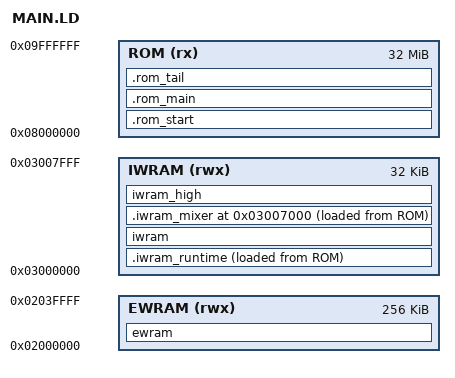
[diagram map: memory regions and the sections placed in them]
OUTPUT_ARCH(arm)
ENTRY(Entry_080003c0)
INCLUDE "games/THE BROKEN SEAL/CONSTANTS.LD"

MEMORY
{
    EWRAM (rwx) : ORIGIN = 0x2000000, LENGTH = 256K
    IWRAM (rwx) : ORIGIN = 0x3000000, LENGTH = 32K
    ROM    (rx) : ORIGIN = 0x8000000, LENGTH = 32M
}

SECTIONS
{
    ewram (NOLOAD) : { "*/recon/tbs/sym_ewram.o"(.sym_ewram) } > EWRAM
    .rom_start :
    {
        "*/recon/tbs/unidentified.o"(.unidentified.08000000)
        "*/games/THE BROKEN SEAL/SRC/SYSTEM/FAR_CALL/RUNTIME.o"(.text .rodata .data .padding)
        "*/games/THE BROKEN SEAL/SRC/SYSTEM/ENTRY.o"(.text .rodata .data .padding)
        "*/games/THE BROKEN SEAL/SRC/SOUND/DRIVER/RESAMPLER_KERNELS.o"(.text .rodata .data .padding)
        "*/games/THE BROKEN SEAL/SRC/SOUND/DRIVER/RESAMPLER_KERNELS_PAD.o"(.text .rodata .data .padding)
        "*/games/THE BROKEN SEAL/SRC/SOUND/DRIVER/RESAMPLER_KERNELS_1.o"(.text .rodata .data .padding)
        "*/games/THE BROKEN SEAL/SRC/SOUND/DRIVER/RESAMPLER_KERNELS_PAD_1.o"(.text .rodata .data .padding)
        "*/games/THE BROKEN SEAL/SRC/SOUND/DRIVER/RESAMPLER_KERNELS_2.o"(.text .rodata .data .padding)
        "*/games/THE BROKEN SEAL/SRC/SOUND/DRIVER/RESAMPLER_KERNELS_PAD_2.o"(.text .rodata .data .padding)
        "*/games/THE BROKEN SEAL/SRC/SOUND/DRIVER/CHANNEL_UPDATE_ENTRY.o"(.text .rodata .data .padding)
    } > ROM
    /* Startup copies this resident module bank to IWRAM with DMA3. */
    .iwram_runtime :
    {
        "*/games/THE BROKEN SEAL/SRC/SYSTEM/RUNTIME.o"(.text .rodata .data .padding)
        "*/games/THE BROKEN SEAL/SRC/SYSTEM/RUNTIME_IRQ_TABLE.o"(.text .rodata .data .padding)
        "*/games/THE BROKEN SEAL/SRC/SYSTEM/RUNTIME_MUL_Q16_IP.o"(.text .rodata .data .padding)
        "*/games/THE BROKEN SEAL/SRC/SYSTEM/RUNTIME_MUL_Q16.o"(.text .rodata .data .padding)
        "*/games/THE BROKEN SEAL/SRC/SYSTEM/RUNTIME_RATIO_Q14.o"(.text .rodata .data .padding)
        "*/games/THE BROKEN SEAL/SRC/SYSTEM/RUNTIME_MATH.o"(.text .rodata .data .padding)
        "*/games/THE BROKEN SEAL/SRC/SYSTEM/RUNTIME_TRANSFORM.o"(.text .rodata .data .padding)
        "*/games/THE BROKEN SEAL/SRC/SYSTEM/RUNTIME_MATRIX.o"(.text .rodata .data .padding)
        "*/games/THE BROKEN SEAL/SRC/SYSTEM/RUNTIME_DIVIDE.o"(.text .rodata .data .padding)
        "*/games/THE BROKEN SEAL/SRC/SYSTEM/RUNTIME_DECOMPRESS.o"(.text .rodata .data .padding)
        "*/games/THE BROKEN SEAL/SRC/SYSTEM/RUNTIME_MIX.o"(.text .rodata .data .padding)
        "*/games/THE BROKEN SEAL/SRC/SYSTEM/RUNTIME_MIX_STATE.o"(.text .rodata .data .padding)
        "*/games/THE BROKEN SEAL/SRC/SYSTEM/RUNTIME_MIX_INTERPOLATE.o"(.text .rodata .data .padding)
        "*/games/THE BROKEN SEAL/SRC/SYSTEM/RUNTIME_MIX_SAVE.o"(.text .rodata .data .padding)
        "*/games/THE BROKEN SEAL/SRC/SYSTEM/RUNTIME_MIX_CHANNEL.o"(.text .rodata .data .padding)
        "*/games/THE BROKEN SEAL/SRC/SYSTEM/RUNTIME_MIX_MASK.o"(.text .rodata .data .padding)
        "*/games/THE BROKEN SEAL/SRC/SYSTEM/RUNTIME_MIX_RENDER.o"(.text .rodata .data .padding)
        "*/games/THE BROKEN SEAL/SRC/SYSTEM/RUNTIME_MIX_WORKSPACE.o"(.text .rodata .data .padding)
        "*/games/THE BROKEN SEAL/SRC/SYSTEM/RUNTIME_COPY_WORDS.o"(.text .rodata .data .padding)
    } > IWRAM AT>ROM
    iwram (NOLOAD) : { "*/recon/tbs/sym_iwram.o"(.sym_iwram) } > IWRAM
    .rom_main :
    {
        "*/games/THE BROKEN SEAL/SRC/SYSTEM/RESOURCE/DECODE_BYTE_LZ.o"(.text .rodata .data .padding)
        "*/games/THE BROKEN SEAL/SRC/GRAPHICS/RENDER/BUILD_OAM_LIST.o"(.text .rodata .data .padding)
        "*/games/THE BROKEN SEAL/SRC/GRAPHICS/PALETTE/COLOR_BACKUP_KERNELS.o"(.text .rodata .data .padding)
        "*/games/THE BROKEN SEAL/SRC/GRAPHICS/PALETTE/COLOR_KERNELS.o"(.text .rodata .data .padding)
        "*/games/THE BROKEN SEAL/SRC/SYSTEM/RESOURCE/DECODE_HALFWORD_LZ.o"(.text .rodata .data .padding)
        "*/games/THE BROKEN SEAL/SRC/SYSTEM/IWRAM_ENTRY.o"(.text)
        "*/games/THE BROKEN SEAL/SRC/LIB/TRIG.o"(.text .rodata .data .padding)
        "*/games/THE BROKEN SEAL/SRC/LIB/SINE_TABLE.o"(.text .rodata .data .padding)
        "*/games/THE BROKEN SEAL/SRC/SYSTEM/RESOURCE/DECODE_01.o"(.text .rodata .data .padding)
        "*/games/THE BROKEN SEAL/SRC/SYSTEM/RESOURCE/DECODE_2.o"(.text .rodata .data .padding)
        "*/games/THE BROKEN SEAL/SRC/SYSTEM/RESOURCE/DECODE_2_NIBBLES.o"(.text .rodata .data .padding)
        "*/games/THE BROKEN SEAL/SRC/SYSTEM/RESOURCE/DECODE_2_LOOP.o"(.text .rodata .data .padding)
        "*/games/THE BROKEN SEAL/SRC/SYSTEM/RESOURCE/EXECUTE_TRANSFER.o"(.text .rodata .data .padding)
        "*/games/THE BROKEN SEAL/SRC/SYSTEM/RESOURCE/PATCH_THUMB_BRANCH.o"(.text .rodata .data .padding)
        "*/games/THE BROKEN SEAL/SRC/SYSTEM/MEMORY/RELEASE_HEAP_BLOCK.o"(.text .rodata .data .padding)
        "*/games/THE BROKEN SEAL/SRC/SYSTEM/INITIALIZE.o"(.text)
        "*/games/THE BROKEN SEAL/SRC/SYSTEM/SCHEDULER/IDLE_FOREVER.o"(.text)
        "*/games/THE BROKEN SEAL/SRC/SYSTEM/RESOURCE/RESOURCE.o"(.text)
        "*/recon/tbs/raw/0800300a.o"(.text .rodata .data .padding)
        "*/games/THE BROKEN SEAL/SRC/SYSTEM/INSTALL_IWRAM_AND_IRQS.o"(.text)
        "*/games/THE BROKEN SEAL/SRC/SYSTEM/SYSTEM.o"(.text)
        "*/games/THE BROKEN SEAL/SRC/SYSTEM/UPDATE_KEY_REPEAT_AND_DIRECTION.o"(.text)
        "*/games/THE BROKEN SEAL/SRC/SYSTEM/SYSTEM2.o"(.text)
        "*/games/THE BROKEN SEAL/SRC/SYSTEM/IO.o"(.text)
        "*/games/THE BROKEN SEAL/SRC/GRAPHICS/DISPLAY/DISPLAY3.o"(.text)
        "*/games/THE BROKEN SEAL/SRC/SYSTEM/SCHEDULER/SCHEDULER.o"(.text)
        "*/recon/tbs/raw/080046c2.o"(.text .rodata .data .padding)
        "*/games/THE BROKEN SEAL/SRC/DEBUG/DEBUG.o"(.text)
        "*/games/THE BROKEN SEAL/SRC/SYSTEM/MEMORY/MEMORY.o"(.text)
        "*/recon/tbs/raw/080049aa.o"(.text .rodata .data .padding)
        "*/games/THE BROKEN SEAL/SRC/GRAPHICS/RENDER/RENDER.o"(.text)
        "*/recon/tbs/raw/08004fe4.o"(.text .rodata .data .padding)
        "*/games/THE BROKEN SEAL/SRC/GRAPHICS/PALETTE/PALETTE8.o"(.text)
        "*/recon/tbs/raw/080056cc.o"(.text .rodata .data .padding)
        "*/recon/tbs/raw/0800580e.o"(.text .rodata .data .padding)
        "*/games/THE BROKEN SEAL/SRC/SYSTEM/SAVE/STATE.o"(.text)
        "*/recon/tbs/raw/08005d0e.o"(.text .rodata .data .padding)
        "*/games/THE BROKEN SEAL/SRC/SYSTEM/LINK/SERIAL_INITIALIZE.o"(.text)
        "*/recon/tbs/raw/08005e6e.o"(.text .rodata .data .padding)
        "*/games/THE BROKEN SEAL/SRC/SYSTEM/LINK/SIO_TIME.o"(.text)
        "*/recon/tbs/raw/08005ede.o"(.text .rodata .data .padding)
        "*/games/THE BROKEN SEAL/SRC/SYSTEM/LINK/SERIAL_POLL_AND_TRANSFER.o"(.text)
        "*/recon/tbs/raw/08005fca.o"(.text .rodata .data .padding)
        "*/games/THE BROKEN SEAL/SRC/SYSTEM/LINK/SERIAL_POLL_STATUS.o"(.text)
        "*/recon/tbs/raw/08006086.o"(.text .rodata .data .padding)
        "*/games/THE BROKEN SEAL/SRC/SYSTEM/LINK/SIO_XCHG.o"(.text)
        "*/recon/tbs/raw/0800615c.o"(.text .rodata .data .padding)
        "*/games/THE BROKEN SEAL/SRC/SYSTEM/LINK/SIO_INTR.o"(.text)
        "*/recon/tbs/raw/08006408.o"(.text .rodata .data .padding)
        "*/games/THE BROKEN SEAL/SRC/SYSTEM/LINK/LINK.o"(.text)
        "*/recon/tbs/raw/0800655c.o"(.text .rodata .data .padding)
        "*/games/THE BROKEN SEAL/SRC/SYSTEM/LINK/SERIAL_TEST.o"(.text)
        "*/games/THE BROKEN SEAL/SRC/SYSTEM/CPU_SET.o"(.text .rodata .data .padding)
        "*/recon/tbs/raw/0800686e.o"(.text .rodata .data .padding)
        "*/games/THE BROKEN SEAL/SRC/SYSTEM/SOUND_VSYNC_ON.o"(.text .rodata .data .padding)
        "*/recon/tbs/raw/08006876.o"(.text .rodata .data .padding)
        "*/games/COMMON/SRC/SYSTEM/SAVE/READ_FLASH_ID.o"(.text)
        "*/recon/tbs/raw/0800690e.o"(.text .rodata .data .padding)
        "*/games/COMMON/SRC/SYSTEM/SAVE/IDENTIFY_FLASH.o"(.text)
        "*/games/COMMON/SRC/SYSTEM/SAVE/FLASH_TIMER_INTERRUPT.o"(.text)
        "*/games/COMMON/SRC/SYSTEM/SAVE/START_FLASH_TIMER.o"(.text)
        "*/games/COMMON/SRC/SYSTEM/SAVE/FLASH_READ_ROUTINES.o"(.text)
        "*/games/COMMON/SRC/SYSTEM/SAVE/READ_FLASH_CORE.o"(.text)
        "*/recon/tbs/raw/08006ba6.o"(.text .rodata .data .padding)
        "*/games/COMMON/SRC/SYSTEM/SAVE/READ_FLASH.o"(.text)
        "*/games/COMMON/SRC/SYSTEM/SAVE/FLASH_VERIFY.o"(.text)
        "*/recon/tbs/raw/08006c66.o"(.text .rodata .data .padding)
        "*/games/COMMON/SRC/SYSTEM/SAVE/VERIFY_FLASH_SECTOR.o"(.text)
        "*/games/COMMON/SRC/SYSTEM/SAVE/ERASE_FLASH_CHIP.o"(.text)
        "*/games/COMMON/SRC/SYSTEM/SAVE/ERASE_FLASH_SECTOR.o"(.text)
        "*/games/COMMON/SRC/SYSTEM/SAVE/FLASH_PROGRAM_BYTE.o"(.text)
        "*/games/COMMON/SRC/SYSTEM/SAVE/PROGRAM_FLASH_SECTOR_WITH_ERASE_RETRY.o"(.text)
        "*/games/COMMON/SRC/SYSTEM/SAVE/FLASH_ERASE_VERIFY.o"(.text)
        "*/recon/tbs/raw/08006f6a.o"(.text .rodata .data .padding)
        "*/games/THE BROKEN SEAL/SRC/SYSTEM/SAVE/FLASH_VERIFY_CALLBACK.o"(.text)
        "*/games/COMMON/SRC/SYSTEM/SAVE/PROGRAM_FLASH_SECTOR.o"(.text)
        "*/games/COMMON/SRC/SYSTEM/SAVE/ERASE_ATMEL_FLASH_CHIP.o"(.text)
        "*/games/COMMON/SRC/SYSTEM/SAVE/ERASE_ATMEL_FLASH_SECTOR.o"(.text)
        "*/games/COMMON/SRC/SYSTEM/SAVE/ERASE_ATMEL_FLASH_BLOCK.o"(.text)
        "*/games/COMMON/SRC/SYSTEM/SAVE/PROGRAM_ATMEL_FLASH_SECTOR.o"(.text)
        "*/games/COMMON/SRC/SYSTEM/SAVE/PROGRAM_ATMEL_FLASH_BLOCK.o"(.text)
        "*libgcc.a:_call_via_rX.o"(.text)
        "*/recon/tbs/unidentified.o"(.unidentified.08007320)
        "*/games/THE BROKEN SEAL/SRC/LIB/Q16_DOT_PRODUCT.o"(.text .rodata .data .padding)
        "*/recon/tbs/unidentified.o"(.unidentified.080079b0)
        "*/games/COMMON/SRC/SYSTEM/SAVE/READ_FLASH_ID.o"(.rodata)
        "*/games/COMMON/SRC/SYSTEM/SAVE/IDENTIFY_FLASH.o"(.rodata)
        "*/games/COMMON/SRC/SYSTEM/SAVE/FLASH_TIMER_INTERRUPT.o"(.rodata)
        "*/games/COMMON/SRC/SYSTEM/SAVE/START_FLASH_TIMER.o"(.rodata)
        "*/games/COMMON/SRC/SYSTEM/SAVE/FLASH_READ_ROUTINES.o"(.rodata)
        "*/games/COMMON/SRC/SYSTEM/SAVE/READ_FLASH_CORE.o"(.rodata)
        "*/games/COMMON/SRC/SYSTEM/SAVE/FLASH_VERIFY.o"(.rodata)
        "*/games/COMMON/SRC/SYSTEM/SAVE/FLASH_ERASE_VERIFY.o"(.rodata)
        "*/games/THE BROKEN SEAL/SRC/SYSTEM/SAVE/FLASH_VERIFY_CALLBACK.o"(.rodata)
        "*/games/THE BROKEN SEAL/SRC/SYSTEM/SAVE/SAVE2.o"(.rodata)
        "*/games/THE BROKEN SEAL/SRC/SYSTEM/SAVE/SAVE3.o"(.rodata)
        "*/games/THE BROKEN SEAL/SRC/SYSTEM/SAVE/SAVE.o"(.rodata)
        "*/recon/tbs/unidentified.o"(.unidentified.08007a68)
        "*/games/COMMON/SRC/SYSTEM/SAVE/READ_FLASH.o"(.rodata)
        "*/games/COMMON/SRC/SYSTEM/SAVE/VERIFY_FLASH_SECTOR.o"(.rodata)
        "*/recon/tbs/unidentified.o"(.unidentified.08007aa4)
        "*/games/COMMON/SRC/SYSTEM/SAVE/ERASE_FLASH_CHIP.o"(.rodata)
        "*/games/COMMON/SRC/SYSTEM/SAVE/ERASE_FLASH_SECTOR.o"(.rodata)
        "*/games/COMMON/SRC/SYSTEM/SAVE/FLASH_PROGRAM_BYTE.o"(.rodata)
        "*/games/COMMON/SRC/SYSTEM/SAVE/PROGRAM_FLASH_SECTOR_WITH_ERASE_RETRY.o"(.rodata)
        "*/recon/tbs/unidentified.o"(.unidentified.08007b38)
        "*/games/COMMON/SRC/SYSTEM/SAVE/PROGRAM_FLASH_SECTOR.o"(.rodata)
        "*/recon/tbs/unidentified.o"(.unidentified.08007bcc)
        "*/games/COMMON/SRC/SYSTEM/SAVE/ERASE_ATMEL_FLASH_CHIP.o"(.rodata)
        "*/games/COMMON/SRC/SYSTEM/SAVE/ERASE_ATMEL_FLASH_SECTOR.o"(.rodata)
        "*/games/COMMON/SRC/SYSTEM/SAVE/ERASE_ATMEL_FLASH_BLOCK.o"(.rodata)
        "*/games/COMMON/SRC/SYSTEM/SAVE/PROGRAM_ATMEL_FLASH_SECTOR.o"(.rodata)
        "*/games/COMMON/SRC/SYSTEM/SAVE/PROGRAM_ATMEL_FLASH_BLOCK.o"(.rodata)
        "*/recon/tbs/unidentified.o"(.unidentified.08007c64)
        "*/games/THE BROKEN SEAL/SRC/SYSTEM/FAR_CALL/FIELD.o"(.text .rodata .data .padding)
        "*/recon/tbs/unidentified.o"(.unidentified.080092b8)
        "*/games/THE BROKEN SEAL/SRC/GRAPHICS/RENDER/DECODE.o"(.text .rodata .data .padding)
        "*/games/THE BROKEN SEAL/SRC/GRAPHICS/RENDER/DECODE_DATA.o"(.text .rodata .data .padding)
        "*/games/THE BROKEN SEAL/SRC/GRAPHICS/TILE/DRAW_MAP.o"(.text .rodata .data .padding)
        "*/recon/tbs/raw/0800a0f8.o"(.text .rodata .data .padding)
        "*/games/THE BROKEN SEAL/SRC/GRAPHICS/TILE/CONVERT_MAP.o"(.text .rodata .data .padding)
        "*/games/THE BROKEN SEAL/SRC/GRAPHICS/TILE/COPY_STRIDED.o"(.text .rodata .data .padding)
        "*/recon/tbs/raw/0800a494.o"(.text .rodata .data .padding)
        "*/games/THE BROKEN SEAL/SRC/SYSTEM/RESOURCE/DECOMPRESS_LZ.o"(.text)
        "*/recon/tbs/raw/0800aa0c.o"(.text .rodata .data .padding)
        "*/games/THE BROKEN SEAL/SRC/GRAPHICS/RENDER/PLACE_SPRITE_PART_PAIR.o"(.text)
        "*/recon/tbs/raw/0800b166.o"(.text .rodata .data .padding)
        "*/games/THE BROKEN SEAL/SRC/GRAPHICS/RENDER/PLACE_PROJECTED_SPRITE.o"(.text)
        "*/recon/tbs/raw/0800b682.o"(.text .rodata .data .padding)
        "*/games/THE BROKEN SEAL/SRC/FIELD/COMMON/OBJECT/GROUP_SET_CHILD_VALUE_UNLESS_FIFTEEN.o"(.text)
        "*/recon/tbs/raw/0800b6b8.o"(.text .rodata .data .padding)
        "*/games/THE BROKEN SEAL/SRC/SYSTEM/RESOURCE/RESOURCE3.o"(.text)
        "*/recon/tbs/raw/0800bc46.o"(.text .rodata .data .padding)
        "*/games/THE BROKEN SEAL/SRC/SYSTEM/RESOURCE/OBJECT.o"(.text)
        "*/games/COMMON/SRC/SYSTEM/RESOURCE/METADATA_SUM_COMMAND_LENGTHS.o"(.text)
        "*/recon/tbs/raw/0800be6e.o"(.text .rodata .data .padding)
        "*/games/THE BROKEN SEAL/SRC/FIELD/COMMON/MAP/MAP8.o"(.text)
        "*/games/THE BROKEN SEAL/SRC/FIELD/COMMON/OBJECT/OBJECT.o"(.text)
        "*/recon/tbs/raw/0800ca42.o"(.text .rodata .data .padding)
        "*/games/COMMON/SRC/FIELD/COMMON/SCRIPT/OPERANDS_CLEAR_BYTE54.o"(.text)
        "*/recon/tbs/raw/0800ca56.o"(.text .rodata .data .padding)
        "*/games/COMMON/SRC/FIELD/COMMON/SCRIPT/OPERANDS_SET_BYTE54.o"(.text)
        "*/recon/tbs/raw/0800ca6a.o"(.text .rodata .data .padding)
        "*/games/THE BROKEN SEAL/SRC/FIELD/COMMON/OBJECT/OBJECT13.o"(.text)
        "*/recon/tbs/raw/0800caca.o"(.text .rodata .data .padding)
        "*/recon/tbs/raw/0800cacc.o"(.text .rodata .data .padding)
        "*/games/COMMON/SRC/FIELD/COMMON/OBJECT/MOTION_SET_POSITION_AND_RESET_MOTION.o"(.text)
        "*/recon/tbs/raw/0800d14a.o"(.text .rodata .data .padding)
        "*/games/THE BROKEN SEAL/SRC/FIELD/COMMON/OBJECT/OBJECT14.o"(.text)
        "*/recon/tbs/raw/0800daf0.o"(.text .rodata .data .padding)
        "*/games/THE BROKEN SEAL/SRC/FIELD/COMMON/OBJECT/MOTION_AIM_APPROACH_LINKED_OBJECT.o"(.text)
        "*/recon/tbs/raw/0800dd70.o"(.text .rodata .data .padding)
        "*/recon/tbs/raw/0800df04.o"(.text .rodata .data .padding)
        "*/games/THE BROKEN SEAL/SRC/FIELD/COMMON/SCRIPT/SCRIPT.o"(.text)
        "*/recon/tbs/raw/0800ebec.o"(.text .rodata .data .padding)
        "*/games/THE BROKEN SEAL/SRC/FIELD/COMMON/FIELD.o"(.text)
        "*/games/COMMON/SRC/GRAPHICS/TILE/DECODE_STAGED_BUFFER.o"(.text)
        "*/games/THE BROKEN SEAL/SRC/GRAPHICS/TILE/TILE2.o"(.text)
        "*/recon/tbs/raw/0800fb38.o"(.text .rodata .data .padding)
        "*/games/THE BROKEN SEAL/SRC/FIELD/COMMON/MAP/MAP.o"(.text)
        "*/games/THE BROKEN SEAL/SRC/FIELD/COMMON/MAP/SET_CAMERA_CENTER.o"(.text)
        "*/recon/tbs/raw/08010424.o"(.text .rodata .data .padding)
        "*/recon/tbs/raw/08010560.o"(.text .rodata .data .padding)
        "*/recon/tbs/raw/080105d4.o"(.text .rodata .data .padding)
        "*/games/THE BROKEN SEAL/SRC/FIELD/COMMON/MAP/COPY_CELL_ATTRIBUTE_RECT.o"(.text)
        "*/recon/tbs/raw/08010788.o"(.text .rodata .data .padding)
        "*/games/THE BROKEN SEAL/SRC/FIELD/COMMON/MAP/SET_WORK_FLAG_BITS9_11.o"(.text)
        "*/recon/tbs/raw/080108e4.o"(.text .rodata .data .padding)
        "*/games/THE BROKEN SEAL/SRC/FIELD/COMMON/MAP/MAP6.o"(.text)
        "*/recon/tbs/raw/08010ff0.o"(.text .rodata .data .padding)
        "*/games/THE BROKEN SEAL/SRC/FIELD/WORLD_MAP/MAP4.o"(.text)
        "*/recon/tbs/raw/080113e4.o"(.text .rodata .data .padding)
        "*/recon/tbs/raw/080114a0.o"(.text .rodata .data .padding)
        "*/games/THE BROKEN SEAL/SRC/FIELD/COMMON/MAP/MAP2.o"(.text)
        "*/games/THE BROKEN SEAL/SRC/FIELD/COMMON/MAP/MAP3.o"(.text)
        "*/games/THE BROKEN SEAL/SRC/GRAPHICS/DISPLAY/DISPLAY4.o"(.text)
        "*/games/THE BROKEN SEAL/SRC/SYSTEM/SCHEDULER/SCHEDULE_CALLBACK_B_AFTER_FRAMES.o"(.text)
        "*/recon/tbs/raw/08011bf4.o"(.text .rodata .data .padding)
        "*/games/THE BROKEN SEAL/SRC/LIB/CURVE.o"(.text)
        "*/recon/tbs/raw/08011f52.o"(.text .rodata .data .padding)
        "*/recon/tbs/raw/08011f54.o"(.text .rodata .data .padding)
        "*/games/THE BROKEN SEAL/SRC/FIELD/COMMON/MAP/MAP4.o"(.text)
        "*/recon/tbs/raw/080120dc.o"(.text .rodata .data .padding)
        "*/games/THE BROKEN SEAL/SRC/FIELD/COMMON/MAP/MAP5.o"(.text)
        "*/recon/tbs/raw/08012518.o"(.text .rodata .data .padding)
        "*/games/THE BROKEN SEAL/SRC/GRAPHICS/TILE/FIND_NEXT_NUMBER_WITH_METADATA.o"(.text)
        "*/recon/tbs/raw/08012b2c.o"(.text .rodata .data .padding)
        "*/games/THE BROKEN SEAL/SRC/GRAPHICS/TILE/GRID_COLUMN.o"(.text)
        "*/games/THE BROKEN SEAL/SRC/BATTLE/PARTY/PLACE_ACTORS_BY_FORMATION_KIND.o"(.text)
        "*/recon/tbs/unidentified.o"(.unidentified.08012f20)
        "*/games/THE BROKEN SEAL/SRC/SYSTEM/FAR_CALL/WINDOW.o"(.text .rodata .data .padding)
        "*/games/THE BROKEN SEAL/SRC/GRAPHICS/TEXT/DECODE_SYMBOL.o"(.text .rodata .data .padding)
        "*/games/THE BROKEN SEAL/SRC/GRAPHICS/TEXT/LOOKUP_SYMBOL.o"(.text .rodata .data .padding)
        "*/recon/tbs/raw/080155d0.o"(.text .rodata .data .padding)
        "*/recon/tbs/raw/080158e8.o"(.text .rodata .data .padding)
        "*/games/THE BROKEN SEAL/SRC/GRAPHICS/TILE/DECOMPRESS_4BPP.o"(.text .rodata .data .padding)
        "*/games/THE BROKEN SEAL/SRC/GRAPHICS/TILE/DECOMPRESS_4BPP_NIBBLES.o"(.text .rodata .data .padding)
        "*/games/THE BROKEN SEAL/SRC/GRAPHICS/TILE/DECOMPRESS_4BPP_LOOP.o"(.text .rodata .data .padding)
        "*/games/THE BROKEN SEAL/SRC/GRAPHICS/TILE/EXPAND_MASKED.o"(.text .rodata .data .padding)
        "*/games/THE BROKEN SEAL/SRC/GRAPHICS/TILE/EXPAND_MASKED_MASKS.o"(.text .rodata .data .padding)
        "*/games/THE BROKEN SEAL/SRC/GRAPHICS/TILE/EXPAND_OPAQUE.o"(.text .rodata .data .padding)
        "*/games/THE BROKEN SEAL/SRC/GRAPHICS/TILE/EXPAND_OPAQUE_MASKS.o"(.text .rodata .data .padding)
        "*/games/THE BROKEN SEAL/SRC/GRAPHICS/RENDER/OUTPUT_ACQUIRE_FREE.o"(.text)
        "*/games/THE BROKEN SEAL/SRC/GRAPHICS/RENDER/RENDER5.o"(.text)
        "*/games/THE BROKEN SEAL/SRC/GRAPHICS/RENDER/UPLOAD_DIRTY_BLOCKS.o"(.text)
        "*/games/THE BROKEN SEAL/SRC/GRAPHICS/WINDOW/WINDOW.o"(.text)
        "*/recon/tbs/raw/080164d2.o"(.text .rodata .data .padding)
        "*/recon/tbs/raw/080164d4.o"(.text .rodata .data .padding)
        "*/games/THE BROKEN SEAL/SRC/GRAPHICS/RENDER/OUTPUT_LIST.o"(.text)
        "*/games/THE BROKEN SEAL/SRC/GRAPHICS/RENDER/RENDER3.o"(.text)
        "*/recon/tbs/raw/080167de.o"(.text .rodata .data .padding)
        "*/recon/tbs/raw/080167e0.o"(.text .rodata .data .padding)
        "*/games/THE BROKEN SEAL/SRC/GRAPHICS/WINDOW/RUNTIME_PROCESS_RENDER_CHANNELS.o"(.text)
        "*/recon/tbs/raw/080168f4.o"(.text .rodata .data .padding)
        "*/games/THE BROKEN SEAL/SRC/GRAPHICS/WINDOW/WINDOW2.o"(.text)
        "*/recon/tbs/raw/08017362.o"(.text .rodata .data .padding)
        "*/games/THE BROKEN SEAL/SRC/GRAPHICS/RENDER/IS_COMPLETE.o"(.text)
        "*/games/THE BROKEN SEAL/SRC/GRAPHICS/WINDOW/RUNTIME_COUNTERS.o"(.text)
        "*/games/THE BROKEN SEAL/SRC/GRAPHICS/TEXT/MESSAGE.o"(.text)
        "*/games/THE BROKEN SEAL/SRC/GRAPHICS/TEXT/TEXT4.o"(.text)
        "*/recon/tbs/raw/080178ae.o"(.text .rodata .data .padding)
        "*/games/THE BROKEN SEAL/SRC/GRAPHICS/TEXT/RENDER_GLYPH_PAIR.o"(.text)
        "*/games/COMMON/SRC/GRAPHICS/TEXT/GET_WIDE_STRING_WIDTH.o"(.text)
        "*/games/THE BROKEN SEAL/SRC/GRAPHICS/TEXT/RENDER_WIDE_STRING_AT_OFFSET.o"(.text)
        "*/games/THE BROKEN SEAL/SRC/GRAPHICS/TEXT/RENDER_GLYPH_TILE_AT_WORK_OFFSET.o"(.text)
        "*/recon/tbs/raw/08017c8a.o"(.text .rodata .data .padding)
        "*/games/THE BROKEN SEAL/SRC/GRAPHICS/TEXT/RENDER_WIDE_STRING_IN_WINDOW.o"(.text)
        "*/games/THE BROKEN SEAL/SRC/GRAPHICS/TEXT/FORMAT_NUMBER.o"(.text)
        "*/recon/tbs/raw/08018038.o"(.text .rodata .data .padding)
        "*/games/THE BROKEN SEAL/SRC/GRAPHICS/WINDOW/WINDOW3.o"(.text)
        "*/recon/tbs/raw/08018850.o"(.text .rodata .data .padding)
        "*/recon/tbs/raw/08018a50.o"(.text .rodata .data .padding)
        "*/recon/tbs/raw/08018cac.o"(.text .rodata .data .padding)
        "*/games/THE BROKEN SEAL/SRC/GRAPHICS/WINDOW/PUT_GLYPH.o"(.text)
        "*/games/THE BROKEN SEAL/SRC/GRAPHICS/WINDOW/SET_TILEMAP_ENTRY.o"(.text)
        "*/recon/tbs/raw/080191cc.o"(.text .rodata .data .padding)
        "*/games/COMMON/SRC/GRAPHICS/WINDOW/ADJUST_VALUE_WITHOUT_LIMIT.o"(.text)
        "*/games/THE BROKEN SEAL/SRC/GRAPHICS/TEXT/COPY_MESSAGE_STRING.o"(.text)
        "*/games/THE BROKEN SEAL/SRC/GRAPHICS/TEXT/DECODE_MESSAGE.o"(.text)
        "*/games/COMMON/SRC/SYSTEM/MEMORY/CLEAR_WORD_IF_SET.o"(.text)
        "*/games/THE BROKEN SEAL/SRC/GRAPHICS/WINDOW/WINDOW4.o"(.text)
        "*/games/THE BROKEN SEAL/SRC/GRAPHICS/TEXT/TEXT2.o"(.text)
        "*/recon/tbs/raw/08019bfc.o"(.text .rodata .data .padding)
        "*/games/THE BROKEN SEAL/SRC/GRAPHICS/WINDOW/WINDOW5.o"(.text)
        "*/games/THE BROKEN SEAL/SRC/GRAPHICS/WINDOW/RUNTIME_FINALIZE_ENTITY_MATCHING_LOCALIZED_ID.o"(.text)
        "*/games/THE BROKEN SEAL/SRC/GRAPHICS/RENDER/RENDER4.o"(.text)
        "*/recon/tbs/raw/08019fca.o"(.text .rodata .data .padding)
        "*/games/THE BROKEN SEAL/SRC/GRAPHICS/TILE/BUILD_ITEM_ICON_TILES.o"(.text)
        "*/recon/tbs/raw/0801a088.o"(.text .rodata .data .padding)
        "*/games/THE BROKEN SEAL/SRC/GRAPHICS/TILE/COPY_RESOURCE_TO_SLOT.o"(.text)
        "*/recon/tbs/raw/0801a2ea.o"(.text .rodata .data .padding)
        "*/games/THE BROKEN SEAL/SRC/GRAPHICS/RENDER/BUILD_PATTERN_TO_SLOT.o"(.text)
        "*/recon/tbs/raw/0801a32a.o"(.text .rodata .data .padding)
        "*/games/THE BROKEN SEAL/SRC/GRAPHICS/TILE/TILE.o"(.text)
        "*/recon/tbs/raw/0801a402.o"(.text .rodata .data .padding)
        "*/games/THE BROKEN SEAL/SRC/GRAPHICS/GLYPH/GLYPH.o"(.text)
        "*/recon/tbs/raw/0801a90e.o"(.text .rodata .data .padding)
        "*/games/THE BROKEN SEAL/SRC/SYSTEM/RESOURCE/FIND_FREE_TRANSFER_ENTRY.o"(.text)
        "*/recon/tbs/raw/0801a98c.o"(.text .rodata .data .padding)
        "*/games/THE BROKEN SEAL/SRC/MENU/MENU.o"(.text)
        "*/recon/tbs/raw/0801b248.o"(.text .rodata .data .padding)
        "*/games/THE BROKEN SEAL/SRC/MENU/MENU2.o"(.text)
        "*/recon/tbs/raw/0801ba68.o"(.text .rodata .data .padding)
        "*/games/THE BROKEN SEAL/SRC/SYSTEM/RESOURCE/RESOURCE2.o"(.text)
        "*/recon/tbs/raw/0801be80.o"(.text .rodata .data .padding)
        "*/games/THE BROKEN SEAL/SRC/GRAPHICS/TEXT/RESOURCE.o"(.text)
        "*/recon/tbs/raw/0801c186.o"(.text .rodata .data .padding)
        "*/games/THE BROKEN SEAL/SRC/MENU/MENU13.o"(.text)
        "*/recon/tbs/raw/0801c2e2.o"(.text .rodata .data .padding)
        "*/games/THE BROKEN SEAL/SRC/GRAPHICS/WINDOW/RUNTIME_CLOSE_AND_RELEASE.o"(.text)
        "*/recon/tbs/raw/0801c2ee.o"(.text .rodata .data .padding)
        "*/games/THE BROKEN SEAL/SRC/GRAPHICS/WINDOW/WINDOW6.o"(.text)
        "*/games/THE BROKEN SEAL/SRC/GAME/PARTY/ADJUST_BYTE205_BY_DIRECTION.o"(.text)
        "*/recon/tbs/raw/0801c49c.o"(.text .rodata .data .padding)
        "*/games/THE BROKEN SEAL/SRC/FIELD/COMMON/OBJECT/OBJECT2.o"(.text)
        "*/recon/tbs/raw/0801c92e.o"(.text .rodata .data .padding)
        "*/games/THE BROKEN SEAL/SRC/GRAPHICS/WINDOW/WINDOW11.o"(.text)
        "*/recon/tbs/raw/0801c9c6.o"(.text .rodata .data .padding)
        "*/games/THE BROKEN SEAL/SRC/GRAPHICS/PALETTE/PALETTE.o"(.text)
        "*/recon/tbs/raw/0801cf46.o"(.text .rodata .data .padding)
        "*/games/THE BROKEN SEAL/SRC/MENU/MENU14.o"(.text)
        "*/games/THE BROKEN SEAL/SRC/MENU/MENU15.o"(.text)
        "*/games/THE BROKEN SEAL/SRC/MENU/MENU3.o"(.text)
        "*/recon/tbs/raw/0801d9d4.o"(.text .rodata .data .padding)
        "*/games/THE BROKEN SEAL/SRC/MENU/RUN_WORKSPACE_SELECTION_LOOP.o"(.text)
        "*/recon/tbs/raw/0801dd28.o"(.text .rodata .data .padding)
        "*/recon/tbs/raw/0801de5c.o"(.text .rodata .data .padding)
        "*/games/THE BROKEN SEAL/SRC/GRAPHICS/WINDOW/CLEAR_TILE_ATTRIBUTES_IN_RECT.o"(.text)
        "*/games/THE BROKEN SEAL/SRC/GRAPHICS/WINDOW/WINDOW12.o"(.text)
        "*/recon/tbs/raw/0801e41a.o"(.text .rodata .data .padding)
        "*/games/THE BROKEN SEAL/SRC/GRAPHICS/WINDOW/WINDOW7.o"(.text)
        "*/games/THE BROKEN SEAL/SRC/GRAPHICS/TEXT/RENDER.o"(.text)
        "*/games/THE BROKEN SEAL/SRC/GRAPHICS/RENDER/OUTPUT.o"(.text)
        "*/recon/tbs/raw/0801ec6a.o"(.text .rodata .data .padding)
        "*/games/THE BROKEN SEAL/SRC/FIELD/COMMON/OBJECT/OBJECT8.o"(.text)
        "*/games/COMMON/SRC/GRAPHICS/WINDOW/RUNTIME_SET_BYTE5_AND_RESET_HALFWORD_C.o"(.text)
        "*/games/THE BROKEN SEAL/SRC/GRAPHICS/WINDOW/RUNTIME_SET_BYTE15_INVERTED.o"(.text)
        "*/recon/tbs/raw/0801edea.o"(.text .rodata .data .padding)
        "*/games/THE BROKEN SEAL/SRC/GRAPHICS/WINDOW/WINDOW15.o"(.text)
        "*/recon/tbs/raw/0801ef68.o"(.text .rodata .data .padding)
        "*/recon/tbs/raw/0801f088.o"(.text .rodata .data .padding)
        "*/recon/tbs/raw/0801f200.o"(.text .rodata .data .padding)
        "*/games/THE BROKEN SEAL/SRC/SYSTEM/SAVE/SAVE2.o"(.text)
        "*/games/THE BROKEN SEAL/SRC/SYSTEM/SAVE/SAVE3.o"(.text)
        "*/games/COMMON/SRC/GRAPHICS/PALETTE/GLOW_UPDATE_SINE.o"(.text)
        "*/games/THE BROKEN SEAL/SRC/GRAPHICS/WINDOW/WINDOW13.o"(.text)
        "*/recon/tbs/raw/0801fe2a.o"(.text .rodata .data .padding)
        "*/games/THE BROKEN SEAL/SRC/MENU/MENU4.o"(.text)
        "*/games/COMMON/SRC/GRAPHICS/TEXT/DRAW_FOUR_NUMBERS_IN_ROW.o"(.text)
        "*/games/COMMON/SRC/MENU/DRAW_CHARACTER_SUMMARY.o"(.text)
        "*/recon/tbs/raw/08020244.o"(.text .rodata .data .padding)
        "*/games/THE BROKEN SEAL/SRC/SYSTEM/SAVE/SAVE.o"(.text)
        "*/games/THE BROKEN SEAL/SRC/GRAPHICS/WINDOW/WINDOW14.o"(.text)
        "*/recon/tbs/raw/08020bd6.o"(.text .rodata .data .padding)
        "*/recon/tbs/raw/08020bd8.o"(.text .rodata .data .padding)
        "*/games/THE BROKEN SEAL/SRC/MENU/PARTY/TALK_CHOICE.o"(.text)
        "*/games/THE BROKEN SEAL/SRC/GAME/PARTY/LOOKUP_CHARACTER_VALUE_BY_FLAG32.o"(.text)
        "*/recon/tbs/raw/08021390.o"(.text .rodata .data .padding)
        "*/games/THE BROKEN SEAL/SRC/GRAPHICS/RENDER/LOAD_PAIR.o"(.text)
        "*/recon/tbs/raw/080216b2.o"(.text .rodata .data .padding)
        "*/games/THE BROKEN SEAL/SRC/GRAPHICS/WINDOW/WINDOW16.o"(.text)
        "*/recon/tbs/raw/08021bc6.o"(.text .rodata .data .padding)
        "*/games/COMMON/SRC/GRAPHICS/WINDOW/GET_TABLE_WORD_ZERO.o"(.text)
        "*/games/THE BROKEN SEAL/SRC/GRAPHICS/WINDOW/RUN_COPIED_ROUTINE.o"(.text)
        "*/games/COMMON/SRC/SYSTEM/LINK/CREATE_COUNTDOWN_LABEL_WINDOW.o"(.text)
        "*/games/THE BROKEN SEAL/SRC/GRAPHICS/TEXT/TEXT5.o"(.text)
        "*/recon/tbs/raw/08021dfa.o"(.text .rodata .data .padding)
        "*/games/THE BROKEN SEAL/SRC/GRAPHICS/DISPLAY/DISPLAY.o"(.text)
        "*/recon/tbs/raw/08021e6a.o"(.text .rodata .data .padding)
        "*/recon/tbs/raw/08021e6c.o"(.text .rodata .data .padding)
        "*/games/THE BROKEN SEAL/SRC/GRAPHICS/WINDOW/SET_RECT_HIGHLIGHT.o"(.text)
        "*/recon/tbs/raw/0802281c.o"(.text .rodata .data .padding)
        "*/games/THE BROKEN SEAL/SRC/MENU/MENU16.o"(.text)
        "*/games/COMMON/SRC/GRAPHICS/RENDER/CREATE_OUTPUT_FROM_RESOURCE_SLOT.o"(.text)
        "*/recon/tbs/raw/08022a7a.o"(.text .rodata .data .padding)
        "*/recon/tbs/raw/08022a7c.o"(.text .rodata .data .padding)
        "*/recon/tbs/raw/08022b44.o"(.text .rodata .data .padding)
        "*/recon/tbs/raw/08023178.o"(.text .rodata .data .padding)
        "*/recon/tbs/raw/08023e70.o"(.text .rodata .data .padding)
        "*/recon/tbs/raw/08024934.o"(.text .rodata .data .padding)
        "*/games/COMMON/SRC/GAME/ITEM/CLASSIFY_USE_ABILITY.o"(.text)
        "*/recon/tbs/raw/080251d2.o"(.text .rodata .data .padding)
        "*/games/THE BROKEN SEAL/SRC/GRAPHICS/DISPLAY/COPY_TILE.o"(.text)
        "*/recon/tbs/raw/08025200.o"(.text .rodata .data .padding)
        "*/recon/tbs/raw/0802592c.o"(.text .rodata .data .padding)
        "*/recon/tbs/raw/08026080.o"(.text .rodata .data .padding)
        "*/games/THE BROKEN SEAL/SRC/SYSTEM/LINK/LINK2.o"(.text)
        "*/games/COMMON/SRC/BATTLE/CLASSIFY_ENTRY_KIND.o"(.text)
        "*/recon/tbs/raw/080270aa.o"(.text .rodata .data .padding)
        "*/games/THE BROKEN SEAL/SRC/BATTLE/DRAW_PARTY_PANELS_WITH_EMPTY_LIST.o"(.text)
        "*/games/THE BROKEN SEAL/SRC/GRAPHICS/TEXT/DRAW_DRAW_LOCALIZED_RESOURCE.o"(.text)
        "*/recon/tbs/raw/08027114.o"(.text .rodata .data .padding)
        "*/recon/tbs/raw/08028194.o"(.text .rodata .data .padding)
        "*/games/THE BROKEN SEAL/SRC/MENU/MENU17.o"(.text)
        "*/games/THE BROKEN SEAL/SRC/MENU/MENU7.o"(.text)
        "*/games/THE BROKEN SEAL/SRC/MENU/SELECTION.o"(.text)
        "*/games/THE BROKEN SEAL/SRC/MENU/SELECT_RESOURCE_LAYOUT.o"(.text)
        "*/games/THE BROKEN SEAL/SRC/MENU/CONFIRM_SELECTION.o"(.text)
        "*/games/COMMON/SRC/MENU/SELECT_ENTRY_20_TO_21.o"(.text)
        "*/recon/tbs/raw/08028eda.o"(.text .rodata .data .padding)
        "*/games/THE BROKEN SEAL/SRC/MENU/MENU11.o"(.text)
        "*/games/COMMON/SRC/MENU/RUN_SELECTION_WITH_CURSOR_OBJECT.o"(.text)
        "*/recon/tbs/raw/08029272.o"(.text .rodata .data .padding)
        "*/games/COMMON/SRC/GRAPHICS/TEXT/FORMAT_HEX.o"(.text)
        "*/games/THE BROKEN SEAL/SRC/MENU/MENU5.o"(.text)
        "*/recon/tbs/raw/080294d2.o"(.text .rodata .data .padding)
        "*/games/THE BROKEN SEAL/SRC/GAME/DJINN/SET_FOUND_FLAG_AND_ADD.o"(.text)
        "*/recon/tbs/raw/08029502.o"(.text .rodata .data .padding)
        "*/games/THE BROKEN SEAL/SRC/MENU/RUN_WORKSPACE_RESULT_LOOP.o"(.text)
        "*/recon/tbs/raw/08029554.o"(.text .rodata .data .padding)
        "*/recon/tbs/raw/0802977c.o"(.text .rodata .data .padding)
        "*/recon/tbs/unidentified.o"(.unidentified.08029910)
        "*/games/COMMON/SRC/GRAPHICS/FONT/TEXT.o"(.rodata)
        "*/recon/tbs/unidentified.o"(.unidentified.08033e24)
        "*/games/THE BROKEN SEAL/TEXT/MESSAGES.o"(.rodata)
        "*/recon/tbs/unidentified.o"(.unidentified.08073808)
        "*/games/THE BROKEN SEAL/SRC/SYSTEM/FAR_CALL/GAME.o"(.text .rodata .data .padding)
        "*/games/THE BROKEN SEAL/SRC/GAME/CHARACTER/CHARACTER.o"(.text)
        "*/recon/tbs/raw/08077d38.o"(.text .rodata .data .padding)
        "*/games/THE BROKEN SEAL/SRC/GAME/PARTY/PARTY2.o"(.text)
        "*/games/COMMON/SRC/GAME/CHARACTER/RATIOS_SECOND_INPUT.o"(.text)
        "*/recon/tbs/raw/080783a2.o"(.text .rodata .data .padding)
        "*/games/THE BROKEN SEAL/SRC/GAME/CHARACTER/VALUES.o"(.text)
        "*/recon/tbs/raw/08078412.o"(.text .rodata .data .padding)
        "*/games/COMMON/SRC/GAME/ITEM/DEFINITION.o"(.text)
        "*/recon/tbs/raw/0807847e.o"(.text .rodata .data .padding)
        "*/games/THE BROKEN SEAL/SRC/GAME/ITEM/GET_EQUIPMENT_GROUP.o"(.text)
        "*/recon/tbs/raw/080784ae.o"(.text .rodata .data .padding)
        "*/games/THE BROKEN SEAL/SRC/GAME/INVENTORY/INVENT2.o"(.text)
        "*/recon/tbs/raw/08078bf0.o"(.text .rodata .data .padding)
        "*/games/THE BROKEN SEAL/SRC/GAME/CHARACTER/RECORD.o"(.text)
        "*/games/THE BROKEN SEAL/SRC/GAME/CHARACTER/CHARACTER2.o"(.text)
        "*/games/COMMON/SRC/GAME/PARTY/ADVANCE_OWNER_COUNT_TO_TARGET.o"(.text)
        "*/games/THE BROKEN SEAL/SRC/GAME/FLAGS/TEST.o"(.text)
        "*/recon/tbs/raw/08079460.o"(.text .rodata .data .padding)
        "*/games/THE BROKEN SEAL/SRC/GAME/CHARACTER/CHARACTER3.o"(.text)
        "*/recon/tbs/raw/08079b24.o"(.text .rodata .data .padding)
        "*/games/THE BROKEN SEAL/SRC/BATTLE/RANDOM16.o"(.text)
        "*/recon/tbs/raw/08079d1a.o"(.text .rodata .data .padding)
        "*/games/THE BROKEN SEAL/SRC/GAME/DJINN/DJINN.o"(.text)
        "*/recon/tbs/raw/0807a626.o"(.text .rodata .data .padding)
        "*/games/THE BROKEN SEAL/SRC/GAME/INVENTORY/ADD_AND_EQUIP.o"(.text)
        "*/recon/tbs/raw/0807a664.o"(.text .rodata .data .padding)
        "*/games/THE BROKEN SEAL/SRC/GAME/INVENTORY/RESTORE_SNAPSHOT.o"(.text)
        "*/recon/tbs/unidentified.o"(.unidentified.0807a828)
        "*/games/THE BROKEN SEAL/SRC/SYSTEM/FAR_CALL/OBJECT.o"(.text .rodata .data .padding)
        "*/games/THE BROKEN SEAL/SRC/FIELD/COMMON/MAP/SELECT_GROUP_ENTRY.o"(.text)
        "*/recon/tbs/raw/0808a6e4.o"(.text .rodata .data .padding)
        "*/games/THE BROKEN SEAL/SRC/BATTLE/EFFECT/DATA_GET_RESOURCE_GROUP.o"(.text)
        "*/recon/tbs/raw/0808a8e4.o"(.text .rodata .data .padding)
        "*/games/THE BROKEN SEAL/SRC/BATTLE/EFFECT/DATA_LOAD_RESOURCE_GROUP.o"(.text)
        "*/games/THE BROKEN SEAL/SRC/FIELD/COMMON/FIELD4.o"(.text)
        "*/games/THE BROKEN SEAL/SRC/BATTLE/EFFECT/EFFECT24.o"(.text)
        "*/games/THE BROKEN SEAL/SRC/BATTLE/EFFECT/DATA_LOOKUP_ROUTINES.o"(.text)
        "*/games/THE BROKEN SEAL/SRC/GAME/PARTY/RESOLVE_TABLE_PAIR.o"(.text)
        "*/games/THE BROKEN SEAL/SRC/FIELD/COMMON/EVENT/GET_SPECIAL_VALUE.o"(.text)
        "*/games/THE BROKEN SEAL/SRC/BATTLE/EFFECT/EFFECT25.o"(.text)
        "*/recon/tbs/raw/0808b3ea.o"(.text .rodata .data .padding)
        "*/recon/tbs/raw/0808b3ec.o"(.text .rodata .data .padding)
        "*/games/THE BROKEN SEAL/SRC/FIELD/COMMON/OBJECT/OBJECT3.o"(.text)
        "*/games/THE BROKEN SEAL/SRC/BATTLE/EFFECT/EFFECT26.o"(.text)
        "*/games/THE BROKEN SEAL/SRC/FIELD/COMMON/OBJECT/OBJECT5.o"(.text)
        "*/recon/tbs/raw/0808bb2c.o"(.text .rodata .data .padding)
        "*/games/THE BROKEN SEAL/SRC/FIELD/COMMON/FIELD5.o"(.text)
        "*/games/THE BROKEN SEAL/SRC/BATTLE/PARTY/PARTY3.o"(.text)
        "*/recon/tbs/raw/0808c4f8.o"(.text .rodata .data .padding)
        "*/games/THE BROKEN SEAL/SRC/FIELD/COMMON/OBJECT/GET_TRIGGER_TILE_AHEAD_OF_CURRENT.o"(.text)
        "*/games/THE BROKEN SEAL/SRC/DEBUG/DEBUG2.o"(.text)
        "*/games/THE BROKEN SEAL/SRC/BATTLE/EFFECT/EFFECT27.o"(.text)
        "*/recon/tbs/raw/0808d9a4.o"(.text .rodata .data .padding)
        "*/games/THE BROKEN SEAL/SRC/BATTLE/EFFECT/EFFECT11.o"(.text)
        "*/recon/tbs/raw/0808e0ae.o"(.text .rodata .data .padding)
        "*/games/THE BROKEN SEAL/SRC/BATTLE/BATTLE6.o"(.text)
        "*/games/THE BROKEN SEAL/SRC/BATTLE/BATTLE7.o"(.text)
        "*/games/THE BROKEN SEAL/SRC/FIELD/COMMON/EFFECT/SLOTS.o"(.text)
        "*/recon/tbs/raw/0808ee0c.o"(.text .rodata .data .padding)
        "*/games/THE BROKEN SEAL/SRC/BATTLE/EFFECT/EFFECT28.o"(.text)
        "*/games/THE BROKEN SEAL/SRC/BATTLE/EFFECT/RANDOM_PARTICLE_SPAWN_AT_POSITION.o"(.text)
        "*/games/THE BROKEN SEAL/SRC/FIELD/COMMON/EFFECT/EFFECT.o"(.text)
        "*/recon/tbs/raw/0808f52c.o"(.text .rodata .data .padding)
        "*/games/THE BROKEN SEAL/SRC/GRAPHICS/DISPLAY/DISPLAY2.o"(.text)
        "*/recon/tbs/raw/0808fefc.o"(.text .rodata .data .padding)
        "*/games/THE BROKEN SEAL/SRC/GRAPHICS/DISPLAY/DISPLAY7.o"(.text)
        "*/recon/tbs/raw/08090582.o"(.text .rodata .data .padding)
        "*/games/THE BROKEN SEAL/SRC/GRAPHICS/DISPLAY/TRANSITION_UPDATE_SCANLINE.o"(.text)
        "*/games/THE BROKEN SEAL/SRC/GRAPHICS/PALETTE/PALETTE5.o"(.text)
        "*/recon/tbs/raw/08090a5c.o"(.text .rodata .data .padding)
        "*/games/THE BROKEN SEAL/SRC/BATTLE/EFFECT/EFFECT12.o"(.text)
        "*/recon/tbs/raw/080912b8.o"(.text .rodata .data .padding)
        "*/games/THE BROKEN SEAL/SRC/BATTLE/EFFECT/START_FADE_OVERLAY.o"(.text)
        "*/games/THE BROKEN SEAL/SRC/BATTLE/EFFECT/SETUP.o"(.text)
        "*/games/THE BROKEN SEAL/SRC/FIELD/COMMON/EVENT/EVENT.o"(.text)
        "*/games/THE BROKEN SEAL/SRC/GAME/PARTY/REMOVE_OWNER_RESTORED.o"(.text)
        "*/games/THE BROKEN SEAL/SRC/GAME/PARTY/CHECK_MEMBER_VALUE_TOTAL.o"(.text)
        "*/games/COMMON/SRC/GAME/INVENTORY/TRY_ADD_AND_RETURN_OWNER.o"(.text)
        "*/games/THE BROKEN SEAL/SRC/GAME/INVENTORY/INVENT.o"(.text)
        "*/games/COMMON/SRC/GRAPHICS/TEXT/DRAW_DRAW_QUANTITY_PAIR_WITH_CUE.o"(.text)
        "*/games/THE BROKEN SEAL/SRC/FIELD/COMMON/EVENT/EVENT2.o"(.text)
        "*/games/THE BROKEN SEAL/SRC/BATTLE/EFFECT/RESULT_REQUEST.o"(.text)
        "*/games/THE BROKEN SEAL/SRC/GAME/PARTY/SET_FIELDS_1CE_1D0.o"(.text)
        "*/games/THE BROKEN SEAL/SRC/FIELD/COMMON/EVENT/CELL_PAIRS.o"(.text)
        "*/games/THE BROKEN SEAL/SRC/FIELD/COMMON/OBJECT/OBJECT16.o"(.text)
        "*/games/THE BROKEN SEAL/SRC/FIELD/COMMON/OBJECT/OBJECT4.o"(.text)
        "*/games/THE BROKEN SEAL/SRC/FIELD/COMMON/OBJECT/OBJECT6.o"(.text)
        "*/recon/tbs/raw/08092b92.o"(.text .rodata .data .padding)
        "*/games/THE BROKEN SEAL/SRC/FIELD/COMMON/OBJECT/OBJECT9.o"(.text)
        "*/recon/tbs/raw/08092c40.o"(.text .rodata .data .padding)
        "*/games/THE BROKEN SEAL/SRC/BATTLE/PRESENTATION/RUN_ACTION_AND_WAIT.o"(.text)
        "*/games/THE BROKEN SEAL/SRC/BATTLE/BATTLE8.o"(.text)
        "*/recon/tbs/raw/080930ba.o"(.text .rodata .data .padding)
        "*/games/THE BROKEN SEAL/SRC/FIELD/COMMON/FIELD3.o"(.text)
        "*/recon/tbs/raw/08093166.o"(.text .rodata .data .padding)
        "*/games/THE BROKEN SEAL/SRC/FIELD/COMMON/EVENT/SHOW_VALUE_1D8_AT_POSITION.o"(.text)
        "*/games/COMMON/SRC/FIELD/COMMON/OBJECT/TABLE_RUN_IF_ACTIVE.o"(.text)
        "*/recon/tbs/raw/080931ea.o"(.text .rodata .data .padding)
        "*/games/THE BROKEN SEAL/SRC/BATTLE/BATTLE9.o"(.text)
        "*/games/THE BROKEN SEAL/SRC/FIELD/COMMON/OBJECT/ATTACH_WORK_TARGET_TO_OBJECT.o"(.text)
        "*/games/THE BROKEN SEAL/SRC/BATTLE/EFFECT/EFFECT29.o"(.text)
        "*/recon/tbs/raw/08093872.o"(.text .rodata .data .padding)
        "*/games/THE BROKEN SEAL/SRC/FIELD/COMMON/OBJECT/OBJECT17.o"(.text)
        "*/games/THE BROKEN SEAL/SRC/FIELD/COMMON/FIELD6.o"(.text)
        "*/recon/tbs/raw/08093fa0.o"(.text .rodata .data .padding)
        "*/games/THE BROKEN SEAL/SRC/FIELD/COMMON/OBJECT/OBJECT7.o"(.text)
        "*/recon/tbs/raw/080941de.o"(.text .rodata .data .padding)
        "*/recon/tbs/raw/080941e0.o"(.text .rodata .data .padding)
        "*/games/THE BROKEN SEAL/SRC/FIELD/COMMON/OBJECT/OBJECT10.o"(.text)
        "*/recon/tbs/raw/08094544.o"(.text .rodata .data .padding)
        "*/games/THE BROKEN SEAL/SRC/GRAPHICS/DISPLAY/SCROLL_INITIALIZE_HBLANK_DMA.o"(.text)
        "*/games/THE BROKEN SEAL/SRC/GRAPHICS/DISPLAY/SCROLL_DISARM_HBLANK_DMA.o"(.text)
        "*/recon/tbs/raw/08094820.o"(.text .rodata .data .padding)
        "*/games/THE BROKEN SEAL/SRC/BATTLE/EFFECT/STORM_FLASH.o"(.text)
        "*/recon/tbs/raw/08094ac8.o"(.text .rodata .data .padding)
        "*/recon/tbs/raw/08094bbc.o"(.text .rodata .data .padding)
        "*/games/THE BROKEN SEAL/SRC/FIELD/COMMON/EFFECT/EFFECT2.o"(.text)
        "*/games/COMMON/SRC/FIELD/COMMON/OBJECT/MOTION_MOVE_HALFWAY_TOWARD_TARGET.o"(.text)
        "*/games/THE BROKEN SEAL/SRC/BATTLE/EFFECT/EFFECT31.o"(.text)
        "*/games/THE BROKEN SEAL/SRC/BATTLE/EFFECT/EFFECT32.o"(.text)
        "*/games/THE BROKEN SEAL/SRC/BATTLE/EFFECT/HEAVY_IMPACT_FINISH.o"(.text)
        "*/games/THE BROKEN SEAL/SRC/BATTLE/EFFECT/EFFECT33.o"(.text)
        "*/games/THE BROKEN SEAL/SRC/BATTLE/EFFECT/RUN_MERCURY_DJINN_CAPTURE.o"(.text)
        "*/games/COMMON/SRC/FIELD/COMMON/DISPATCH_TYPE_HANDLER.o"(.text)
        "*/games/THE BROKEN SEAL/SRC/BATTLE/EFFECT/EFFECT.o"(.text)
        "*/recon/tbs/raw/08096c22.o"(.text .rodata .data .padding)
        "*/games/THE BROKEN SEAL/SRC/FIELD/COMMON/OBJECT/OBJECT11.o"(.text)
        "*/recon/tbs/raw/08096c7e.o"(.text .rodata .data .padding)
        "*/games/THE BROKEN SEAL/SRC/BATTLE/EFFECT/EFFECT34.o"(.text)
        "*/games/THE BROKEN SEAL/SRC/BATTLE/EFFECT/EFFECT35.o"(.text)
        "*/games/THE BROKEN SEAL/SRC/BATTLE/EFFECT/EFFECT36.o"(.text)
        "*/games/THE BROKEN SEAL/SRC/BATTLE/EFFECT/FINISH_SCENE_AND_RELEASE_HEAP_BLOCK.o"(.text)
        "*/recon/tbs/raw/08097644.o"(.text .rodata .data .padding)
        "*/games/THE BROKEN SEAL/SRC/BATTLE/EFFECT/ARM_BG0_HBLANK_DMA.o"(.text)
        "*/games/THE BROKEN SEAL/SRC/BATTLE/EFFECT/EFFECT37.o"(.text)
        "*/recon/tbs/raw/08097b52.o"(.text .rodata .data .padding)
        "*/games/THE BROKEN SEAL/SRC/BATTLE/EFFECT/EFFECT2.o"(.text)
        "*/recon/tbs/raw/08097c3c.o"(.text .rodata .data .padding)
        "*/games/THE BROKEN SEAL/SRC/BATTLE/EFFECT/EFFECT13.o"(.text)
        "*/games/THE BROKEN SEAL/SRC/BATTLE/EFFECT/RUN_EFFECT08.o"(.text)
        "*/games/THE BROKEN SEAL/SRC/BATTLE/EFFECT/EFFECT38.o"(.text)
        "*/games/THE BROKEN SEAL/SRC/BATTLE/EFFECT/EFFECT39.o"(.text)
        "*/recon/tbs/raw/08098b0e.o"(.text .rodata .data .padding)
        "*/games/THE BROKEN SEAL/SRC/BATTLE/EFFECT/EFFECT15.o"(.text)
        "*/recon/tbs/raw/08098cd6.o"(.text .rodata .data .padding)
        "*/games/THE BROKEN SEAL/SRC/BATTLE/EFFECT/EFFECT40.o"(.text)
        "*/games/THE BROKEN SEAL/SRC/BATTLE/EFFECT/CALL_EFFECT_03_AND_STOP.o"(.text)
        "*/games/THE BROKEN SEAL/SRC/FIELD/COMMON/MAP/EVENTS_CHECK_OBJECT_TILE.o"(.text)
        "*/games/THE BROKEN SEAL/SRC/BATTLE/EFFECT/SCHEDULE_CALLBACK_WHEN_VALUE24C_SET.o"(.text)
        "*/games/THE BROKEN SEAL/SRC/BATTLE/EFFECT/EFFECT41.o"(.text)
        "*/recon/tbs/raw/080999ee.o"(.text .rodata .data .padding)
        "*/recon/tbs/raw/080999f0.o"(.text .rodata .data .padding)
        "*/games/THE BROKEN SEAL/SRC/BATTLE/EFFECT/PARTICLES.o"(.text)
        "*/recon/tbs/raw/08099da4.o"(.text .rodata .data .padding)
        "*/games/THE BROKEN SEAL/SRC/BATTLE/EFFECT/EFFECT16.o"(.text)
        "*/recon/tbs/raw/0809a44a.o"(.text .rodata .data .padding)
        "*/games/THE BROKEN SEAL/SRC/BATTLE/EFFECT/UPDATE_OBJECT_MOTION_SCALE_AND_LINKED_ANGLE.o"(.text)
        "*/recon/tbs/raw/0809a482.o"(.text .rodata .data .padding)
        "*/games/THE BROKEN SEAL/SRC/FIELD/COMMON/EFFECT/SPAWN.o"(.text)
        "*/games/THE BROKEN SEAL/SRC/BATTLE/EFFECT/EFFECT14.o"(.text)
        "*/recon/tbs/raw/0809a8c2.o"(.text .rodata .data .padding)
        "*/games/THE BROKEN SEAL/SRC/BATTLE/EFFECT/EFFECT17.o"(.text)
        "*/recon/tbs/raw/0809abb4.o"(.text .rodata .data .padding)
        "*/games/THE BROKEN SEAL/SRC/BATTLE/EFFECT/OBJECT_PAUSE.o"(.text)
        "*/games/COMMON/SRC/BATTLE/EFFECT/FILTER_OBJECT_ID.o"(.text)
        "*/recon/tbs/raw/0809ae56.o"(.text .rodata .data .padding)
        "*/games/THE BROKEN SEAL/SRC/BATTLE/EFFECT/RUN_EFFECT13_HOOK.o"(.text)
        "*/recon/tbs/raw/0809ae62.o"(.text .rodata .data .padding)
        "*/recon/tbs/raw/0809ae64.o"(.text .rodata .data .padding)
        "*/games/THE BROKEN SEAL/SRC/BATTLE/EFFECT/RUN_EFFECT15.o"(.text)
        "*/games/THE BROKEN SEAL/SRC/BATTLE/EFFECT/SPAWN_DESCENDING_ARC_PARTICLES.o"(.text)
        "*/games/THE BROKEN SEAL/SRC/BATTLE/EFFECT/EFFECT42.o"(.text)
        "*/games/THE BROKEN SEAL/SRC/BATTLE/EFFECT/EFFECT43.o"(.text)
        "*/games/THE BROKEN SEAL/SRC/BATTLE/EFFECT/SETUP_RESOURCES_AND_WINDOW.o"(.text)
        "*/games/THE BROKEN SEAL/SRC/BATTLE/EFFECT/CLEANUP_RESOURCES_AND_WINDOW.o"(.text)
        "*/games/THE BROKEN SEAL/SRC/FIELD/COMMON/MAP/MAP7.o"(.text)
        "*/recon/tbs/unidentified.o"(.unidentified.0809c410)
        "*/games/THE BROKEN SEAL/SRC/FIELD/SCENES.o"(.rodata)
        "*/recon/tbs/unidentified.o"(.unidentified.0809f7f0)
        "*/games/THE BROKEN SEAL/SRC/SYSTEM/FAR_CALL/MENU.o"(.text .rodata .data .padding)
        "*/games/THE BROKEN SEAL/SRC/SYSTEM/SCHEDULER/DISABLE_OVERLAY_CALLBACKS_WITH_FLAGS.o"(.text)
        "*/recon/tbs/raw/080a106e.o"(.text .rodata .data .padding)
        "*/games/THE BROKEN SEAL/SRC/SYSTEM/SCHEDULER/ENABLE_OVERLAY_CALLBACKS_WITH_FLAGS.o"(.text)
        "*/recon/tbs/raw/080a108e.o"(.text .rodata .data .padding)
        "*/games/THE BROKEN SEAL/SRC/GRAPHICS/WINDOW/INITIALIZE_WORK.o"(.text)
        "*/games/COMMON/SRC/GRAPHICS/WINDOW/LIFECYCLE.o"(.text)
        "*/games/THE BROKEN SEAL/SRC/MENU/DRAW_OWNER_STATUS_PANEL.o"(.text)
        "*/games/COMMON/SRC/GRAPHICS/TEXT/DRAW_NUMBER_RIGHT_ALIGNED_FAR.o"(.text)
        "*/recon/tbs/raw/080a153a.o"(.text .rodata .data .padding)
        "*/games/THE BROKEN SEAL/SRC/GRAPHICS/RENDER/DRAW_VALUE_PAIR_ROWS.o"(.text)
        "*/games/THE BROKEN SEAL/SRC/GRAPHICS/TEXT/TEXT6.o"(.text)
        "*/recon/tbs/raw/080a1812.o"(.text .rodata .data .padding)
        "*/games/THE BROKEN SEAL/SRC/MENU/ABILITY/ABILITY2.o"(.text)
        "*/recon/tbs/raw/080a1abe.o"(.text .rodata .data .padding)
        "*/recon/tbs/raw/080a1ac0.o"(.text .rodata .data .padding)
        "*/games/THE BROKEN SEAL/SRC/MENU/ABILITY/RESERVED_NO_OP.o"(.text)
        "*/recon/tbs/raw/080a1bca.o"(.text .rodata .data .padding)
        "*/games/THE BROKEN SEAL/SRC/MENU/ABILITY/OWNER_ENTRIES.o"(.text)
        "*/games/COMMON/SRC/MENU/ITEM/POSITION_OWNER_ENTRY.o"(.text)
        "*/games/THE BROKEN SEAL/SRC/MENU/ITEM/REFRESH_OWNER_ENTRIES.o"(.text)
        "*/games/THE BROKEN SEAL/SRC/MENU/ITEM/SHOW_MODAL_MESSAGE.o"(.text)
        "*/recon/tbs/raw/080a1e36.o"(.text .rodata .data .padding)
        "*/games/THE BROKEN SEAL/SRC/MENU/ITEM/SORT_BY_LIST_ORDER.o"(.text)
        "*/recon/tbs/raw/080a1f72.o"(.text .rodata .data .padding)
        "*/games/COMMON/SRC/MENU/COPY_LIST_ORDER.o"(.text)
        "*/games/THE BROKEN SEAL/SRC/MENU/MENU18.o"(.text)
        "*/games/THE BROKEN SEAL/SRC/GRAPHICS/TEXT/DRAW_DRAW_WORK_VALUE_WITH_LABEL.o"(.text)
        "*/games/THE BROKEN SEAL/SRC/GRAPHICS/WINDOW/WINDOW8.o"(.text)
        "*/games/THE BROKEN SEAL/SRC/MENU/INPUT_CANCEL_SOUND_TICK.o"(.text)
        "*/recon/tbs/raw/080a24d0.o"(.text .rodata .data .padding)
        "*/games/THE BROKEN SEAL/SRC/MENU/ITEM/RUN_COMMANDS.o"(.text)
        "*/games/THE BROKEN SEAL/SRC/MENU/ITEM/USE.o"(.text)
        "*/games/THE BROKEN SEAL/SRC/MENU/ITEM/INTERFACE.o"(.text)
        "*/games/THE BROKEN SEAL/SRC/MENU/ITEM/PREPARE_OWNER_ITEMS.o"(.text)
        "*/games/THE BROKEN SEAL/SRC/MENU/ITEM/RUN_OWNER_SELECTION.o"(.text)
        "*/games/THE BROKEN SEAL/SRC/MENU/ITEM/OPEN_CATEGORY_ITEMS.o"(.text)
        "*/games/THE BROKEN SEAL/SRC/MENU/ITEM/SELECT_TARGET.o"(.text)
        "*/games/THE BROKEN SEAL/SRC/MENU/ITEM/ITEM.o"(.text)
        "*/games/THE BROKEN SEAL/SRC/MENU/ITEM/GET_ITEM_QUANTITY.o"(.text)
        "*/games/THE BROKEN SEAL/SRC/MENU/ITEM/ITEM7.o"(.text)
        "*/games/THE BROKEN SEAL/SRC/MENU/ITEM/ITEM2.o"(.text)
        "*/recon/tbs/raw/080a414a.o"(.text .rodata .data .padding)
        "*/recon/tbs/raw/080a414c.o"(.text .rodata .data .padding)
        "*/games/THE BROKEN SEAL/SRC/MENU/ITEM/ITEM8.o"(.text)
        "*/games/THE BROKEN SEAL/SRC/MENU/ITEM/MAYBE_BREAK_SELECTED_ITEM.o"(.text)
        "*/games/THE BROKEN SEAL/SRC/MENU/ITEM/OPEN_ITEM_DETAILS.o"(.text)
        "*/games/THE BROKEN SEAL/SRC/MENU/ITEM/ITEM9.o"(.text)
        "*/games/THE BROKEN SEAL/SRC/MENU/ITEM/WINDOW.o"(.text)
        "*/recon/tbs/raw/080a4f08.o"(.text .rodata .data .padding)
        "*/games/THE BROKEN SEAL/SRC/MENU/ITEM/ITEM3.o"(.text)
        "*/recon/tbs/raw/080a5388.o"(.text .rodata .data .padding)
        "*/games/THE BROKEN SEAL/SRC/SYSTEM/RESOURCE/LOAD_PAIRED_BLOCKS.o"(.text)
        "*/games/THE BROKEN SEAL/SRC/MENU/ITEM/ITEM4.o"(.text)
        "*/recon/tbs/raw/080a5b92.o"(.text .rodata .data .padding)
        "*/games/THE BROKEN SEAL/SRC/MENU/OPEN_CONFIRM_PROMPT.o"(.text)
        "*/recon/tbs/raw/080a5cc0.o"(.text .rodata .data .padding)
        "*/games/THE BROKEN SEAL/SRC/MENU/ABILITY/CLASSIFY_SELECTED_PSYNERGY.o"(.text)
        "*/games/THE BROKEN SEAL/SRC/MENU/ABILITY/ABILITY.o"(.text)
        "*/recon/tbs/raw/080a6614.o"(.text .rodata .data .padding)
        "*/games/THE BROKEN SEAL/SRC/MENU/ABILITY/ENTRY_GRID.o"(.text)
        "*/games/THE BROKEN SEAL/SRC/MENU/ABILITY/COLLECT_ACTIONS.o"(.text)
        "*/recon/tbs/raw/080a69fe.o"(.text .rodata .data .padding)
        "*/games/THE BROKEN SEAL/SRC/MENU/ABILITY/BUILD_PAGE_RESULT.o"(.text)
        "*/games/THE BROKEN SEAL/SRC/MENU/ABILITY/DRAW_DETAIL_PAGE.o"(.text)
        "*/games/THE BROKEN SEAL/SRC/MENU/ABILITY/ABILITY3.o"(.text)
        "*/recon/tbs/raw/080a737e.o"(.text .rodata .data .padding)
        "*/games/THE BROKEN SEAL/SRC/MENU/MENU12.o"(.text)
        "*/games/THE BROKEN SEAL/SRC/MENU/OPEN_ACTION_MENU.o"(.text)
        "*/games/THE BROKEN SEAL/SRC/MENU/RUN_ACTION_FLOW.o"(.text)
        "*/games/THE BROKEN SEAL/SRC/MENU/DJINN/SHOW_CURRENT_LIST.o"(.text)
        "*/recon/tbs/raw/080a7a32.o"(.text .rodata .data .padding)
        "*/games/THE BROKEN SEAL/SRC/MENU/MENU8.o"(.text)
        "*/games/THE BROKEN SEAL/SRC/MENU/SHOW_OWNER_PROGRESS_MESSAGE.o"(.text)
        "*/recon/tbs/raw/080a8604.o"(.text .rodata .data .padding)
        "*/games/THE BROKEN SEAL/SRC/SYSTEM/RUN_BUSY_WAIT_DELAY.o"(.text)
        "*/recon/tbs/raw/080a8912.o"(.text .rodata .data .padding)
        "*/games/THE BROKEN SEAL/SRC/MENU/ITEM/DRAW_OWNER_STATUS.o"(.text)
        "*/games/THE BROKEN SEAL/SRC/MENU/BUILD_AVAILABILITY.o"(.text)
        "*/games/THE BROKEN SEAL/SRC/MENU/ABILITY/RANGE_PAGE.o"(.text)
        "*/games/THE BROKEN SEAL/SRC/MENU/ABILITY/ABILITY4.o"(.text)
        "*/games/THE BROKEN SEAL/SRC/MENU/ITEM/DRAW_EQUIP_PAGE.o"(.text)
        "*/games/THE BROKEN SEAL/SRC/MENU/SHOP/DRAW_PARTY_ITEM_PAGE.o"(.text)
        "*/games/THE BROKEN SEAL/SRC/MENU/ITEM/ITEM10.o"(.text)
        "*/recon/tbs/raw/080a9a56.o"(.text .rodata .data .padding)
        "*/games/THE BROKEN SEAL/SRC/MENU/ITEM/ITEM6.o"(.text)
        "*/games/THE BROKEN SEAL/SRC/MENU/ITEM/ARRANGE_CATEGORY_ITEM_ICONS.o"(.text)
        "*/recon/tbs/raw/080a9cba.o"(.text .rodata .data .padding)
        "*/games/THE BROKEN SEAL/SRC/MENU/ITEM/ITEM5.o"(.text)
        "*/recon/tbs/raw/080a9e46.o"(.text .rodata .data .padding)
        "*/games/THE BROKEN SEAL/SRC/GAME/ITEM/ITEM.o"(.text)
        "*/recon/tbs/raw/080aa768.o"(.text .rodata .data .padding)
        "*/games/THE BROKEN SEAL/SRC/MENU/MENU10.o"(.text)
        "*/recon/tbs/raw/080aafb8.o"(.text .rodata .data .padding)
        "*/games/THE BROKEN SEAL/SRC/GRAPHICS/WINDOW/WINDOW10.o"(.text)
        "*/recon/tbs/raw/080ab5e4.o"(.text .rodata .data .padding)
        "*/games/THE BROKEN SEAL/SRC/MENU/DJINN/DJINN.o"(.text)
        "*/recon/tbs/raw/080acab8.o"(.text .rodata .data .padding)
        "*/games/THE BROKEN SEAL/SRC/FIELD/COMMON/OBJECT/MOTION_FOUR_OBJECT_INITIALIZE_TOP_ROW.o"(.text)
        "*/recon/tbs/raw/080ad40c.o"(.text .rodata .data .padding)
        "*/games/THE BROKEN SEAL/SRC/FIELD/COMMON/OBJECT/OBJECT15.o"(.text)
        "*/recon/tbs/raw/080ad6d4.o"(.text .rodata .data .padding)
        "*/recon/tbs/raw/080ae2f4.o"(.text .rodata .data .padding)
        "*/games/THE BROKEN SEAL/SRC/GAME/DJINN/MARK_BALANCED_ENTRIES.o"(.text)
        "*/games/THE BROKEN SEAL/SRC/MENU/MENU6.o"(.text)
        "*/recon/tbs/raw/080ae956.o"(.text .rodata .data .padding)
        "*/games/THE BROKEN SEAL/SRC/GRAPHICS/TILE/CREATE_WITH_LOADED_RESOURCE.o"(.text)
        "*/recon/tbs/raw/080ae99a.o"(.text .rodata .data .padding)
        "*/games/THE BROKEN SEAL/SRC/GRAPHICS/TEXT/TEXT3.o"(.text)
        "*/recon/tbs/unidentified.o"(.unidentified.080aea4c)
        "*/games/THE BROKEN SEAL/SRC/SYSTEM/FAR_CALL/SHOP.o"(.text .rodata .data .padding)
        "*/games/THE BROKEN SEAL/SRC/MENU/SHOP/SHOP2.o"(.text)
        "*/recon/tbs/raw/080b04da.o"(.text .rodata .data .padding)
        "*/games/THE BROKEN SEAL/SRC/MENU/SHOP/SHOP.o"(.text)
        "*/recon/tbs/raw/080b0aac.o"(.text .rodata .data .padding)
        "*/games/THE BROKEN SEAL/SRC/MENU/SHOP/DRAW_STOCK_PAGE.o"(.text)
        "*/games/THE BROKEN SEAL/SRC/MENU/SHOP/DRAW_MONEY.o"(.text)
        "*/games/THE BROKEN SEAL/SRC/MENU/SHOP/DRAW_ITEM_PRICE.o"(.text)
        "*/games/THE BROKEN SEAL/SRC/MENU/SHOP/DRAW_MESSAGE.o"(.text)
        "*/games/THE BROKEN SEAL/SRC/MENU/SHOP/UPDATE_PARTY_MEMBER_LIST.o"(.text)
        "*/recon/tbs/raw/080b1260.o"(.text .rodata .data .padding)
        "*/games/THE BROKEN SEAL/SRC/MENU/SHOP/SHOP3.o"(.text)
        "*/games/THE BROKEN SEAL/SRC/MENU/SHOP/SELECT_QUANTITY.o"(.text)
        "*/games/THE BROKEN SEAL/SRC/MENU/SHOP/SHOP4.o"(.text)
        "*/recon/tbs/raw/080b210e.o"(.text .rodata .data .padding)
        "*/games/THE BROKEN SEAL/SRC/MENU/SHOP/SHOP5.o"(.text)
        "*/games/THE BROKEN SEAL/SRC/MENU/SHOP/SHOP6.o"(.text)
        "*/games/THE BROKEN SEAL/SRC/MENU/SHOP/SHOP9.o"(.text)
        "*/games/THE BROKEN SEAL/SRC/MENU/SHOP/SHOP7.o"(.text)
        "*/games/THE BROKEN SEAL/SRC/MENU/SHOP/ITEM_SELECTION.o"(.text)
        "*/recon/tbs/unidentified.o"(.unidentified.080b3940)
        "*/games/THE BROKEN SEAL/SRC/SYSTEM/FAR_CALL/BATTLE.o"(.text .rodata .data .padding)
        "*/games/THE BROKEN SEAL/SRC/GRAPHICS/TILE/DECODE.o"(.text .rodata .data .padding)
        "*/recon/tbs/unidentified.o"(.unidentified.080b5204)
        "*/games/THE BROKEN SEAL/SRC/GRAPHICS/TILE/BIT_DISPATCH.o"(.text .rodata .data .padding)
        "*/recon/tbs/unidentified.o"(.unidentified.080b5218)
        "*/games/THE BROKEN SEAL/SRC/GRAPHICS/TILE/BIT_COMMANDS.o"(.text .rodata .data .padding)
        /* The tile bit decoder block 080c08ec copies to RAM, DECODE.S to BIT_COMMANDS.S. */
        BitDecoder_Size = ABSOLUTE(BitDecoder_End - Func_080b5138);
        "*/games/THE BROKEN SEAL/SRC/DEBUG/LOAD_PARTY_PRESET.o"(.text)
        "*/recon/tbs/raw/080b5534.o"(.text .rodata .data .padding)
        "*/recon/tbs/raw/080b56e0.o"(.text .rodata .data .padding)
        "*/games/THE BROKEN SEAL/SRC/BATTLE/PRESENTATION/PRESENT4.o"(.text)
        "*/recon/tbs/raw/080b5b16.o"(.text .rodata .data .padding)
        "*/games/THE BROKEN SEAL/SRC/BATTLE/PARTY/PARTY2.o"(.text)
        "*/recon/tbs/raw/080b5d3a.o"(.text .rodata .data .padding)
        "*/games/THE BROKEN SEAL/SRC/BATTLE/SUMMON/UPDATE_AVAILABILITY.o"(.text)
        "*/recon/tbs/raw/080b5e12.o"(.text .rodata .data .padding)
        "*/games/THE BROKEN SEAL/SRC/GAME/PARTY/UPDATE_NAME_ENTRIES.o"(.text)
        "*/recon/tbs/raw/080b5f0c.o"(.text .rodata .data .padding)
        "*/games/THE BROKEN SEAL/SRC/GRAPHICS/TEXT/FORMAT_NAME.o"(.text)
        "*/recon/tbs/raw/080b609e.o"(.text .rodata .data .padding)
        "*/games/THE BROKEN SEAL/SRC/BATTLE/PRESENTATION/WAIT_SYNC.o"(.text)
        "*/recon/tbs/raw/080b6146.o"(.text .rodata .data .padding)
        "*/games/THE BROKEN SEAL/SRC/BATTLE/PRESENTATION/SYNC_TURN.o"(.text)
        "*/games/THE BROKEN SEAL/SRC/BATTLE/PARTY/PARTY4.o"(.text)
        "*/recon/tbs/raw/080b63c8.o"(.text .rodata .data .padding)
        "*/games/THE BROKEN SEAL/SRC/BATTLE/PARTY/PARTY.o"(.text)
        "*/games/COMMON/SRC/BATTLE/ACTOR_COMMIT_PLACEMENT.o"(.text)
        "*/recon/tbs/raw/080b6cae.o"(.text .rodata .data .padding)
        "*/games/COMMON/SRC/BATTLE/PARTY/LIST_ALL_UNITS_AND_SUBMIT.o"(.text)
        "*/recon/tbs/raw/080b6cce.o"(.text .rodata .data .padding)
        "*/games/THE BROKEN SEAL/SRC/BATTLE/PRESENTATION/PRESENT8.o"(.text)
        "*/games/THE BROKEN SEAL/SRC/BATTLE/SUMMON/REFRESH.o"(.text)
        "*/recon/tbs/raw/080b75dc.o"(.text .rodata .data .padding)
        "*/games/THE BROKEN SEAL/SRC/BATTLE/PARTY/CONTAINS_ID.o"(.text)
        "*/recon/tbs/raw/080b7738.o"(.text .rodata .data .padding)
        "*/games/THE BROKEN SEAL/SRC/BATTLE/BATTLE.o"(.text)
        "*/games/COMMON/SRC/BATTLE/MOTION/RELEASE_BATTLE_OBJECT_RECORDS.o"(.text)
        "*/recon/tbs/raw/080b7b6a.o"(.text .rodata .data .padding)
        "*/recon/tbs/raw/080b7b6c.o"(.text .rodata .data .padding)
        "*/games/THE BROKEN SEAL/SRC/BATTLE/MOTION/MOTION2.o"(.text)
        "*/recon/tbs/raw/080b7f9a.o"(.text .rodata .data .padding)
        "*/games/THE BROKEN SEAL/SRC/BATTLE/MOTION/MOTION.o"(.text)
        "*/recon/tbs/raw/080b83b2.o"(.text .rodata .data .padding)
        "*/games/THE BROKEN SEAL/SRC/BATTLE/MOTION/APPLY_PAIR_MIDPOINT.o"(.text)
        "*/recon/tbs/raw/080b8416.o"(.text .rodata .data .padding)
        "*/games/THE BROKEN SEAL/SRC/BATTLE/MOTION/SPAWN_SLOT_EFFECT_AND_WAIT.o"(.text)
        "*/games/THE BROKEN SEAL/SRC/BATTLE/MOTION/MOTION3.o"(.text)
        "*/recon/tbs/raw/080b8572.o"(.text .rodata .data .padding)
        "*/games/THE BROKEN SEAL/SRC/BATTLE/PRESENTATION/ADJUST_CAMERA_BY_SHOULDER_KEYS.o"(.text)
        "*/games/THE BROKEN SEAL/SRC/BATTLE/PRESENTATION/PAIRED_TRANS.o"(.text)
        "*/games/THE BROKEN SEAL/SRC/BATTLE/PRESENTATION/ACT_RUN_APPROACH.o"(.text)
        "*/recon/tbs/raw/080b8c1c.o"(.text .rodata .data .padding)
        "*/games/THE BROKEN SEAL/SRC/BATTLE/PRESENTATION/PRESENT12.o"(.text)
        "*/recon/tbs/raw/080b8f56.o"(.text .rodata .data .padding)
        "*/games/THE BROKEN SEAL/SRC/BATTLE/BATTLE2.o"(.text)
        "*/recon/tbs/raw/080b9322.o"(.text .rodata .data .padding)
        "*/games/THE BROKEN SEAL/SRC/BATTLE/PRESENTATION/PRESENT5.o"(.text)
        "*/recon/tbs/raw/080b9554.o"(.text .rodata .data .padding)
        "*/recon/tbs/raw/080b9724.o"(.text .rodata .data .padding)
        "*/games/THE BROKEN SEAL/SRC/BATTLE/PRESENTATION/PRESENT6.o"(.text)
        "*/recon/tbs/raw/080b9b2e.o"(.text .rodata .data .padding)
        "*/recon/tbs/raw/080b9b30.o"(.text .rodata .data .padding)
        "*/games/THE BROKEN SEAL/SRC/BATTLE/PRESENTATION/PRESENT13.o"(.text)
        "*/recon/tbs/raw/080b9ec0.o"(.text .rodata .data .padding)
        "*/games/COMMON/SRC/BATTLE/PRESENTATION/ACT_RUN_ENTRIES.o"(.text)
        "*/recon/tbs/raw/080ba2be.o"(.text .rodata .data .padding)
        "*/games/THE BROKEN SEAL/SRC/BATTLE/PRESENTATION/RUN_SIMPLE.o"(.text)
        "*/recon/tbs/raw/080ba6ac.o"(.text .rodata .data .padding)
        "*/games/THE BROKEN SEAL/SRC/BATTLE/MOTION/SET_RECORD_CHILD_VALUES.o"(.text)
        "*/recon/tbs/raw/080ba976.o"(.text .rodata .data .padding)
        "*/recon/tbs/raw/080ba978.o"(.text .rodata .data .padding)
        "*/games/THE BROKEN SEAL/SRC/BATTLE/MOTION/RUN_VALUE_SEQUENCE.o"(.text)
        "*/recon/tbs/raw/080bac6c.o"(.text .rodata .data .padding)
        "*/games/THE BROKEN SEAL/SRC/BATTLE/BATTLE4.o"(.text)
        "*/games/THE BROKEN SEAL/SRC/BATTLE/ACTOR_RESET_RUNTIME_FIELDS.o"(.text)
        "*/recon/tbs/raw/080bb7c0.o"(.text .rodata .data .padding)
        "*/games/THE BROKEN SEAL/SRC/BATTLE/EVENT_QUEUE.o"(.text)
        "*/games/COMMON/SRC/BATTLE/EFFECT/CAN_AFFECT_DEFEATED_UNIT.o"(.text)
        "*/recon/tbs/raw/080bbb0a.o"(.text .rodata .data .padding)
        "*/games/THE BROKEN SEAL/SRC/BATTLE/ACTION_RESOLVE_TARGET_ACTION.o"(.text)
        "*/games/COMMON/SRC/BATTLE/CHECK_STATUS_OR_SPECIAL_ID.o"(.text)
        "*/recon/tbs/raw/080bd3e2.o"(.text .rodata .data .padding)
        "*/games/THE BROKEN SEAL/SRC/BATTLE/SELECT_WEIGHTED_INDEX.o"(.text)
        "*/recon/tbs/raw/080bd422.o"(.text .rodata .data .padding)
        "*/recon/tbs/raw/080bd424.o"(.text .rodata .data .padding)
        "*/games/THE BROKEN SEAL/SRC/BATTLE/BATTLE3.o"(.text)
        "*/recon/tbs/raw/080bd850.o"(.text .rodata .data .padding)
        "*/recon/tbs/raw/080bd898.o"(.text .rodata .data .padding)
        "*/games/THE BROKEN SEAL/SRC/BATTLE/BATTLE11.o"(.text)
        "*/games/COMMON/SRC/BATTLE/PARTY/IS_UNIT_LISTED.o"(.text)
        "*/games/THE BROKEN SEAL/SRC/BATTLE/PARTY/COUNT_VALID_ENTRIES.o"(.text)
        "*/recon/tbs/raw/080be18a.o"(.text .rodata .data .padding)
        "*/recon/tbs/raw/080be18c.o"(.text .rodata .data .padding)
        "*/recon/tbs/raw/080be378.o"(.text .rodata .data .padding)
        "*/games/THE BROKEN SEAL/SRC/BATTLE/PARTY/ROLL_COUNTER_EARLY_END.o"(.text)
        "*/recon/tbs/raw/080bf54a.o"(.text .rodata .data .padding)
        "*/games/THE BROKEN SEAL/SRC/BATTLE/PARTY/TIMED_ENTRIES.o"(.text)
        "*/recon/tbs/raw/080bf672.o"(.text .rodata .data .padding)
        "*/games/THE BROKEN SEAL/SRC/BATTLE/RUNTIME_RESERVED_NO_OP_C.o"(.text)
        "*/recon/tbs/raw/080bf676.o"(.text .rodata .data .padding)
        "*/games/THE BROKEN SEAL/SRC/BATTLE/PARTY/PROCESS_ROUND_END.o"(.text)
        "*/recon/tbs/raw/080bfba4.o"(.text .rodata .data .padding)
        "*/games/THE BROKEN SEAL/SRC/BATTLE/PRESENTATION/RUN_MOSAIC_FADE_OUT.o"(.text)
        "*/games/COMMON/SRC/GRAPHICS/TILE/BUILD_SEQUENTIAL_TABLE.o"(.text)
        "*/games/THE BROKEN SEAL/SRC/BATTLE/PRESENTATION/PRESENT.o"(.text)
        "*/recon/tbs/raw/080c02a4.o"(.text .rodata .data .padding)
        "*/games/THE BROKEN SEAL/SRC/BATTLE/PRESENTATION/PRESENT9.o"(.text)
        "*/games/THE BROKEN SEAL/SRC/BATTLE/PRESENTATION/PRESENT10.o"(.text)
        "*/recon/tbs/raw/080c08ec.o"(.text .rodata .data .padding)
        "*/games/THE BROKEN SEAL/SRC/BATTLE/PRESENTATION/PRESENT11.o"(.text)
        "*/games/THE BROKEN SEAL/SRC/BATTLE/PRESENTATION/TRANS_SETUP.o"(.text)
        "*/games/COMMON/SRC/BATTLE/PRESENTATION/SETUP_TRANSITION_AT_PAIR_MIDPOINT.o"(.text)
        "*/recon/tbs/raw/080c0e36.o"(.text .rodata .data .padding)
        "*/games/THE BROKEN SEAL/SRC/GRAPHICS/DISPLAY/FADE_ALPHA_OUT.o"(.text)
        "*/recon/tbs/raw/080c0e6e.o"(.text .rodata .data .padding)
        "*/games/THE BROKEN SEAL/SRC/GRAPHICS/DISPLAY/FADE_ALPHA_IN.o"(.text)
        "*/recon/tbs/raw/080c0ea6.o"(.text .rodata .data .padding)
        "*/games/THE BROKEN SEAL/SRC/BATTLE/PRESENTATION/PRESENT2.o"(.text)
        "*/recon/tbs/raw/080c0eea.o"(.text .rodata .data .padding)
        "*/games/THE BROKEN SEAL/SRC/DEBUG/ADJUST_VALUE_WITH_BUTTONS.o"(.text)
        "*/games/THE BROKEN SEAL/SRC/BATTLE/PRESENTATION/ACTOR_SET_RECORD_MODE.o"(.text)
        "*/recon/tbs/raw/080c1012.o"(.text .rodata .data .padding)
        "*/games/COMMON/SRC/BATTLE/PRESENTATION/PRESENT.o"(.text)
        "*/games/THE BROKEN SEAL/SRC/BATTLE/EFFECT/EFFECT3.o"(.text)
        "*/recon/tbs/raw/080c1470.o"(.text .rodata .data .padding)
        "*/games/THE BROKEN SEAL/SRC/GRAPHICS/PALETTE/PALETTE6.o"(.text)
        "*/recon/tbs/raw/080c1796.o"(.text .rodata .data .padding)
        "*/recon/tbs/raw/080c1798.o"(.text .rodata .data .padding)
        "*/games/THE BROKEN SEAL/SRC/BATTLE/PRESENTATION/ACT_RUN_ZERO.o"(.text)
        "*/recon/tbs/raw/080c1a22.o"(.text .rodata .data .padding)
        "*/games/THE BROKEN SEAL/SRC/BATTLE/BATTLE5.o"(.text)
        "*/recon/tbs/raw/080c1fa6.o"(.text .rodata .data .padding)
        "*/games/THE BROKEN SEAL/SRC/BATTLE/FORMATION_SELECT_RANDOM_AVAILABLE_MEMBER.o"(.text)
        "*/recon/tbs/raw/080c1ffc.o"(.text .rodata .data .padding)
        "*/games/THE BROKEN SEAL/SRC/BATTLE/SUMMON/SUMMON.o"(.text)
        "*/games/THE BROKEN SEAL/SRC/BATTLE/BATTLE10.o"(.text)
        "*/recon/tbs/unidentified.o"(.unidentified.080c2a0a)
        "*/games/THE BROKEN SEAL/SRC/SYSTEM/FAR_CALL/EFFECT.o"(.text .rodata .data .padding)
        "*/games/THE BROKEN SEAL/SRC/BATTLE/PRESENTATION/PRESENT7.o"(.text)
        "*/recon/tbs/raw/080c91dc.o"(.text .rodata .data .padding)
        "*/recon/tbs/raw/080c972c.o"(.text .rodata .data .padding)
        "*/games/THE BROKEN SEAL/SRC/BATTLE/EFFECT/RUN_FIVE_MODE_MODE0.o"(.text)
        "*/recon/tbs/raw/080c9ca8.o"(.text .rodata .data .padding)
        "*/games/THE BROKEN SEAL/SRC/BATTLE/EFFECT/PARTICLE_POOL.o"(.text)
        "*/recon/tbs/raw/080ca1fc.o"(.text .rodata .data .padding)
        "*/games/THE BROKEN SEAL/SRC/BATTLE/EFFECT/TWELVE_MODE.o"(.text)
        "*/recon/tbs/raw/080ca60c.o"(.text .rodata .data .padding)
        "*/games/THE BROKEN SEAL/SRC/BATTLE/EFFECT/FLIPPING_BURST.o"(.text)
        "*/recon/tbs/raw/080cb4ec.o"(.text .rodata .data .padding)
        "*/recon/tbs/raw/080cb7f8.o"(.text .rodata .data .padding)
        "*/recon/tbs/raw/080cbc0c.o"(.text .rodata .data .padding)
        "*/recon/tbs/raw/080cc5d8.o"(.text .rodata .data .padding)
        "*/games/THE BROKEN SEAL/SRC/BATTLE/PRESENTATION/PRESENT3.o"(.text)
        "*/recon/tbs/raw/080ccc38.o"(.text .rodata .data .padding)
        "*/recon/tbs/raw/080ccebc.o"(.text .rodata .data .padding)
        "*/games/THE BROKEN SEAL/SRC/BATTLE/EFFECT/EFFECT44.o"(.text)
        "*/games/THE BROKEN SEAL/SRC/GRAPHICS/DISPLAY/DISPLAY5.o"(.text)
        "*/games/THE BROKEN SEAL/SRC/BATTLE/EFFECT/EFFECT45.o"(.text)
        "*/games/THE BROKEN SEAL/SRC/BATTLE/EFFECT/SETUP_CANVAS_TILE_MAP.o"(.text)
        "*/recon/tbs/raw/080cde8e.o"(.text .rodata .data .padding)
        "*/games/THE BROKEN SEAL/SRC/BATTLE/EFFECT/CANVAS_DRAW_CLIPPED_LINE.o"(.text)
        "*/recon/tbs/raw/080ce034.o"(.text .rodata .data .padding)
        "*/recon/tbs/raw/080ce4e8.o"(.text .rodata .data .padding)
        "*/games/THE BROKEN SEAL/SRC/BATTLE/EFFECT/EFFECT4.o"(.text)
        "*/recon/tbs/raw/080ceb54.o"(.text .rodata .data .padding)
        "*/games/THE BROKEN SEAL/SRC/BATTLE/EFFECT/EFFECT5.o"(.text)
        "*/recon/tbs/raw/080ceff8.o"(.text .rodata .data .padding)
        "*/games/THE BROKEN SEAL/SRC/BATTLE/EFFECT/MEMBER_BEAM.o"(.text)
        "*/recon/tbs/raw/080cf2b8.o"(.text .rodata .data .padding)
        "*/games/THE BROKEN SEAL/SRC/BATTLE/EFFECT/SEVEN_MODE_DISPATCH.o"(.text)
        "*/recon/tbs/raw/080cf8e0.o"(.text .rodata .data .padding)
        "*/games/THE BROKEN SEAL/SRC/BATTLE/EFFECT/EFFECT6.o"(.text)
        "*/recon/tbs/raw/080d05fc.o"(.text .rodata .data .padding)
        "*/recon/tbs/raw/080d0ad4.o"(.text .rodata .data .padding)
        "*/recon/tbs/raw/080d0ee0.o"(.text .rodata .data .padding)
        "*/recon/tbs/raw/080d1350.o"(.text .rodata .data .padding)
        "*/recon/tbs/raw/080d1714.o"(.text .rodata .data .padding)
        "*/games/THE BROKEN SEAL/SRC/BATTLE/EFFECT/RUNTIME_DRAW_RENDER_ANIMATION_MODE1.o"(.text)
        "*/recon/tbs/raw/080d2464.o"(.text .rodata .data .padding)
        "*/recon/tbs/raw/080d2d98.o"(.text .rodata .data .padding)
        "*/recon/tbs/raw/080d33c0.o"(.text .rodata .data .padding)
        "*/recon/tbs/raw/080d3854.o"(.text .rodata .data .padding)
        "*/recon/tbs/raw/080d3c80.o"(.text .rodata .data .padding)
        "*/games/THE BROKEN SEAL/SRC/GRAPHICS/PALETTE/UPDATE_PHASE.o"(.text)
        "*/recon/tbs/raw/080d41a4.o"(.text .rodata .data .padding)
        "*/games/THE BROKEN SEAL/SRC/BATTLE/EFFECT/RUN_TWO_MODE_B_MODE0.o"(.text)
        "*/recon/tbs/raw/080d4604.o"(.text .rodata .data .padding)
        "*/recon/tbs/raw/080d4ce8.o"(.text .rodata .data .padding)
        "*/games/THE BROKEN SEAL/SRC/BATTLE/EFFECT/RENDER_MODE.o"(.text)
        "*/recon/tbs/raw/080d52c8.o"(.text .rodata .data .padding)
        "*/games/THE BROKEN SEAL/SRC/BATTLE/EFFECT/EFFECT7.o"(.text)
        "*/recon/tbs/raw/080d5e54.o"(.text .rodata .data .padding)
        "*/games/THE BROKEN SEAL/SRC/FIELD/COMMON/CAMERA/APPLY_PHASED_DELTA.o"(.text)
        "*/games/COMMON/SRC/BATTLE/EFFECT/RUN_NO_EFFECT_FRAMES.o"(.text)
        "*/recon/tbs/raw/080d6576.o"(.text .rodata .data .padding)
        "*/games/THE BROKEN SEAL/SRC/BATTLE/EFFECT/EFFECT8.o"(.text)
        "*/recon/tbs/raw/080d67da.o"(.text .rodata .data .padding)
        "*/games/THE BROKEN SEAL/SRC/BATTLE/EFFECT/SETUP_BLENDED_DISPLAY.o"(.text)
        "*/recon/tbs/raw/080d6886.o"(.text .rodata .data .padding)
        "*/games/THE BROKEN SEAL/SRC/FIELD/COMMON/OBJECT/OBJECT12.o"(.text)
        "*/recon/tbs/raw/080d6970.o"(.text .rodata .data .padding)
        "*/games/THE BROKEN SEAL/SRC/BATTLE/EFFECT/INITIALIZE_MODE10.o"(.text)
        "*/recon/tbs/raw/080d82b0.o"(.text .rodata .data .padding)
        "*/recon/tbs/raw/080d85d0.o"(.text .rodata .data .padding)
        "*/games/THE BROKEN SEAL/SRC/BATTLE/EFFECT/SERIES_A.o"(.text)
        "*/recon/tbs/raw/080d89ac.o"(.text .rodata .data .padding)
        "*/games/THE BROKEN SEAL/SRC/BATTLE/EFFECT/RUN_SERIES_B_MODE0.o"(.text)
        "*/recon/tbs/raw/080d91dc.o"(.text .rodata .data .padding)
        "*/games/THE BROKEN SEAL/SRC/BATTLE/EFFECT/PALETTE_RAMP.o"(.text)
        "*/recon/tbs/raw/080d9ae8.o"(.text .rodata .data .padding)
        "*/games/THE BROKEN SEAL/SRC/BATTLE/EFFECT/EFFECT9.o"(.text)
        "*/recon/tbs/raw/080da2ac.o"(.text .rodata .data .padding)
        "*/recon/tbs/raw/080da6cc.o"(.text .rodata .data .padding)
        "*/recon/tbs/raw/080dab74.o"(.text .rodata .data .padding)
        "*/recon/tbs/raw/080db264.o"(.text .rodata .data .padding)
        "*/games/THE BROKEN SEAL/SRC/BATTLE/EFFECT/PARTICLE_FIELD.o"(.text)
        "*/recon/tbs/raw/080db6e0.o"(.text .rodata .data .padding)
        "*/games/THE BROKEN SEAL/SRC/BATTLE/EFFECT/SPAWN_OBJECTS.o"(.text)
        "*/recon/tbs/raw/080dbb9a.o"(.text .rodata .data .padding)
        "*/games/THE BROKEN SEAL/SRC/BATTLE/EFFECT/EFFECT18.o"(.text)
        "*/games/THE BROKEN SEAL/SRC/BATTLE/EFFECT/TARGET_BURSTS.o"(.text)
        "*/recon/tbs/raw/080dc968.o"(.text .rodata .data .padding)
        "*/games/THE BROKEN SEAL/SRC/BATTLE/EFFECT/EFFECT19.o"(.text)
        "*/recon/tbs/raw/080ddde0.o"(.text .rodata .data .padding)
        "*/recon/tbs/raw/080de2f8.o"(.text .rodata .data .padding)
        "*/games/THE BROKEN SEAL/SRC/BATTLE/EFFECT/PROJECTILE_VOLLEY.o"(.text)
        "*/recon/tbs/raw/080dea6e.o"(.text .rodata .data .padding)
        "*/recon/tbs/raw/080dea70.o"(.text .rodata .data .padding)
        "*/games/THE BROKEN SEAL/SRC/BATTLE/EFFECT/EFFECT20.o"(.text)
        "*/games/COMMON/SRC/GRAPHICS/TILE/PACK_ROWS.o"(.text)
        "*/games/THE BROKEN SEAL/SRC/BATTLE/EFFECT/EFFECT21.o"(.text)
        "*/games/COMMON/SRC/GRAPHICS/TILE/TRANSPOSE_COPY.o"(.text)
        "*/recon/tbs/raw/080dfe2a.o"(.text .rodata .data .padding)
        "*/recon/tbs/raw/080dfe2c.o"(.text .rodata .data .padding)
        "*/recon/tbs/raw/080e01e4.o"(.text .rodata .data .padding)
        "*/games/THE BROKEN SEAL/SRC/SYSTEM/RESOURCE/LOAD_AND_DECOMPRESS.o"(.text)
        "*/recon/tbs/raw/080e0564.o"(.text .rodata .data .padding)
        "*/games/THE BROKEN SEAL/SRC/BATTLE/EFFECT/PARTICLE_REVEAL.o"(.text)
        "*/recon/tbs/raw/080e1040.o"(.text .rodata .data .padding)
        "*/games/THE BROKEN SEAL/SRC/FIELD/COMMON/CAMERA/APPLY_SHAKE.o"(.text)
        "*/recon/tbs/raw/080e15e8.o"(.text .rodata .data .padding)
        "*/recon/tbs/raw/080e2538.o"(.text .rodata .data .padding)
        "*/games/THE BROKEN SEAL/SRC/FIELD/COMMON/EFFECT/ANIMATION_MODES.o"(.text)
        "*/recon/tbs/raw/080e2972.o"(.text .rodata .data .padding)
        "*/recon/tbs/raw/080e2974.o"(.text .rodata .data .padding)
        "*/recon/tbs/raw/080e302c.o"(.text .rodata .data .padding)
        "*/games/THE BROKEN SEAL/SRC/FIELD/COMMON/EFFECT/EFFECT3.o"(.text)
        "*/recon/tbs/raw/080e3aa0.o"(.text .rodata .data .padding)
        "*/recon/tbs/raw/080e40a4.o"(.text .rodata .data .padding)
        "*/games/THE BROKEN SEAL/SRC/BATTLE/EFFECT/STEP_PALETTE_TO_RESOURCE.o"(.text)
        "*/recon/tbs/raw/080e47b8.o"(.text .rodata .data .padding)
        "*/recon/tbs/raw/080e6638.o"(.text .rodata .data .padding)
        "*/games/THE BROKEN SEAL/SRC/BATTLE/EFFECT/STORE_OBJECT_AND_RUN_STEP7.o"(.text)
        "*/recon/tbs/raw/080e698c.o"(.text .rodata .data .padding)
        "*/games/THE BROKEN SEAL/SRC/BATTLE/EFFECT/PLACE_FORMATION_OBJECTS.o"(.text)
        "*/recon/tbs/raw/080e6eac.o"(.text .rodata .data .padding)
        "*/games/THE BROKEN SEAL/SRC/GRAPHICS/PALETTE/PALETTE7.o"(.text)
        "*/recon/tbs/raw/080e7338.o"(.text .rodata .data .padding)
        "*/recon/tbs/raw/080e7404.o"(.text .rodata .data .padding)
        "*/recon/tbs/raw/080e823c.o"(.text .rodata .data .padding)
        "*/recon/tbs/raw/080e89ec.o"(.text .rodata .data .padding)
        "*/recon/tbs/raw/080e90a8.o"(.text .rodata .data .padding)
        "*/recon/tbs/raw/080e94b8.o"(.text .rodata .data .padding)
        "*/recon/tbs/raw/080e99c0.o"(.text .rodata .data .padding)
        "*/recon/tbs/raw/080ea0d8.o"(.text .rodata .data .padding)
        "*/recon/tbs/raw/080eb754.o"(.text .rodata .data .padding)
        "*/games/THE BROKEN SEAL/SRC/BATTLE/EFFECT/EFFECT10.o"(.text)
        "*/games/COMMON/SRC/BATTLE/EFFECT/WAIT_THEN_SET_FIELD.o"(.text)
        "*/games/COMMON/SRC/BATTLE/EFFECT/WAIT_TWELVE_FRAMES_THEN_SET_FIELD.o"(.text)
        "*/games/THE BROKEN SEAL/SRC/BATTLE/EFFECT/EFFECT22.o"(.text)
        "*/recon/tbs/raw/080ed408.o"(.text .rodata .data .padding)
        "*/recon/tbs/unidentified.o"(.unidentified.080eda78)
        "*/games/THE BROKEN SEAL/SRC/BATTLE/EFFECT/SENTOU_KOUKA_GOUSEI.o"(.text .rodata .data .padding)
        "*/recon/tbs/unidentified.o"(.unidentified.080ede48)
        "*/games/THE BROKEN SEAL/SRC/BATTLE/EFFECT/SENTOU_KOUKA_GOUSEI_IRO.o"(.text .rodata .data .padding)
        "*/recon/tbs/unidentified.o"(.unidentified.080ef014)
        "*/games/THE BROKEN SEAL/SRC/SYSTEM/FAR_CALL/SCROLL.o"(.text .rodata .data .padding)
        "*/games/THE BROKEN SEAL/SRC/BATTLE/EFFECT/SENTOU_KOUKA_SEKIWA.o"(.text .rodata .data .padding)
        "*/games/THE BROKEN SEAL/SRC/BATTLE/EFFECT/SENTOU_KOUKA_TENKAI.o"(.text .rodata .data .padding)
        "*/games/THE BROKEN SEAL/SRC/BATTLE/EFFECT/SENTOU_KOUKA_TENKAI_LINK.o"(.text .rodata .data .padding)
        "*/games/THE BROKEN SEAL/SRC/BATTLE/EFFECT/SENTOU_KOUKA_TENKAI_DISPATCH.o"(.text .rodata .data .padding)
        "*/games/THE BROKEN SEAL/SRC/BATTLE/EFFECT/SENTOU_KOUKA_TENKAI_TABLES.o"(.text .rodata .data .padding)
        "*/games/THE BROKEN SEAL/SRC/BATTLE/EFFECT/SENTOU_KOUKA_TENKAI_COMMANDS.o"(.text .rodata .data .padding)
        "*/games/THE BROKEN SEAL/SRC/GRAPHICS/TILE/TILE3.o"(.text)
        "*/recon/tbs/raw/080f03f0.o"(.text .rodata .data .padding)
        "*/games/THE BROKEN SEAL/SRC/GRAPHICS/DISPLAY/DISPLAY6.o"(.text)
        "*/recon/tbs/raw/080f07f0.o"(.text .rodata .data .padding)
        "*/recon/tbs/unidentified.o"(.unidentified.080f0a5c)
        "*/games/THE BROKEN SEAL/SRC/SYSTEM/FAR_CALL/PALETTE.o"(.text .rodata .data .padding)
        "*/recon/tbs/raw/080f2028.o"(.text .rodata .data .padding)
        "*/recon/tbs/raw/080f24a0.o"(.text .rodata .data .padding)
        "*/recon/tbs/raw/080f26ec.o"(.text .rodata .data .padding)
        "*/recon/tbs/unidentified.o"(.unidentified.080f2b6c)
        "*/games/THE BROKEN SEAL/SRC/GRAPHICS/DISPLAY/TITLE_SHOW_SPLASH_SCREEN.o"(.text)
        "*/recon/tbs/raw/080f2d54.o"(.text .rodata .data .padding)
        "*/games/THE BROKEN SEAL/SRC/GRAPHICS/PALETTE/RESERVED_NO_OP.o"(.text)
        "*/recon/tbs/raw/080f2eba.o"(.text .rodata .data .padding)
        "*/games/THE BROKEN SEAL/SRC/GRAPHICS/PALETTE/PALETTE2.o"(.text)
        "*/recon/tbs/raw/080f3078.o"(.text .rodata .data .padding)
        "*/games/THE BROKEN SEAL/SRC/GRAPHICS/PALETTE/PALETTE4.o"(.text)
        "*/games/COMMON/SRC/GRAPHICS/PALETTE/PALETTE.o"(.text)
        "*/recon/tbs/unidentified.o"(.unidentified.080f38bc)
        "*/games/THE BROKEN SEAL/SRC/SYSTEM/FAR_CALL/BLANK_RUN.o"(.text .rodata .data .padding)
        "*/games/THE BROKEN SEAL/SRC/FIELD/COMMON/CAMERA/CAMERA.o"(.text)
        "*/games/COMMON/SRC/GRAPHICS/PALETTE/SCALE_RGB555_BUFFER.o"(.text)
        "*/recon/tbs/raw/080f4168.o"(.text .rodata .data .padding)
        "*/recon/tbs/unidentified.o"(.unidentified.080f53dc)
        "*/games/THE BROKEN SEAL/SRC/SYSTEM/FAR_CALL/BLANK_LOAD.o"(.text .rodata .data .padding)
        "*/games/THE BROKEN SEAL/SRC/BATTLE/EFFECT/EFFECT23.o"(.text)
        "*/recon/tbs/raw/080f6440.o"(.text .rodata .data .padding)
        "*/games/THE BROKEN SEAL/SRC/MINIGAME/REEL_INIT_TITLE.o"(.text)
        "*/recon/tbs/raw/080f7460.o"(.text .rodata .data .padding)
        "*/games/THE BROKEN SEAL/SRC/SOUND/TRACK_SLOT_BUFFER.o"(.text)
        "*/recon/tbs/raw/080f7f78.o"(.text .rodata .data .padding)
        "*/recon/tbs/unidentified.o"(.unidentified.080f86f8)
        "*/games/THE BROKEN SEAL/SRC/SYSTEM/FAR_CALL/SOUND.o"(.text .rodata .data .padding)
        "*/games/THE BROKEN SEAL/SRC/SOUND/COMMAND_PLAY.o"(.text)
        "*/recon/tbs/raw/080f91e6.o"(.text .rodata .data .padding)
        "*/games/THE BROKEN SEAL/SRC/SOUND/MUSIC_PLAYER_STEP_VOLUME_AND_PITCH_TOWARD_TARGETS.o"(.text)
        "*/games/THE BROKEN SEAL/SRC/SOUND/SOUND.o"(.text)
        "*/games/THE BROKEN SEAL/SRC/SOUND/DRIVER/UMUL_HIGH.o"(.text .rodata .data .padding)
        "*/games/THE BROKEN SEAL/SRC/SOUND/DRIVER/MIXER_ENTRY.o"(.text .rodata .data .padding)
    } > ROM
    /* The sound mixer runs from the top of IWRAM. */
    .iwram_mixer 0x3007000 :
    {
        "*/games/THE BROKEN SEAL/SRC/SOUND/DRIVER/MIXER.o"(.text .rodata .data .padding)
    } > IWRAM AT>ROM
    iwram_high (NOLOAD) : { "*/recon/tbs/sym_iwram_high.o"(.sym_iwram_high) } > IWRAM
    .rom_tail :
    {
        "*/games/THE BROKEN SEAL/SRC/SOUND/DRIVER/CLEAR_BUFFER.o"(.text .rodata .data .padding)
        "*/games/THE BROKEN SEAL/SRC/SOUND/DRIVER/CLEAR_CHAIN.o"(.text .rodata .data .padding)
        "*/games/THE BROKEN SEAL/SRC/SOUND/DRIVER/SEQUENCE_COMMANDS.o"(.text .rodata .data .padding)
        "*/games/THE BROKEN SEAL/SRC/SOUND/DRIVER/UPDATE.o"(.text .rodata .data .padding)
        "*/games/THE BROKEN SEAL/SRC/SOUND/DRIVER/TRACK_STOP.o"(.text .rodata .data .padding)
        "*/games/THE BROKEN SEAL/SRC/SOUND/DRIVER/CALCULATE_STEREO_VOLUME.o"(.text .rodata .data .padding)
        "*/games/THE BROKEN SEAL/SRC/SOUND/DRIVER/HANDLE_NOTE.o"(.text .rodata .data .padding)
        "*/games/THE BROKEN SEAL/SRC/SOUND/DRIVER/RELEASE_KEY.o"(.text .rodata .data .padding)
        "*/games/THE BROKEN SEAL/SRC/SOUND/DRIVER/CLEAR_MODULATION.o"(.text .rodata .data .padding)
        "*/games/THE BROKEN SEAL/SRC/SOUND/DRIVER/COMMAND_BYTE_READER.o"(.text .rodata .data .padding)
        "*/recon/tbs/raw/080fa1d2.o"(.text .rodata .data .padding)
        "*/games/THE BROKEN SEAL/SRC/SOUND/DRIVER/COMMAND_BYTE_SETTERS.o"(.text .rodata .data .padding)
        "*/games/COMMON/SRC/SOUND/PCM_KEY_TO_FREQUENCY.o"(.text)
        "*/recon/tbs/raw/080fa262.o"(.text .rodata .data .padding)
        "*/games/COMMON/SRC/SOUND/SOUND.o"(.text)
        "*/games/THE BROKEN SEAL/SRC/SYSTEM/SOUND_GET_JUMP_LIST.o"(.text .rodata .data .padding)
        "*/games/THE BROKEN SEAL/SRC/SOUND/COMMAND_INVOKE_SLOT34.o"(.text)
        "*/games/THE BROKEN SEAL/SRC/SOUND/COMMAND_INVOKE_SLOT35.o"(.text)
        "*/games/COMMON/SRC/SOUND/SOUND2.o"(.text)
        "*/recon/tbs/raw/080fb2a2.o"(.text .rodata .data .padding)
        "*/games/COMMON/SRC/SOUND/SOUND3.o"(.text)
        "*/recon/tbs/raw/080fb42e.o"(.text .rodata .data .padding)
        "*/games/COMMON/SRC/SOUND/SOUND4.o"(.text)
        "*/games/THE BROKEN SEAL/SRC/SOUND/MUSIC_TRACK_OPERATE_WORK_BYTE.o"(.text)
        "*/games/COMMON/SRC/SOUND/MUSIC_TRACK_DISPATCH_STREAM_COMMAND.o"(.text)
        "*/games/THE BROKEN SEAL/SRC/SYSTEM/SCHEDULER/CALL_WORK_ENTRY_WITH_ARGS.o"(.text)
        "*/games/COMMON/SRC/SOUND/MUSIC_TRACK_READ_VOICE_TARGET.o"(.text)
        "*/games/THE BROKEN SEAL/SRC/SOUND/MUSIC_TRACK_SET_VOICE_KIND.o"(.text)
        "*/recon/tbs/raw/080fb6fe.o"(.text .rodata .data .padding)
        "*/games/THE BROKEN SEAL/SRC/SOUND/MUSIC_TRACK_SET_VOICE_ATTACK.o"(.text)
        "*/recon/tbs/raw/080fb712.o"(.text .rodata .data .padding)
        "*/games/COMMON/SRC/SOUND/MUSIC_TRACK_SET_VOICE_DECAY.o"(.text)
        "*/recon/tbs/raw/080fb726.o"(.text .rodata .data .padding)
        "*/games/COMMON/SRC/SOUND/MUSIC_TRACK_SET_VOICE_SUSTAIN.o"(.text)
        "*/recon/tbs/raw/080fb73a.o"(.text .rodata .data .padding)
        "*/games/COMMON/SRC/SOUND/MUSIC_TRACK_SET_VOICE_RELEASE.o"(.text)
        "*/recon/tbs/raw/080fb74e.o"(.text .rodata .data .padding)
        "*/games/COMMON/SRC/SOUND/SOUND5.o"(.text)
        "*/games/THE BROKEN SEAL/SRC/SOUND/MUSIC_TRACK_SET_VOICE_LENGTH.o"(.text)
        "*/recon/tbs/raw/080fb77a.o"(.text .rodata .data .padding)
        "*/games/THE BROKEN SEAL/SRC/SOUND/MUSIC_TRACK_SET_VOICE_PAN_OR_SWEEP.o"(.text)
        "*/recon/tbs/raw/080fb78e.o"(.text .rodata .data .padding)
        "*/games/THE BROKEN SEAL/SRC/SOUND/EMPTY_CALLBACK.o"(.text)
        "*/games/THE BROKEN SEAL/SRC/SOUND/SOUND.o"(.rodata)
        "*/recon/tbs/unidentified.o"(.unidentified.080fb7a0)
        "*/games/THE BROKEN SEAL/SOUND/VOICES.o"(.rodata)
        "*/recon/tbs/unidentified.o"(.unidentified.080fc504)
        "*/games/THE BROKEN SEAL/SOUND/CGB_WAVES.o"(.rodata)
        "*/recon/tbs/unidentified.o"(.unidentified.080fc624)
        "*/games/THE BROKEN SEAL/SOUND/SONGS.o"(.rodata)
        "*/games/THE BROKEN SEAL/SOUND/SAMPLES.o"(.rodata)
        "*/games/THE BROKEN SEAL/SOUND/SEQUENCE/BGM_000.o"(.rodata)
        "*/games/THE BROKEN SEAL/SOUND/SEQUENCE/BGM_001.o"(.rodata)
        "*/games/THE BROKEN SEAL/SOUND/SEQUENCE/BGM_002.o"(.rodata)
        "*/games/THE BROKEN SEAL/SOUND/SEQUENCE/BGM_003.o"(.rodata)
        "*/games/THE BROKEN SEAL/SOUND/SEQUENCE/BGM_004.o"(.rodata)
        "*/games/THE BROKEN SEAL/SOUND/SEQUENCE/BGM_005.o"(.rodata)
        "*/games/THE BROKEN SEAL/SOUND/SEQUENCE/BGM_006.o"(.rodata)
        "*/games/THE BROKEN SEAL/SOUND/SEQUENCE/BGM_007.o"(.rodata)
        "*/games/THE BROKEN SEAL/SOUND/SEQUENCE/BGM_008.o"(.rodata)
        "*/games/THE BROKEN SEAL/SOUND/SEQUENCE/BGM_009.o"(.rodata)
        "*/games/THE BROKEN SEAL/SOUND/SEQUENCE/BGM_010.o"(.rodata)
        "*/games/THE BROKEN SEAL/SOUND/SEQUENCE/BGM_019.o"(.rodata)
        "*/games/THE BROKEN SEAL/SOUND/SEQUENCE/BGM_020.o"(.rodata)
        "*/games/THE BROKEN SEAL/SOUND/SEQUENCE/BGM_021.o"(.rodata)
        "*/games/THE BROKEN SEAL/SOUND/SEQUENCE/BGM_022.o"(.rodata)
        "*/games/THE BROKEN SEAL/SOUND/SEQUENCE/BGM_023.o"(.rodata)
        "*/games/THE BROKEN SEAL/SOUND/SEQUENCE/BGM_024.o"(.rodata)
        "*/games/THE BROKEN SEAL/SOUND/SEQUENCE/BGM_025.o"(.rodata)
        "*/games/THE BROKEN SEAL/SOUND/SEQUENCE/BGM_026.o"(.rodata)
        "*/games/THE BROKEN SEAL/SOUND/SEQUENCE/BGM_027.o"(.rodata)
        "*/games/THE BROKEN SEAL/SOUND/SEQUENCE/BGM_028.o"(.rodata)
        "*/games/THE BROKEN SEAL/SOUND/SEQUENCE/BGM_029.o"(.rodata)
        "*/games/THE BROKEN SEAL/SOUND/SEQUENCE/BGM_030.o"(.rodata)
        "*/games/THE BROKEN SEAL/SOUND/SEQUENCE/BGM_040.o"(.rodata)
        "*/games/THE BROKEN SEAL/SOUND/SEQUENCE/BGM_041.o"(.rodata)
        "*/games/THE BROKEN SEAL/SOUND/SEQUENCE/BGM_042.o"(.rodata)
        "*/games/THE BROKEN SEAL/SOUND/SEQUENCE/BGM_043.o"(.rodata)
        "*/games/THE BROKEN SEAL/SOUND/SEQUENCE/BGM_050.o"(.rodata)
        "*/games/THE BROKEN SEAL/SOUND/SEQUENCE/BGM_051.o"(.rodata)
        "*/games/THE BROKEN SEAL/SOUND/SEQUENCE/BGM_052.o"(.rodata)
        "*/games/THE BROKEN SEAL/SOUND/SEQUENCE/BGM_053.o"(.rodata)
        "*/games/THE BROKEN SEAL/SOUND/SEQUENCE/BGM_054.o"(.rodata)
        "*/games/THE BROKEN SEAL/SOUND/SEQUENCE/BGM_055.o"(.rodata)
        "*/games/THE BROKEN SEAL/SOUND/SEQUENCE/BGM_058.o"(.rodata)
        "*/games/THE BROKEN SEAL/SOUND/SEQUENCE/BGM_059.o"(.rodata)
        "*/games/THE BROKEN SEAL/SOUND/SEQUENCE/BGM_060.o"(.rodata)
        "*/games/THE BROKEN SEAL/SOUND/SEQUENCE/BGM_061.o"(.rodata)
        "*/games/THE BROKEN SEAL/SOUND/SEQUENCE/BGM_062.o"(.rodata)
        "*/games/THE BROKEN SEAL/SOUND/SEQUENCE/BGM_063.o"(.rodata)
        "*/games/THE BROKEN SEAL/SOUND/SEQUENCE/BGM_064.o"(.rodata)
        "*/games/THE BROKEN SEAL/SOUND/SEQUENCE/BGM_067.o"(.rodata)
        "*/games/THE BROKEN SEAL/SOUND/SEQUENCE/BGM_070.o"(.rodata)
        "*/games/THE BROKEN SEAL/SOUND/SEQUENCE/BGM_072.o"(.rodata)
        "*/games/THE BROKEN SEAL/SOUND/SEQUENCE/BGM_074.o"(.rodata)
        "*/games/THE BROKEN SEAL/SOUND/SEQUENCE/BGM_075.o"(.rodata)
        "*/games/THE BROKEN SEAL/SOUND/SEQUENCE/BGM_076.o"(.rodata)
        "*/games/THE BROKEN SEAL/SOUND/SEQUENCE/BGM_080.o"(.rodata)
        "*/games/THE BROKEN SEAL/SOUND/SEQUENCE/BGM_081.o"(.rodata)
        "*/games/THE BROKEN SEAL/SOUND/SEQUENCE/BGM_082.o"(.rodata)
        "*/games/THE BROKEN SEAL/SOUND/SEQUENCE/BGM_083.o"(.rodata)
        "*/games/THE BROKEN SEAL/SOUND/SEQUENCE/BGM_084.o"(.rodata)
        "*/games/THE BROKEN SEAL/SOUND/SEQUENCE/BGM_085.o"(.rodata)
        "*/games/THE BROKEN SEAL/SOUND/SEQUENCE/BGM_086.o"(.rodata)
        "*/games/THE BROKEN SEAL/SOUND/SEQUENCE/BGM_087.o"(.rodata)
        "*/games/THE BROKEN SEAL/SOUND/SEQUENCE/BGM_088.o"(.rodata)
        "*/games/THE BROKEN SEAL/SOUND/SEQUENCE/BGM_089.o"(.rodata)
        "*/games/THE BROKEN SEAL/SOUND/SEQUENCE/BGM_091.o"(.rodata)
        "*/games/THE BROKEN SEAL/SOUND/SEQUENCE/BGM_092.o"(.rodata)
        "*/games/THE BROKEN SEAL/SOUND/SEQUENCE/BGM_093.o"(.rodata)
        "*/games/THE BROKEN SEAL/SOUND/SEQUENCE/BGM_095.o"(.rodata)
        "*/games/THE BROKEN SEAL/SOUND/SEQUENCE/SE_100.o"(.rodata)
        "*/games/THE BROKEN SEAL/SOUND/SEQUENCE/SE_SHOP_PURCHASE.o"(.rodata)
        "*/games/THE BROKEN SEAL/SOUND/SEQUENCE/SE_102.o"(.rodata)
        "*/games/THE BROKEN SEAL/SOUND/SEQUENCE/SE_103.o"(.rodata)
        "*/games/THE BROKEN SEAL/SOUND/SEQUENCE/SE_104.o"(.rodata)
        "*/games/THE BROKEN SEAL/SOUND/SEQUENCE/SE_105.o"(.rodata)
        "*/games/THE BROKEN SEAL/SOUND/SEQUENCE/SE_106.o"(.rodata)
        "*/games/THE BROKEN SEAL/SOUND/SEQUENCE/SE_107.o"(.rodata)
        "*/games/THE BROKEN SEAL/SOUND/SEQUENCE/SE_TRIPLE_TONE_LOW.o"(.rodata)
        "*/games/THE BROKEN SEAL/SOUND/SEQUENCE/SE_TRIPLE_TONE_HIGH.o"(.rodata)
        "*/games/THE BROKEN SEAL/SOUND/SEQUENCE/SE_110.o"(.rodata)
        "*/games/THE BROKEN SEAL/SOUND/SEQUENCE/SE_MENU_CURSOR.o"(.rodata)
        "*/games/THE BROKEN SEAL/SOUND/SEQUENCE/SE_MENU_OK.o"(.rodata)
        "*/games/THE BROKEN SEAL/SOUND/SEQUENCE/SE_MENU_CANCEL.o"(.rodata)
        "*/games/THE BROKEN SEAL/SOUND/SEQUENCE/SE_MENU_ERROR.o"(.rodata)
        "*/games/THE BROKEN SEAL/SOUND/SEQUENCE/SE_115.o"(.rodata)
        "*/games/THE BROKEN SEAL/SOUND/SEQUENCE/SE_116.o"(.rodata)
        "*/games/THE BROKEN SEAL/SOUND/SEQUENCE/SE_117.o"(.rodata)
        "*/games/THE BROKEN SEAL/SOUND/SEQUENCE/SE_118.o"(.rodata)
        "*/games/THE BROKEN SEAL/SOUND/SEQUENCE/SE_119.o"(.rodata)
        "*/games/THE BROKEN SEAL/SOUND/SEQUENCE/SE_120.o"(.rodata)
        "*/games/THE BROKEN SEAL/SOUND/SEQUENCE/SE_121.o"(.rodata)
        "*/games/THE BROKEN SEAL/SOUND/SEQUENCE/SE_122.o"(.rodata)
        "*/games/THE BROKEN SEAL/SOUND/SEQUENCE/SE_123.o"(.rodata)
        "*/games/THE BROKEN SEAL/SOUND/SEQUENCE/SE_124.o"(.rodata)
        "*/games/THE BROKEN SEAL/SOUND/SEQUENCE/SE_125.o"(.rodata)
        "*/games/THE BROKEN SEAL/SOUND/SEQUENCE/SE_RECOVERY.o"(.rodata)
        "*/games/THE BROKEN SEAL/SOUND/SEQUENCE/SE_127.o"(.rodata)
        "*/games/THE BROKEN SEAL/SOUND/SEQUENCE/SE_128.o"(.rodata)
        "*/games/THE BROKEN SEAL/SOUND/SEQUENCE/SE_129.o"(.rodata)
        "*/games/THE BROKEN SEAL/SOUND/SEQUENCE/SE_130.o"(.rodata)
        "*/games/THE BROKEN SEAL/SOUND/SEQUENCE/SE_131.o"(.rodata)
        "*/games/THE BROKEN SEAL/SOUND/SEQUENCE/SE_132.o"(.rodata)
        "*/games/THE BROKEN SEAL/SOUND/SEQUENCE/SE_133.o"(.rodata)
        "*/games/THE BROKEN SEAL/SOUND/SEQUENCE/SE_HEAVY_IMPACT.o"(.rodata)
        "*/games/THE BROKEN SEAL/SOUND/SEQUENCE/SE_135.o"(.rodata)
        "*/games/THE BROKEN SEAL/SOUND/SEQUENCE/SE_136.o"(.rodata)
        "*/games/THE BROKEN SEAL/SOUND/SEQUENCE/SE_137.o"(.rodata)
        "*/games/THE BROKEN SEAL/SOUND/SEQUENCE/SE_ITEM_BREAK.o"(.rodata)
        "*/games/THE BROKEN SEAL/SOUND/SEQUENCE/SE_139.o"(.rodata)
        "*/games/THE BROKEN SEAL/SOUND/SEQUENCE/SE_140.o"(.rodata)
        "*/games/THE BROKEN SEAL/SOUND/SEQUENCE/SE_141.o"(.rodata)
        "*/games/THE BROKEN SEAL/SOUND/SEQUENCE/SE_142.o"(.rodata)
        "*/games/THE BROKEN SEAL/SOUND/SEQUENCE/SE_143.o"(.rodata)
        "*/games/THE BROKEN SEAL/SOUND/SEQUENCE/SE_144.o"(.rodata)
        "*/games/THE BROKEN SEAL/SOUND/SEQUENCE/SE_145.o"(.rodata)
        "*/games/THE BROKEN SEAL/SOUND/SEQUENCE/SE_146.o"(.rodata)
        "*/games/THE BROKEN SEAL/SOUND/SEQUENCE/SE_147.o"(.rodata)
        "*/games/THE BROKEN SEAL/SOUND/SEQUENCE/SE_148.o"(.rodata)
        "*/games/THE BROKEN SEAL/SOUND/SEQUENCE/SE_149.o"(.rodata)
        "*/games/THE BROKEN SEAL/SOUND/SEQUENCE/SE_150.o"(.rodata)
        "*/games/THE BROKEN SEAL/SOUND/SEQUENCE/SE_151.o"(.rodata)
        "*/games/THE BROKEN SEAL/SOUND/SEQUENCE/SE_152.o"(.rodata)
        "*/games/THE BROKEN SEAL/SOUND/SEQUENCE/SE_153.o"(.rodata)
        "*/games/THE BROKEN SEAL/SOUND/SEQUENCE/SE_154.o"(.rodata)
        "*/games/THE BROKEN SEAL/SOUND/SEQUENCE/SE_155.o"(.rodata)
        "*/games/THE BROKEN SEAL/SOUND/SEQUENCE/SE_156.o"(.rodata)
        "*/games/THE BROKEN SEAL/SOUND/SEQUENCE/SE_157.o"(.rodata)
        "*/games/THE BROKEN SEAL/SOUND/SEQUENCE/SE_158.o"(.rodata)
        "*/games/THE BROKEN SEAL/SOUND/SEQUENCE/SE_159.o"(.rodata)
        "*/games/THE BROKEN SEAL/SOUND/SEQUENCE/SE_160.o"(.rodata)
        "*/games/THE BROKEN SEAL/SOUND/SEQUENCE/SE_161.o"(.rodata)
        "*/games/THE BROKEN SEAL/SOUND/SEQUENCE/SE_162.o"(.rodata)
        "*/games/THE BROKEN SEAL/SOUND/SEQUENCE/SE_163.o"(.rodata)
        "*/games/THE BROKEN SEAL/SOUND/SEQUENCE/SE_164.o"(.rodata)
        "*/games/THE BROKEN SEAL/SOUND/SEQUENCE/SE_165.o"(.rodata)
        "*/games/THE BROKEN SEAL/SOUND/SEQUENCE/SE_166.o"(.rodata)
        "*/games/THE BROKEN SEAL/SOUND/SEQUENCE/SE_SCENE_TRANSITION.o"(.rodata)
        "*/games/THE BROKEN SEAL/SOUND/SEQUENCE/SE_168.o"(.rodata)
        "*/games/THE BROKEN SEAL/SOUND/SEQUENCE/SE_169.o"(.rodata)
        "*/games/THE BROKEN SEAL/SOUND/SEQUENCE/SE_170.o"(.rodata)
        "*/games/THE BROKEN SEAL/SOUND/SEQUENCE/SE_171.o"(.rodata)
        "*/games/THE BROKEN SEAL/SOUND/SEQUENCE/SE_172.o"(.rodata)
        "*/games/THE BROKEN SEAL/SOUND/SEQUENCE/SE_173.o"(.rodata)
        "*/games/THE BROKEN SEAL/SOUND/SEQUENCE/SE_174.o"(.rodata)
        "*/games/THE BROKEN SEAL/SOUND/SEQUENCE/SE_175.o"(.rodata)
        "*/games/THE BROKEN SEAL/SOUND/SEQUENCE/SE_176.o"(.rodata)
        "*/games/THE BROKEN SEAL/SOUND/SEQUENCE/SE_177.o"(.rodata)
        "*/games/THE BROKEN SEAL/SOUND/SEQUENCE/SE_178.o"(.rodata)
        "*/games/THE BROKEN SEAL/SOUND/SEQUENCE/SE_179.o"(.rodata)
        "*/games/THE BROKEN SEAL/SOUND/SEQUENCE/SE_180.o"(.rodata)
        "*/games/THE BROKEN SEAL/SOUND/SEQUENCE/SE_181.o"(.rodata)
        "*/games/THE BROKEN SEAL/SOUND/SEQUENCE/SE_182.o"(.rodata)
        "*/games/THE BROKEN SEAL/SOUND/SEQUENCE/SE_183.o"(.rodata)
        "*/games/THE BROKEN SEAL/SOUND/SEQUENCE/SE_184.o"(.rodata)
        "*/games/THE BROKEN SEAL/SOUND/SEQUENCE/SE_185.o"(.rodata)
        "*/games/THE BROKEN SEAL/SOUND/SEQUENCE/SE_186.o"(.rodata)
        "*/games/THE BROKEN SEAL/SOUND/SEQUENCE/SE_187.o"(.rodata)
        "*/games/THE BROKEN SEAL/SOUND/SEQUENCE/SE_188.o"(.rodata)
        "*/games/THE BROKEN SEAL/SOUND/SEQUENCE/SE_189.o"(.rodata)
        "*/games/THE BROKEN SEAL/SOUND/SEQUENCE/SE_190.o"(.rodata)
        "*/games/THE BROKEN SEAL/SOUND/SEQUENCE/SE_191.o"(.rodata)
        "*/games/THE BROKEN SEAL/SOUND/SEQUENCE/SE_192.o"(.rodata)
        "*/games/THE BROKEN SEAL/SOUND/SEQUENCE/SE_193.o"(.rodata)
        "*/games/THE BROKEN SEAL/SOUND/SEQUENCE/SE_194.o"(.rodata)
        "*/games/THE BROKEN SEAL/SOUND/SEQUENCE/SE_195.o"(.rodata)
        "*/games/THE BROKEN SEAL/SOUND/SEQUENCE/SE_196.o"(.rodata)
        "*/games/THE BROKEN SEAL/SOUND/SEQUENCE/SE_197.o"(.rodata)
        "*/games/THE BROKEN SEAL/SOUND/SEQUENCE/SE_198.o"(.rodata)
        "*/games/THE BROKEN SEAL/SOUND/SEQUENCE/SE_199.o"(.rodata)
        "*/games/THE BROKEN SEAL/SOUND/SEQUENCE/SE_200.o"(.rodata)
        "*/games/THE BROKEN SEAL/SOUND/SEQUENCE/SE_201.o"(.rodata)
        "*/games/THE BROKEN SEAL/SOUND/SEQUENCE/SE_202.o"(.rodata)
        "*/games/THE BROKEN SEAL/SOUND/SEQUENCE/SE_203.o"(.rodata)
        "*/games/THE BROKEN SEAL/SOUND/SEQUENCE/SE_204.o"(.rodata)
        "*/games/THE BROKEN SEAL/SOUND/SEQUENCE/SE_205.o"(.rodata)
        "*/games/THE BROKEN SEAL/SOUND/SEQUENCE/SE_206.o"(.rodata)
        "*/games/THE BROKEN SEAL/SOUND/SEQUENCE/SE_208.o"(.rodata)
        "*/games/THE BROKEN SEAL/SOUND/SEQUENCE/SE_209.o"(.rodata)
        "*/games/THE BROKEN SEAL/SOUND/SEQUENCE/SE_210.o"(.rodata)
        "*/games/THE BROKEN SEAL/SOUND/SEQUENCE/SE_211.o"(.rodata)
        "*/games/THE BROKEN SEAL/SOUND/SEQUENCE/SE_212.o"(.rodata)
        "*/games/THE BROKEN SEAL/SOUND/SEQUENCE/SE_213.o"(.rodata)
        "*/games/THE BROKEN SEAL/SOUND/SEQUENCE/SE_214.o"(.rodata)
        "*/games/THE BROKEN SEAL/SOUND/SEQUENCE/SE_215.o"(.rodata)
        "*/games/THE BROKEN SEAL/SOUND/SEQUENCE/SE_216.o"(.rodata)
        "*/games/THE BROKEN SEAL/SOUND/SEQUENCE/SE_217.o"(.rodata)
        "*/games/THE BROKEN SEAL/SOUND/SEQUENCE/SE_218.o"(.rodata)
        "*/games/THE BROKEN SEAL/SOUND/SEQUENCE/SE_219.o"(.rodata)
        "*/games/THE BROKEN SEAL/SOUND/SEQUENCE/SE_220.o"(.rodata)
        "*/games/THE BROKEN SEAL/SOUND/SEQUENCE/SE_221.o"(.rodata)
        "*/games/THE BROKEN SEAL/SOUND/SEQUENCE/SE_222.o"(.rodata)
        "*/games/THE BROKEN SEAL/SOUND/SEQUENCE/SE_223.o"(.rodata)
        "*/games/THE BROKEN SEAL/SOUND/SEQUENCE/SE_224.o"(.rodata)
        "*/games/THE BROKEN SEAL/SOUND/SEQUENCE/SE_225.o"(.rodata)
        "*/games/THE BROKEN SEAL/SOUND/SEQUENCE/SE_226.o"(.rodata)
        "*/games/THE BROKEN SEAL/SOUND/SEQUENCE/SE_227.o"(.rodata)
        "*/games/THE BROKEN SEAL/SOUND/SEQUENCE/SE_228.o"(.rodata)
        "*/games/THE BROKEN SEAL/SOUND/SEQUENCE/SE_229.o"(.rodata)
        "*/games/THE BROKEN SEAL/SOUND/SEQUENCE/SE_230.o"(.rodata)
        "*/games/THE BROKEN SEAL/SOUND/SEQUENCE/SE_231.o"(.rodata)
        "*/games/THE BROKEN SEAL/SOUND/SEQUENCE/SE_232.o"(.rodata)
        "*/games/THE BROKEN SEAL/SOUND/SEQUENCE/SE_233.o"(.rodata)
        "*/games/THE BROKEN SEAL/SOUND/SEQUENCE/SE_234.o"(.rodata)
        "*/games/THE BROKEN SEAL/SOUND/SEQUENCE/SE_235.o"(.rodata)
        "*/games/THE BROKEN SEAL/SOUND/SEQUENCE/SE_236.o"(.rodata)
        "*/games/THE BROKEN SEAL/SOUND/SEQUENCE/SE_237.o"(.rodata)
        "*/games/THE BROKEN SEAL/SOUND/SEQUENCE/SE_238.o"(.rodata)
        "*/games/THE BROKEN SEAL/SOUND/SEQUENCE/SE_239.o"(.rodata)
        "*/games/THE BROKEN SEAL/SOUND/SEQUENCE/SE_240.o"(.rodata)
        "*/games/THE BROKEN SEAL/SOUND/SEQUENCE/SE_241.o"(.rodata)
        "*/games/THE BROKEN SEAL/SOUND/SEQUENCE/SE_242.o"(.rodata)
        "*/games/THE BROKEN SEAL/SOUND/SEQUENCE/SE_243.o"(.rodata)
        "*/games/THE BROKEN SEAL/SOUND/SEQUENCE/SE_244.o"(.rodata)
        "*/games/THE BROKEN SEAL/SOUND/SEQUENCE/SE_245.o"(.rodata)
        "*/games/THE BROKEN SEAL/SOUND/SEQUENCE/SE_246.o"(.rodata)
        "*/games/THE BROKEN SEAL/SOUND/SEQUENCE/SE_247.o"(.rodata)
        "*/games/THE BROKEN SEAL/SOUND/SEQUENCE/SE_248.o"(.rodata)
        "*/games/THE BROKEN SEAL/SOUND/SEQUENCE/SE_249.o"(.rodata)
        "*/games/THE BROKEN SEAL/SOUND/SEQUENCE/SE_250.o"(.rodata)
        "*/games/THE BROKEN SEAL/SOUND/SEQUENCE/SE_251.o"(.rodata)
        "*/games/THE BROKEN SEAL/SOUND/SEQUENCE/SE_252.o"(.rodata)
        "*/games/THE BROKEN SEAL/SOUND/SEQUENCE/SE_253.o"(.rodata)
        "*/games/THE BROKEN SEAL/SOUND/SEQUENCE/SE_256.o"(.rodata)
        "*/games/THE BROKEN SEAL/SOUND/SEQUENCE/SE_257.o"(.rodata)
        "*/games/THE BROKEN SEAL/SOUND/SEQUENCE/SE_258.o"(.rodata)
        "*/games/THE BROKEN SEAL/SOUND/SEQUENCE/SE_259.o"(.rodata)
        "*/games/THE BROKEN SEAL/SOUND/SEQUENCE/SE_260.o"(.rodata)
        "*/games/THE BROKEN SEAL/SOUND/SEQUENCE/SE_261.o"(.rodata)
        "*/games/THE BROKEN SEAL/SOUND/SEQUENCE/SE_262.o"(.rodata)
        "*/games/THE BROKEN SEAL/SOUND/SEQUENCE/SE_263.o"(.rodata)
        "*/games/THE BROKEN SEAL/SOUND/SEQUENCE/SE_264.o"(.rodata)
        "*/games/THE BROKEN SEAL/SOUND/SEQUENCE/SE_265.o"(.rodata)
        "*/games/THE BROKEN SEAL/SOUND/SEQUENCE/SE_266.o"(.rodata)
        "*/games/THE BROKEN SEAL/SOUND/SEQUENCE/SE_267.o"(.rodata)
        "*/games/THE BROKEN SEAL/SOUND/SEQUENCE/SE_268.o"(.rodata)
        "*/games/THE BROKEN SEAL/SOUND/SEQUENCE/SE_269.o"(.rodata)
        "*/games/THE BROKEN SEAL/SOUND/SEQUENCE/SE_270.o"(.rodata)
        "*/games/THE BROKEN SEAL/SOUND/SEQUENCE/SE_271.o"(.rodata)
        "*/games/THE BROKEN SEAL/SOUND/SEQUENCE/SE_272.o"(.rodata)
        "*/games/THE BROKEN SEAL/SOUND/SEQUENCE/SE_273.o"(.rodata)
        "*/games/THE BROKEN SEAL/SOUND/SEQUENCE/SE_274.o"(.rodata)
        "*/games/THE BROKEN SEAL/SOUND/SEQUENCE/SE_275.o"(.rodata)
        "*/games/THE BROKEN SEAL/SOUND/SEQUENCE/SE_276.o"(.rodata)
        "*/games/THE BROKEN SEAL/SOUND/SEQUENCE/SE_277.o"(.rodata)
        "*/games/THE BROKEN SEAL/SOUND/SEQUENCE/SE_278.o"(.rodata)
        "*/games/THE BROKEN SEAL/SOUND/SEQUENCE/SE_279.o"(.rodata)
        "*/games/THE BROKEN SEAL/SOUND/SEQUENCE/SE_280.o"(.rodata)
        "*/games/THE BROKEN SEAL/SOUND/SEQUENCE/SE_281.o"(.rodata)
        "*/games/THE BROKEN SEAL/SOUND/SEQUENCE/SE_282.o"(.rodata)
        "*/games/THE BROKEN SEAL/SOUND/SEQUENCE/SE_283.o"(.rodata)
        "*/games/THE BROKEN SEAL/SOUND/SEQUENCE/SE_284.o"(.rodata)
        "*/games/THE BROKEN SEAL/SOUND/SEQUENCE/SE_285.o"(.rodata)
        "*/games/THE BROKEN SEAL/SOUND/SEQUENCE/SE_286.o"(.rodata)
        "*/games/THE BROKEN SEAL/SOUND/SEQUENCE/SE_287.o"(.rodata)
        "*/games/THE BROKEN SEAL/SOUND/SEQUENCE/SE_288.o"(.rodata)
        "*/games/THE BROKEN SEAL/SOUND/SEQUENCE/SE_289.o"(.rodata)
        "*/games/THE BROKEN SEAL/SOUND/SEQUENCE/SE_290.o"(.rodata)
        "*/games/THE BROKEN SEAL/SOUND/SEQUENCE/SE_291.o"(.rodata)
        "*/games/THE BROKEN SEAL/SOUND/SEQUENCE/SE_292.o"(.rodata)
        "*/games/THE BROKEN SEAL/SOUND/SEQUENCE/SE_293.o"(.rodata)
        "*/games/THE BROKEN SEAL/SOUND/SEQUENCE/SE_298.o"(.rodata)
        "*/games/THE BROKEN SEAL/SOUND/SEQUENCE/SE_300.o"(.rodata)
        "*/games/THE BROKEN SEAL/SOUND/SEQUENCE/SE_301.o"(.rodata)
        "*/games/THE BROKEN SEAL/SOUND/SEQUENCE/SE_302.o"(.rodata)
        "*/games/THE BROKEN SEAL/SOUND/SEQUENCE/SE_303.o"(.rodata)
        "*/games/THE BROKEN SEAL/SOUND/SEQUENCE/SE_304.o"(.rodata)
        "*/games/THE BROKEN SEAL/SOUND/SEQUENCE/SE_305.o"(.rodata)
        "*/games/THE BROKEN SEAL/SOUND/SEQUENCE/SE_306.o"(.rodata)
        "*/games/THE BROKEN SEAL/SOUND/SEQUENCE/SE_307.o"(.rodata)
        "*/games/THE BROKEN SEAL/SOUND/SEQUENCE/SE_308.o"(.rodata)
        "*/games/THE BROKEN SEAL/SOUND/SEQUENCE/SE_309.o"(.rodata)
        "*/games/THE BROKEN SEAL/SOUND/SEQUENCE/SE_310.o"(.rodata)
        "*/games/THE BROKEN SEAL/SOUND/SEQUENCE/SE_311.o"(.rodata)
        "*/recon/tbs/unidentified.o"(.unidentified.08184698)
        "*/games/THE BROKEN SEAL/SRC/SYSTEM/FAR_CALL/RESOURCE.o"(.text .rodata .data .padding)
        "*/games/THE BROKEN SEAL/SRC/SYSTEM/RESOURCE/METADATA_GET_RECORD.o"(.text)
        "*/games/THE BROKEN SEAL/SRC/GRAPHICS/SPRITE/SPRITES.o"(.rodata)
        "*/games/THE BROKEN SEAL/SRC/GRAPHICS/ANIMREF0.o"(.text .rodata .data .padding)
        "*/games/THE BROKEN SEAL/SRC/GRAPHICS/SPRITE/SPRITES.o"(.rodata.a)
        "*/games/THE BROKEN SEAL/SRC/GRAPHICS/ANIMREF1.o"(.text .rodata .data .padding)
        "*/games/THE BROKEN SEAL/SRC/GRAPHICS/ANIMREF2.o"(.text .rodata .data .padding)
        "*/games/THE BROKEN SEAL/SRC/GRAPHICS/SPRITE/SPRITES.o"(.rodata.b)
        "*/recon/tbs/unidentified.o"(.unidentified.0831efd8)
        "*/games/THE BROKEN SEAL/SRC/SYSTEM/RESOURCE/DIRECTORY.o"(.rodata)
        "*/recon/tbs/unidentified.o"(.unidentified.083203c8)
        "*/games/COMMON/SRC/GRAPHICS/UI/WINDOW_TILES.o"(.rodata)
        "*/games/COMMON/SRC/GRAPHICS/UI/SMALL_FONT.o"(.rodata)
        "*/games/THE BROKEN SEAL/SRC/GRAPHICS/TITLE/INTRO_SUN.o"(.rodata)
        "*/recon/tbs/unidentified.o"(.unidentified.083249e7)
        "*/games/THE BROKEN SEAL/SRC/GRAPHICS/TITLE/SCREEN.o"(.rodata)
        "*/recon/tbs/unidentified.o"(.unidentified.0832b0a6)
        "*/games/THE BROKEN SEAL/SRC/GRAPHICS/TITLE/NINTENDO_SPLASH.o"(.rodata)
        "*/games/THE BROKEN SEAL/SRC/GRAPHICS/TITLE/CAMELOT_LOGO.o"(.rodata)
        "*/recon/tbs/unidentified.o"(.unidentified.083357f1)
        "*/games/THE BROKEN SEAL/SRC/GRAPHICS/TITLE/GOLDEN_SUN.o"(.rodata)
        "*/recon/tbs/unidentified.o"(.unidentified.08337101)
        "*/games/THE BROKEN SEAL/SRC/GRAPHICS/WORLD_MAP/PICTURE.o"(.rodata)
        "*/recon/tbs/unidentified.o"(.unidentified.0833ac05)
        "*/games/COMMON/SRC/GRAPHICS/BACKDROP/SUHARA_GATE.o"(.rodata)
        "*/recon/tbs/unidentified.o"(.unidentified.0833f2fe)
        "*/games/COMMON/SRC/GRAPHICS/BACKDROP/TAKARA_SHIMA.o"(.rodata)
        "*/games/COMMON/SRC/GRAPHICS/BACKDROP/TAKARA_SHIMA_CAVE.o"(.rodata)
        "*/games/COMMON/SRC/GRAPHICS/BACKDROP/KOROSSEO.o"(.rodata)
        "*/games/COMMON/SRC/GRAPHICS/BACKDROP/VINASU_CHOJO_STORM.o"(.rodata)
        "*/recon/tbs/unidentified.o"(.unidentified.0834fa6e)
        "*/games/COMMON/SRC/GRAPHICS/BACKDROP/VINASU_CHOJO.o"(.rodata)
        "*/recon/tbs/unidentified.o"(.unidentified.0835305e)
        "*/games/COMMON/SRC/GRAPHICS/BACKDROP/VINASU_HEYA.o"(.rodata)
        "*/games/COMMON/SRC/GRAPHICS/BACKDROP/SUHARA_SABAKU.o"(.rodata)
        "*/games/COMMON/SRC/GRAPHICS/BACKDROP/ARUTAMIRA_DOU.o"(.rodata)
        "*/recon/tbs/unidentified.o"(.unidentified.0835eb02)
        "*/games/COMMON/SRC/GRAPHICS/BACKDROP/BABI_CHIKA.o"(.rodata)
        "*/games/COMMON/SRC/GRAPHICS/BACKDROP/BABI_IRIGUCHI.o"(.rodata)
        "*/games/COMMON/SRC/GRAPHICS/BACKDROP/RAMAKAN_SABAKU.o"(.rodata)
        "*/games/COMMON/SRC/GRAPHICS/BACKDROP/MOGORU_MORI.o"(.rodata)
        "*/recon/tbs/unidentified.o"(.unidentified.0836f1b2)
        "*/games/COMMON/SRC/GRAPHICS/BACKDROP/MAKYURI_CHOJO.o"(.rodata)
        "*/games/COMMON/SRC/GRAPHICS/BACKDROP/FUNE_HEYA.o"(.rodata)
        "*/recon/tbs/unidentified.o"(.unidentified.08376c52)
        "*/games/COMMON/SRC/GRAPHICS/BACKDROP/IMIRU_FUCHIN.o"(.rodata)
        "*/recon/tbs/unidentified.o"(.unidentified.0837a492)
        "*/games/COMMON/SRC/GRAPHICS/BACKDROP/KORIMA_MORI.o"(.rodata)
        "*/games/COMMON/SRC/GRAPHICS/BACKDROP/TORETO_HEYA.o"(.rodata)
        "*/recon/tbs/unidentified.o"(.unidentified.083838c6)
        "*/games/THE BROKEN SEAL/SRC/GRAPHICS/BACKDROP/GOMA_DOU.o"(.rodata)
        "*/games/COMMON/SRC/GRAPHICS/BACKDROP/INTERIOR.o"(.rodata)
        "*/games/COMMON/SRC/GRAPHICS/BACKDROP/ARUTIN_YAMA.o"(.rodata)
        "*/recon/tbs/unidentified.o"(.unidentified.0838ecee)
        "*/games/COMMON/SRC/GRAPHICS/BACKDROP/FUNE_KANPAN.o"(.rodata)
        "*/games/COMMON/SRC/GRAPHICS/BACKDROP/MAKYURI_HEYA.o"(.rodata)
        "*/recon/tbs/unidentified.o"(.unidentified.08396baa)
        "*/games/COMMON/SRC/GRAPHICS/BACKDROP/HAIDIA_ARASHI.o"(.rodata)
        "*/recon/tbs/unidentified.o"(.unidentified.0839b63a)
        "*/games/COMMON/SRC/GRAPHICS/BACKDROP/TORETO_EDA.o"(.rodata)
        "*/recon/tbs/unidentified.o"(.unidentified.0839f8ee)
        "*/games/COMMON/SRC/GRAPHICS/BACKDROP/BEACH.o"(.rodata)
        "*/recon/tbs/unidentified.o"(.unidentified.083a326e)
        "*/games/COMMON/SRC/GRAPHICS/BACKDROP/SNOWFIELD.o"(.rodata)
        "*/games/COMMON/SRC/GRAPHICS/BACKDROP/GRASSLAND.o"(.rodata)
        "*/games/COMMON/SRC/GRAPHICS/BACKDROP/SORU_SHINDEN.o"(.rodata)
        "*/recon/tbs/unidentified.o"(.unidentified.083afaaa)
        "*/games/COMMON/SRC/GRAPHICS/BACKDROP/FOREST.o"(.rodata)
        "*/games/COMMON/SRC/GRAPHICS/BACKDROP/VIOLET_SKY.o"(.rodata)
        "*/games/COMMON/SRC/GRAPHICS/BACKDROP/DESERT.o"(.rodata)
        "*/games/COMMON/SRC/GRAPHICS/BACKDROP/DUSK_CLOUDS.o"(.rodata)
        "*/recon/tbs/unidentified.o"(.unidentified.083be3f2)
        "*/games/COMMON/SRC/GRAPHICS/BACKDROP/AERIAL_VIEW.o"(.rodata)
        "*/games/COMMON/SRC/GRAPHICS/SLOTS/FRAME.o"(.rodata)
        "*/recon/tbs/unidentified.o"(.unidentified.083c3cf5)
        "*/games/COMMON/SRC/GRAPHICS/SLOTS/ICONS.o"(.rodata)
        "*/games/THE BROKEN SEAL/SRC/GRAPHICS/SLOTS/JACKPOT.o"(.rodata)
        "*/recon/tbs/unidentified.o"(.unidentified.083c5677)
        "*/games/COMMON/SRC/GRAPHICS/LUCKY_DICE/BOARD.o"(.rodata)
        "*/recon/tbs/unidentified.o"(.unidentified.083c8495)
        "*/games/COMMON/SRC/GRAPHICS/LUCKY_DICE/SPRITES.o"(.rodata)
        "*/recon/tbs/unidentified.o"(.unidentified.083cb4b9)
        "*/games/COMMON/SRC/GRAPHICS/BATTLE_FX/TILE_MASK.o"(.rodata)
        "*/recon/tbs/unidentified.o"(.unidentified.083cbd01)
        "*/games/THE BROKEN SEAL/SRC/GRAPHICS/BATTLE_FX/CYAN_SPARK.o"(.rodata)
        "*/games/COMMON/SRC/GRAPHICS/BATTLE_FX/VIOLET_PALETTE_A.o"(.rodata)
        "*/games/COMMON/SRC/GRAPHICS/BATTLE_FX/RED_PALETTE_A.o"(.rodata)
        "*/games/COMMON/SRC/GRAPHICS/BATTLE_FX/YELLOW_PALETTE_A.o"(.rodata)
        "*/games/THE BROKEN SEAL/SRC/GRAPHICS/BATTLE_FX/STAR_BURST.o"(.rodata)
        "*/recon/tbs/unidentified.o"(.unidentified.083cd517)
        "*/games/THE BROKEN SEAL/SRC/GRAPHICS/BATTLE_FX/CRESCENT.o"(.rodata)
        "*/recon/tbs/unidentified.o"(.unidentified.083cdb02)
        "*/games/THE BROKEN SEAL/SRC/GRAPHICS/BATTLE_FX/REVEAL_A.o"(.rodata)
        "*/recon/tbs/unidentified.o"(.unidentified.083ce1c6)
        "*/games/COMMON/SRC/GRAPHICS/BATTLE_FX/REVEAL_B.o"(.rodata)
        "*/recon/tbs/unidentified.o"(.unidentified.083ce4ad)
        "*/games/THE BROKEN SEAL/SRC/GRAPHICS/BATTLE_FX/REVEAL_C.o"(.rodata)
        "*/games/THE BROKEN SEAL/SRC/GRAPHICS/BATTLE_FX/REVEAL_D.o"(.rodata)
        "*/games/THE BROKEN SEAL/SRC/GRAPHICS/BATTLE_FX/REVEAL_E.o"(.rodata)
        "*/recon/tbs/unidentified.o"(.unidentified.083cf813)
        "*/games/THE BROKEN SEAL/SRC/GRAPHICS/BATTLE_FX/REVEAL_F.o"(.rodata)
        "*/recon/tbs/unidentified.o"(.unidentified.083cfbfd)
        "*/games/COMMON/SRC/GRAPHICS/BATTLE_FX/LIME_COLUMN.o"(.rodata)
        "*/recon/tbs/unidentified.o"(.unidentified.083cffcf)
        "*/games/THE BROKEN SEAL/SRC/GRAPHICS/BATTLE_FX/RAIN.o"(.rodata)
        "*/recon/tbs/unidentified.o"(.unidentified.083d086f)
        "*/games/THE BROKEN SEAL/SRC/GRAPHICS/BATTLE_FX/FLAME_A.o"(.rodata)
        "*/recon/tbs/unidentified.o"(.unidentified.083d0d12)
        "*/games/THE BROKEN SEAL/SRC/GRAPHICS/BATTLE_FX/DEMON.o"(.rodata)
        "*/games/THE BROKEN SEAL/SRC/GRAPHICS/BATTLE_FX/FLAME_BLD.o"(.rodata)
        "*/recon/tbs/unidentified.o"(.unidentified.083d1ecb)
        "*/games/COMMON/SRC/GRAPHICS/BATTLE_FX/SWORD.o"(.rodata)
        "*/games/THE BROKEN SEAL/SRC/GRAPHICS/BATTLE_FX/ICE_TILE.o"(.rodata)
        "*/recon/tbs/unidentified.o"(.unidentified.083d338e)
        "*/games/THE BROKEN SEAL/SRC/GRAPHICS/BATTLE_FX/FIVE_MODE.o"(.rodata)
        "*/recon/tbs/unidentified.o"(.unidentified.083d4357)
        "*/games/THE BROKEN SEAL/SRC/GRAPHICS/BATTLE_FX/WEB.o"(.rodata)
        "*/recon/tbs/unidentified.o"(.unidentified.083d45b2)
        "*/games/THE BROKEN SEAL/SRC/GRAPHICS/BATTLE_FX/BOLT_A.o"(.rodata)
        "*/games/COMMON/SRC/GRAPHICS/BATTLE_FX/YELLOW_SPARK.o"(.rodata)
        "*/recon/tbs/unidentified.o"(.unidentified.083d600d)
        "*/games/THE BROKEN SEAL/SRC/GRAPHICS/BATTLE_FX/PROJECTILE_VOLLEY.o"(.rodata)
        "*/games/THE BROKEN SEAL/SRC/GRAPHICS/BATTLE_FX/SHURIKEN.o"(.rodata)
        "*/recon/tbs/unidentified.o"(.unidentified.083d6559)
        "*/games/COMMON/SRC/GRAPHICS/BATTLE_FX/FLARE.o"(.rodata)
        "*/recon/tbs/unidentified.o"(.unidentified.083d82e2)
        "*/games/THE BROKEN SEAL/SRC/GRAPHICS/BATTLE_FX/FLARE_CELS.o"(.rodata)
        "*/recon/tbs/unidentified.o"(.unidentified.083d855b)
        "*/games/COMMON/SRC/GRAPHICS/BATTLE_FX/VIOLET_PALETTE_B.o"(.rodata)
        "*/games/COMMON/SRC/GRAPHICS/BATTLE_FX/FIRE_SWIRL.o"(.rodata)
        "*/recon/tbs/unidentified.o"(.unidentified.083d8a22)
        "*/games/THE BROKEN SEAL/SRC/GRAPHICS/BATTLE_FX/BOLT_B.o"(.rodata)
        "*/recon/tbs/unidentified.o"(.unidentified.083da5f7)
        "*/games/THE BROKEN SEAL/SRC/GRAPHICS/BATTLE_FX/FIRE_BURST.o"(.rodata)
        "*/recon/tbs/unidentified.o"(.unidentified.083dc1f5)
        "*/games/COMMON/SRC/GRAPHICS/BATTLE_FX/BLUE_CRESCENT.o"(.rodata)
        "*/recon/tbs/unidentified.o"(.unidentified.083dc416)
        "*/games/THE BROKEN SEAL/SRC/GRAPHICS/BATTLE_FX/OVERLAY_A.o"(.rodata)
        "*/recon/tbs/unidentified.o"(.unidentified.083dc853)
        "*/games/THE BROKEN SEAL/SRC/GRAPHICS/BATTLE_FX/MOTE.o"(.rodata)
        "*/recon/tbs/unidentified.o"(.unidentified.083dc965)
        "*/games/THE BROKEN SEAL/SRC/GRAPHICS/BATTLE_FX/OVERLAY_B.o"(.rodata)
        "*/games/THE BROKEN SEAL/SRC/GRAPHICS/BATTLE_FX/FIREBALL.o"(.rodata)
        "*/recon/tbs/unidentified.o"(.unidentified.083dd0e3)
        "*/games/THE BROKEN SEAL/SRC/GRAPHICS/BATTLE_FX/MEMBER_BURST.o"(.rodata)
        "*/recon/tbs/unidentified.o"(.unidentified.083dd581)
        "*/games/COMMON/SRC/GRAPHICS/BATTLE_FX/SLASH.o"(.rodata)
        "*/recon/tbs/unidentified.o"(.unidentified.083de296)
        "*/games/COMMON/SRC/GRAPHICS/BATTLE_FX/WAVE.o"(.rodata)
        "*/games/THE BROKEN SEAL/SRC/GRAPHICS/BATTLE_FX/TARGET_BURST.o"(.rodata)
        "*/recon/tbs/unidentified.o"(.unidentified.083df016)
        "*/games/COMMON/SRC/GRAPHICS/BATTLE_FX/PINK_STAR.o"(.rodata)
        "*/recon/tbs/unidentified.o"(.unidentified.083df3a7)
        "*/games/THE BROKEN SEAL/SRC/GRAPHICS/BATTLE_FX/WATER_SPRAY.o"(.rodata)
        "*/games/COMMON/SRC/GRAPHICS/BATTLE_FX/BLUE_FLAME.o"(.rodata)
        "*/recon/tbs/unidentified.o"(.unidentified.083e10ee)
        "*/games/COMMON/SRC/GRAPHICS/BATTLE_FX/EXPLOSION.o"(.rodata)
        "*/recon/tbs/unidentified.o"(.unidentified.083e1ec5)
        "*/games/COMMON/SRC/GRAPHICS/BATTLE_FX/MAGENTA_SWIRL.o"(.rodata)
        "*/recon/tbs/unidentified.o"(.unidentified.083e26f2)
        "*/games/COMMON/SRC/GRAPHICS/BATTLE_FX/MAGENTA_TAIL.o"(.rodata)
        "*/games/THE BROKEN SEAL/SRC/GRAPHICS/BATTLE_FX/DOT_CELLS_A.o"(.rodata)
        "*/recon/tbs/unidentified.o"(.unidentified.083e2d7d)
        "*/games/THE BROKEN SEAL/SRC/GRAPHICS/BATTLE_FX/DOT_CELLS_B.o"(.rodata)
        "*/recon/tbs/unidentified.o"(.unidentified.083e2f3b)
        "*/games/THE BROKEN SEAL/SRC/GRAPHICS/BATTLE_FX/DOT_CELLS_C.o"(.rodata)
        "*/games/THE BROKEN SEAL/SRC/GRAPHICS/BATTLE_FX/DOT_CELLS_D.o"(.rodata)
        "*/recon/tbs/unidentified.o"(.unidentified.083e3c93)
        "*/games/COMMON/SRC/GRAPHICS/BATTLE_FX/GREEN_PALETTE.o"(.rodata)
        "*/games/THE BROKEN SEAL/SRC/GRAPHICS/BATTLE_FX/SWORD_SLASH.o"(.rodata)
        "*/recon/tbs/unidentified.o"(.unidentified.083e41df)
        "*/games/COMMON/SRC/GRAPHICS/BATTLE_FX/RUNE.o"(.rodata)
        "*/recon/tbs/unidentified.o"(.unidentified.083e45b9)
        "*/games/COMMON/SRC/GRAPHICS/BATTLE_FX/FLAME_COLUMN.o"(.rodata)
        "*/recon/tbs/unidentified.o"(.unidentified.083e4967)
        "*/games/COMMON/SRC/GRAPHICS/BATTLE_FX/EARTH_WALL.o"(.rodata)
        "*/games/COMMON/SRC/GRAPHICS/BATTLE_FX/ORANGE_PALETTE_A.o"(.rodata)
        "*/games/COMMON/SRC/GRAPHICS/BATTLE_FX/FLASH_BURST.o"(.rodata)
        "*/recon/tbs/unidentified.o"(.unidentified.083e690b)
        "*/games/COMMON/SRC/GRAPHICS/BATTLE_FX/THORN.o"(.rodata)
        "*/recon/tbs/unidentified.o"(.unidentified.083e76a7)
        "*/games/COMMON/SRC/GRAPHICS/BATTLE_FX/COMET_A.o"(.rodata)
        "*/recon/tbs/unidentified.o"(.unidentified.083e78c3)
        "*/games/COMMON/SRC/GRAPHICS/BATTLE_FX/COMET_B.o"(.rodata)
        "*/recon/tbs/unidentified.o"(.unidentified.083e7bbf)
        "*/games/COMMON/SRC/GRAPHICS/BATTLE_FX/COMET_C.o"(.rodata)
        "*/games/THE BROKEN SEAL/SRC/GRAPHICS/BATTLE_FX/WHIRLWIND.o"(.rodata)
        "*/games/COMMON/SRC/GRAPHICS/BATTLE_FX/GREEN_PILLAR.o"(.rodata)
        "*/recon/tbs/unidentified.o"(.unidentified.083e9d6d)
        "*/games/COMMON/SRC/GRAPHICS/BATTLE_FX/VINE.o"(.rodata)
        "*/recon/tbs/unidentified.o"(.unidentified.083eab3b)
        "*/games/THE BROKEN SEAL/SRC/GRAPHICS/BATTLE_FX/FIRE_PILLAR_A.o"(.rodata)
        "*/games/COMMON/SRC/GRAPHICS/BATTLE_FX/RED_PALETTE_B.o"(.rodata)
        "*/games/COMMON/SRC/GRAPHICS/BATTLE_FX/ORANGE_PALETTE_B.o"(.rodata)
        "*/games/COMMON/SRC/GRAPHICS/BATTLE_FX/VIOLET_COMET.o"(.rodata)
        "*/recon/tbs/unidentified.o"(.unidentified.083ebc9d)
        "*/games/COMMON/SRC/GRAPHICS/BATTLE_FX/FLAMEBALL.o"(.rodata)
        "*/recon/tbs/unidentified.o"(.unidentified.083ec1f7)
        "*/games/COMMON/SRC/GRAPHICS/BATTLE_FX/BOULDER.o"(.rodata)
        "*/games/COMMON/SRC/GRAPHICS/BATTLE_FX/ROCK_WALL.o"(.rodata)
        "*/recon/tbs/unidentified.o"(.unidentified.083edae1)
        "*/games/THE BROKEN SEAL/SRC/GRAPHICS/BATTLE_FX/STAR_DOT.o"(.rodata)
        "*/recon/tbs/unidentified.o"(.unidentified.083ee382)
        "*/games/COMMON/SRC/GRAPHICS/BATTLE_FX/MARS_DJINN.o"(.rodata)
        "*/recon/tbs/unidentified.o"(.unidentified.083ee75f)
        "*/games/COMMON/SRC/GRAPHICS/BATTLE_FX/MARS_DJINN_SMALL.o"(.rodata)
        "*/recon/tbs/unidentified.o"(.unidentified.083ee9e9)
        "*/games/COMMON/SRC/GRAPHICS/BATTLE_FX/JUPITER_DJINN.o"(.rodata)
        "*/recon/tbs/unidentified.o"(.unidentified.083eed8f)
        "*/games/COMMON/SRC/GRAPHICS/BATTLE_FX/JUPITER_DJINN_SMALL.o"(.rodata)
        "*/recon/tbs/unidentified.o"(.unidentified.083eefea)
        "*/games/COMMON/SRC/GRAPHICS/BATTLE_FX/MERCURY_DJINN.o"(.rodata)
        "*/recon/tbs/unidentified.o"(.unidentified.083ef3a2)
        "*/games/COMMON/SRC/GRAPHICS/BATTLE_FX/MERCURY_DJINN_SMALL.o"(.rodata)
        "*/games/COMMON/SRC/GRAPHICS/BATTLE_FX/VENUS_DJINN.o"(.rodata)
        "*/games/COMMON/SRC/GRAPHICS/BATTLE_FX/VENUS_DJINN_SMALL.o"(.rodata)
        "*/games/COMMON/SRC/GRAPHICS/BATTLE_FX/FIRE_BLOB.o"(.rodata)
        "*/recon/tbs/unidentified.o"(.unidentified.083f088b)
        "*/games/COMMON/SRC/GRAPHICS/BATTLE_FX/FIRE_STREAK.o"(.rodata)
        "*/recon/tbs/unidentified.o"(.unidentified.083f1e4e)
        "*/games/COMMON/SRC/GRAPHICS/BATTLE_FX/YELLOW_RING.o"(.rodata)
        "*/games/COMMON/SRC/GRAPHICS/BATTLE_FX/YELLOW_ORB.o"(.rodata)
        "*/recon/tbs/unidentified.o"(.unidentified.083f3692)
        "*/games/COMMON/SRC/GRAPHICS/BATTLE_FX/BUBBLE.o"(.rodata)
        "*/recon/tbs/unidentified.o"(.unidentified.083f3a15)
        "*/games/COMMON/SRC/GRAPHICS/BATTLE_FX/SHIELD.o"(.rodata)
        "*/recon/tbs/unidentified.o"(.unidentified.083f46c5)
        "*/games/COMMON/SRC/GRAPHICS/BATTLE_FX/DAGGER.o"(.rodata)
        "*/recon/tbs/unidentified.o"(.unidentified.083f520d)
        "*/games/THE BROKEN SEAL/SRC/GRAPHICS/BATTLE_FX/SPARK_CELLS.o"(.rodata)
        "*/recon/tbs/unidentified.o"(.unidentified.083f53a6)
        "*/games/THE BROKEN SEAL/SRC/GRAPHICS/BATTLE_FX/SMOKE.o"(.rodata)
        "*/recon/tbs/unidentified.o"(.unidentified.083f5c33)
        "*/games/COMMON/SRC/GRAPHICS/BATTLE_FX/BLUE_PALETTE.o"(.rodata)
        "*/games/COMMON/SRC/GRAPHICS/BATTLE_FX/LIME_PALETTE.o"(.rodata)
        "*/games/COMMON/SRC/GRAPHICS/BATTLE_FX/PINK_PALETTE.o"(.rodata)
        "*/games/COMMON/SRC/GRAPHICS/BATTLE_FX/VIOLET_PALETTE_C.o"(.rodata)
        "*/games/COMMON/SRC/GRAPHICS/BATTLE_FX/CYAN_PALETTE.o"(.rodata)
        "*/games/COMMON/SRC/GRAPHICS/BATTLE_FX/TAN_PALETTE.o"(.rodata)
        "*/games/COMMON/SRC/GRAPHICS/BATTLE_FX/WISP.o"(.rodata)
        "*/recon/tbs/unidentified.o"(.unidentified.083f66fa)
        "*/games/COMMON/SRC/GRAPHICS/BATTLE_FX/GREEN_VINE.o"(.rodata)
        "*/recon/tbs/unidentified.o"(.unidentified.083f6c12)
        "*/games/THE BROKEN SEAL/SRC/GRAPHICS/BATTLE_FX/PORTAL.o"(.rodata)
        "*/recon/tbs/unidentified.o"(.unidentified.083f7236)
        "*/games/THE BROKEN SEAL/SRC/GRAPHICS/BATTLE_FX/SHEEP.o"(.rodata)
        "*/recon/tbs/unidentified.o"(.unidentified.083f7a9d)
        "*/games/COMMON/SRC/GRAPHICS/BATTLE_FX/SKULL.o"(.rodata)
        "*/recon/tbs/unidentified.o"(.unidentified.083f7ec1)
        "*/games/COMMON/SRC/GRAPHICS/BATTLE_FX/HEART.o"(.rodata)
        "*/recon/tbs/unidentified.o"(.unidentified.083f815b)
        "*/games/COMMON/SRC/GRAPHICS/BATTLE_FX/COUNTER_REVEAL.o"(.rodata)
        "*/games/THE BROKEN SEAL/SRC/GRAPHICS/BATTLE_FX/RED_CRESCENT_A.o"(.rodata)
        "*/recon/tbs/unidentified.o"(.unidentified.083f9af7)
        "*/games/THE BROKEN SEAL/SRC/GRAPHICS/BATTLE_FX/BLUE_BEAST.o"(.rodata)
        "*/games/COMMON/SRC/GRAPHICS/BATTLE_FX/RED_CRESCENT_B.o"(.rodata)
        "*/recon/tbs/unidentified.o"(.unidentified.083fb86e)
        "*/games/COMMON/SRC/GRAPHICS/BATTLE_FX/SPIRAL.o"(.rodata)
        "*/games/COMMON/SRC/GRAPHICS/BATTLE_FX/VIOLET_STREAK.o"(.rodata)
        "*/recon/tbs/unidentified.o"(.unidentified.083fd7e3)
        "*/games/COMMON/SRC/GRAPHICS/BATTLE_FX/CRESCENT_MOON.o"(.rodata)
        "*/recon/tbs/unidentified.o"(.unidentified.083fdcb3)
        "*/games/THE BROKEN SEAL/SRC/GRAPHICS/BATTLE_FX/THORN_VINE.o"(.rodata)
        "*/recon/tbs/unidentified.o"(.unidentified.083fe345)
        "*/games/THE BROKEN SEAL/SRC/GRAPHICS/BATTLE_FX/EMBER_STREAK.o"(.rodata)
        "*/games/COMMON/SRC/GRAPHICS/BATTLE_FX/BLUE_ARC_A.o"(.rodata)
        "*/recon/tbs/unidentified.o"(.unidentified.0840014d)
        "*/games/COMMON/SRC/GRAPHICS/BATTLE_FX/BLUE_ARC_B.o"(.rodata)
        "*/recon/tbs/unidentified.o"(.unidentified.08400c1e)
        "*/games/COMMON/SRC/GRAPHICS/BATTLE_FX/GLOW_ORB.o"(.rodata)
        "*/recon/tbs/unidentified.o"(.unidentified.0840175b)
        "*/games/THE BROKEN SEAL/SRC/GRAPHICS/BATTLE_FX/ICE_CHIP.o"(.rodata)
        "*/recon/tbs/unidentified.o"(.unidentified.08401d9b)
        "*/games/THE BROKEN SEAL/SRC/GRAPHICS/BATTLE_FX/SPARKLE_DOTS.o"(.rodata)
        "*/recon/tbs/unidentified.o"(.unidentified.08403385)
        "*/games/COMMON/SRC/GRAPHICS/BATTLE_FX/PINK_BURST.o"(.rodata)
        "*/recon/tbs/unidentified.o"(.unidentified.084036f3)
        "*/games/COMMON/SRC/GRAPHICS/BATTLE_FX/LIGHT_FAN.o"(.rodata)
        "*/recon/tbs/unidentified.o"(.unidentified.08403c91)
        "*/games/THE BROKEN SEAL/SRC/GRAPHICS/BATTLE_FX/BLUE_BURST.o"(.rodata)
        "*/recon/tbs/unidentified.o"(.unidentified.08403fc5)
        "*/games/COMMON/SRC/GRAPHICS/BATTLE_FX/DUST_PUFF.o"(.rodata)
        "*/recon/tbs/unidentified.o"(.unidentified.08404301)
        "*/games/THE BROKEN SEAL/SRC/GRAPHICS/BATTLE_FX/GOLD_SHELL.o"(.rodata)
        "*/recon/tbs/unidentified.o"(.unidentified.0840531a)
        "*/games/THE BROKEN SEAL/SRC/GRAPHICS/BATTLE_FX/BLAST.o"(.rodata)
        "*/games/COMMON/SRC/GRAPHICS/BATTLE_FX/FLAME_B.o"(.rodata)
        "*/games/THE BROKEN SEAL/SRC/GRAPHICS/BATTLE_FX/FIRE_PILLAR_B.o"(.rodata)
        "*/recon/tbs/unidentified.o"(.unidentified.08408926)
        "*/games/COMMON/SRC/GRAPHICS/BATTLE_FX/ROCK_SPIRE.o"(.rodata)
        "*/recon/tbs/unidentified.o"(.unidentified.084090c9)
        "*/games/COMMON/SRC/GRAPHICS/BATTLE_FX/LIGHTNING_BOLT.o"(.rodata)
        "*/games/THE BROKEN SEAL/SRC/GRAPHICS/BATTLE_FX/BEAM_SEQUENCE.o"(.rodata)
        "*/recon/tbs/unidentified.o"(.unidentified.0840a45b)
        "*/games/THE BROKEN SEAL/SRC/GRAPHICS/BATTLE_FX/TWELVE_MODE.o"(.rodata)
        "*/recon/tbs/unidentified.o"(.unidentified.0840a88b)
        "*/games/THE BROKEN SEAL/SRC/GRAPHICS/BATTLE_FX/WIND_STREAK.o"(.rodata)
        "*/games/COMMON/SRC/GRAPHICS/BATTLE_FX/YELLOW_PALETTE_B.o"(.rodata)
        "*/games/THE BROKEN SEAL/SRC/GRAPHICS/BATTLE_FX/BLUE_RING.o"(.rodata)
        "*/games/COMMON/SRC/GRAPHICS/BATTLE_FX/RED_PALETTE_C.o"(.rodata)
        "*/games/COMMON/SRC/GRAPHICS/BATTLE_FX/VIOLET_PALETTE_D.o"(.rodata)
        "*/games/THE BROKEN SEAL/SRC/GRAPHICS/BATTLE_FX/BLUE_BEAM.o"(.rodata)
        "*/recon/tbs/unidentified.o"(.unidentified.0840c681)
        "*/games/THE BROKEN SEAL/SRC/GRAPHICS/BATTLE_FX/VORTEX.o"(.rodata)
        "*/recon/tbs/unidentified.o"(.unidentified.0840cf96)
        "*/games/THE BROKEN SEAL/SRC/GRAPHICS/BATTLE_FX/TORNADO.o"(.rodata)
        "*/recon/tbs/unidentified.o"(.unidentified.0840eaca)
        "*/games/THE BROKEN SEAL/SRC/GRAPHICS/BATTLE_FX/CRYSTAL.o"(.rodata)
        "*/recon/tbs/unidentified.o"(.unidentified.0840fb19)
        "*/games/THE BROKEN SEAL/SRC/GRAPHICS/BATTLE_FX/WATER_SPARKLE.o"(.rodata)
        "*/recon/tbs/unidentified.o"(.unidentified.084101cf)
        "*/games/COMMON/SRC/GRAPHICS/BATTLE_FX/LIGHTNING_PILLAR.o"(.rodata)
        "*/recon/tbs/unidentified.o"(.unidentified.08411275)
        "*/games/COMMON/SRC/GRAPHICS/BATTLE_FX/STAGED_PARTICLE_PATH.o"(.rodata)
        "*/games/COMMON/SRC/GRAPHICS/BATTLE_FX/DUAL_STREAM_PATH.o"(.rodata)
        "*/games/THE BROKEN SEAL/SRC/MAP/WORLD/BLOCKS.o"(.rodata)
        "*/games/THE BROKEN SEAL/SRC/MAP/DEFAULT/CELLS.o"(.rodata)
        "*/recon/tbs/unidentified.o"(.unidentified.08424687)
        "*/games/THE BROKEN SEAL/SRC/MAP/DEFAULT/ANIMATION.o"(.rodata)
        "*/recon/tbs/unidentified.o"(.unidentified.084247d9)
        "*/games/THE BROKEN SEAL/SRC/MAP/DEFAULT/ATTRIBUTES.o"(.rodata)
        "*/recon/tbs/unidentified.o"(.unidentified.08424c6a)
        "*/games/THE BROKEN SEAL/SRC/GRAPHICS/WORLD_MAP/PALETTE_A.o"(.rodata)
        "*/recon/tbs/unidentified.o"(.unidentified.08424e61)
        "*/games/THE BROKEN SEAL/SRC/GRAPHICS/WORLD_MAP/TILES_A.o"(.rodata)
        "*/recon/tbs/unidentified.o"(.unidentified.0842651e)
        "*/games/THE BROKEN SEAL/SRC/GRAPHICS/WORLD_MAP/TILES_B.o"(.rodata)
        "*/recon/tbs/unidentified.o"(.unidentified.08427a3d)
        "*/games/THE BROKEN SEAL/SRC/GRAPHICS/WORLD_MAP/TILES_C.o"(.rodata)
        "*/recon/tbs/unidentified.o"(.unidentified.08428609)
        "*/games/THE BROKEN SEAL/SRC/GRAPHICS/WORLD_MAP/TILES_D.o"(.rodata)
        "*/recon/tbs/unidentified.o"(.unidentified.0842917e)
        "*/games/THE BROKEN SEAL/SRC/GRAPHICS/WORLD_MAP/TILES_E.o"(.rodata)
        "*/recon/tbs/unidentified.o"(.unidentified.0842b027)
        "*/games/THE BROKEN SEAL/SRC/GRAPHICS/WORLD_MAP/PALETTE_B.o"(.rodata)
        "*/games/THE BROKEN SEAL/SRC/GRAPHICS/WORLD_MAP/TILES_F.o"(.rodata)
        "*/recon/tbs/unidentified.o"(.unidentified.0842c7b5)
        "*/games/THE BROKEN SEAL/SRC/GRAPHICS/WORLD_MAP/TILES_G.o"(.rodata)
        "*/recon/tbs/unidentified.o"(.unidentified.0842dc66)
        "*/games/THE BROKEN SEAL/SRC/GRAPHICS/WORLD_MAP/TILES_H.o"(.rodata)
        "*/games/THE BROKEN SEAL/SRC/GRAPHICS/WORLD_MAP/TILES_I.o"(.rodata)
        "*/games/THE BROKEN SEAL/SRC/GRAPHICS/WORLD_MAP/TILES_J.o"(.rodata)
        "*/recon/tbs/unidentified.o"(.unidentified.084303b3)
        "*/games/THE BROKEN SEAL/SRC/MAP/KOROSSEO/RIVAL_PATH_A.o"(.rodata)
        "*/recon/tbs/unidentified.o"(.unidentified.08431c4d)
        "*/games/THE BROKEN SEAL/SRC/MAP/KOROSSEO/RIVAL_PATH_B.o"(.rodata)
        "*/recon/tbs/unidentified.o"(.unidentified.08433216)
        "*/games/THE BROKEN SEAL/SRC/MAP/KOROSSEO/RIVAL_PATH_C.o"(.rodata)
        "*/recon/tbs/unidentified.o"(.unidentified.08434ca6)
        "*/games/THE BROKEN SEAL/SRC/GRAPHICS/KOROSSEO/LETTERING.o"(.rodata)
        "*/recon/tbs/unidentified.o"(.unidentified.08435ef7)
        "*/games/COMMON/SRC/GRAPHICS/SHOP/CURSOR.o"(.rodata)
        "*/games/THE BROKEN SEAL/SRC/GRAPHICS/UI/ICONS.o"(.rodata)
        "*/games/THE BROKEN SEAL/SRC/GRAPHICS/UI/COMMAND_ICONS.o"(.rodata)
        "*/recon/tbs/unidentified.o"(.unidentified.0843f866)
        "*/games/COMMON/SRC/GRAPHICS/MONSTER/AXE_GOBLIN.o"(.rodata)
        "*/recon/tbs/unidentified.o"(.unidentified.08441a1a)
        "*/games/COMMON/SRC/GRAPHICS/MONSTER/GHOUL.o"(.rodata)
        "*/games/COMMON/SRC/GRAPHICS/MONSTER/HARPY.o"(.rodata)
        "*/recon/tbs/unidentified.o"(.unidentified.08445b81)
        "*/games/COMMON/SRC/GRAPHICS/MONSTER/TROLL.o"(.rodata)
        "*/recon/tbs/unidentified.o"(.unidentified.08448da6)
        "*/games/COMMON/SRC/GRAPHICS/MONSTER/WITCH.o"(.rodata)
        "*/recon/tbs/unidentified.o"(.unidentified.0844a4aa)
        "*/games/COMMON/SRC/GRAPHICS/MONSTER/GRIFFIN.o"(.rodata)
        "*/games/COMMON/SRC/GRAPHICS/MONSTER/SHIELD_KNIGHT.o"(.rodata)
        "*/games/COMMON/SRC/GRAPHICS/MONSTER/ORC.o"(.rodata)
        "*/recon/tbs/unidentified.o"(.unidentified.08451092)
        "*/games/COMMON/SRC/GRAPHICS/MONSTER/CHIMERA.o"(.rodata)
        "*/games/THE BROKEN SEAL/SRC/GRAPHICS/MONSTER/LIVING_ARMOR.o"(.rodata)
        "*/recon/tbs/unidentified.o"(.unidentified.08459a16)
        "*/games/COMMON/SRC/GRAPHICS/MONSTER/MANTICORE.o"(.rodata)
        "*/games/COMMON/SRC/GRAPHICS/MONSTER/ORC_LORD.o"(.rodata)
        "*/recon/tbs/unidentified.o"(.unidentified.084614f2)
        "*/games/COMMON/SRC/GRAPHICS/MONSTER/GARGOYLE.o"(.rodata)
        "*/recon/tbs/unidentified.o"(.unidentified.08464586)
        "*/games/COMMON/SRC/GRAPHICS/MONSTER/LIZARD_MAN.o"(.rodata)
        "*/recon/tbs/unidentified.o"(.unidentified.08467995)
        "*/games/COMMON/SRC/GRAPHICS/MONSTER/OGRE.o"(.rodata)
        "*/recon/tbs/unidentified.o"(.unidentified.0846a201)
        "*/games/COMMON/SRC/GRAPHICS/MONSTER/TAILED_IMP.o"(.rodata)
        "*/games/COMMON/SRC/GRAPHICS/MONSTER/WISP_GHOST.o"(.rodata)
        "*/recon/tbs/unidentified.o"(.unidentified.0846bcf2)
        "*/games/COMMON/SRC/GRAPHICS/MONSTER/SALAMANDER.o"(.rodata)
        "*/recon/tbs/unidentified.o"(.unidentified.0846cb0a)
        "*/games/COMMON/SRC/GRAPHICS/MONSTER/AQUA_BEAST.o"(.rodata)
        "*/recon/tbs/unidentified.o"(.unidentified.0846d7f5)
        "*/games/COMMON/SRC/GRAPHICS/MONSTER/HOUND.o"(.rodata)
        "*/games/COMMON/SRC/GRAPHICS/MONSTER/BEAR.o"(.rodata)
        "*/games/COMMON/SRC/GRAPHICS/MONSTER/SIREN.o"(.rodata)
        "*/games/COMMON/SRC/GRAPHICS/MONSTER/BLUE_WISP.o"(.rodata)
        "*/recon/tbs/unidentified.o"(.unidentified.08476cb2)
        "*/games/COMMON/SRC/GRAPHICS/MONSTER/MUSHROOM.o"(.rodata)
        "*/recon/tbs/unidentified.o"(.unidentified.084779bd)
        "*/games/COMMON/SRC/GRAPHICS/MONSTER/RED_WORM.o"(.rodata)
        "*/games/THE BROKEN SEAL/SRC/GRAPHICS/MONSTER/FAIRY.o"(.rodata)
        "*/games/COMMON/SRC/GRAPHICS/MONSTER/BAT.o"(.rodata)
        "*/recon/tbs/unidentified.o"(.unidentified.08479ad1)
        "*/games/COMMON/SRC/GRAPHICS/MONSTER/SMALL_LIZARD.o"(.rodata)
        "*/recon/tbs/unidentified.o"(.unidentified.0847a743)
        "*/games/COMMON/SRC/GRAPHICS/MONSTER/WALKING_PLANT.o"(.rodata)
        "*/recon/tbs/unidentified.o"(.unidentified.0847b35b)
        "*/games/COMMON/SRC/GRAPHICS/MONSTER/FLY.o"(.rodata)
        "*/recon/tbs/unidentified.o"(.unidentified.0847bacf)
        "*/games/COMMON/SRC/GRAPHICS/MONSTER/CRAB.o"(.rodata)
        "*/games/COMMON/SRC/GRAPHICS/MONSTER/SMALL_BIRD.o"(.rodata)
        "*/recon/tbs/unidentified.o"(.unidentified.0847d35f)
        "*/games/COMMON/SRC/GRAPHICS/MONSTER/MOTH.o"(.rodata)
        "*/recon/tbs/unidentified.o"(.unidentified.0847dd2d)
        "*/games/COMMON/SRC/GRAPHICS/MONSTER/FROG.o"(.rodata)
        "*/recon/tbs/unidentified.o"(.unidentified.0847e94b)
        "*/games/COMMON/SRC/GRAPHICS/MONSTER/MANED_LION.o"(.rodata)
        "*/recon/tbs/unidentified.o"(.unidentified.08480fff)
        "*/games/COMMON/SRC/GRAPHICS/MONSTER/SERPENT.o"(.rodata)
        "*/recon/tbs/unidentified.o"(.unidentified.08483712)
        "*/games/COMMON/SRC/GRAPHICS/MONSTER/WINGED_DRAGON.o"(.rodata)
        "*/recon/tbs/unidentified.o"(.unidentified.08488667)
        "*/games/COMMON/SRC/GRAPHICS/MONSTER/BLUE_MAGE.o"(.rodata)
        "*/games/COMMON/SRC/GRAPHICS/MONSTER/SKELETON.o"(.rodata)
        "*/recon/tbs/unidentified.o"(.unidentified.0848c991)
        "*/games/COMMON/SRC/GRAPHICS/MONSTER/FLAME_SKULL.o"(.rodata)
        "*/recon/tbs/unidentified.o"(.unidentified.0848d57e)
        "*/games/COMMON/SRC/GRAPHICS/MONSTER/FIRE_DRAGON.o"(.rodata)
        "*/recon/tbs/unidentified.o"(.unidentified.08492133)
        "*/games/COMMON/SRC/GRAPHICS/MONSTER/CRAWLER.o"(.rodata)
        "*/recon/tbs/unidentified.o"(.unidentified.0849449d)
        "*/games/COMMON/SRC/GRAPHICS/MONSTER/MIMIC.o"(.rodata)
        "*/recon/tbs/unidentified.o"(.unidentified.08495e3f)
        "*/games/COMMON/SRC/GRAPHICS/MONSTER/SEA_BEAST.o"(.rodata)
        "*/games/COMMON/SRC/GRAPHICS/MONSTER/SPIRIT_HORSE.o"(.rodata)
        "*/recon/tbs/unidentified.o"(.unidentified.0849a701)
        "*/games/COMMON/SRC/GRAPHICS/MONSTER/KRAKEN.o"(.rodata)
        "*/recon/tbs/unidentified.o"(.unidentified.0849e7c9)
        "*/games/COMMON/SRC/GRAPHICS/MONSTER/SLIME.o"(.rodata)
        "*/recon/tbs/unidentified.o"(.unidentified.084a1e92)
        "*/games/COMMON/SRC/GRAPHICS/MONSTER/SATUROS.o"(.rodata)
        "*/games/COMMON/SRC/GRAPHICS/MONSTER/MENARDI.o"(.rodata)
        "*/recon/tbs/unidentified.o"(.unidentified.084a9e63)
        "*/games/COMMON/SRC/GRAPHICS/MONSTER/GHOST_HEAD.o"(.rodata)
        "*/games/COMMON/SRC/GRAPHICS/MONSTER/FUSION_DRAGON.o"(.rodata)
        "*/recon/tbs/unidentified.o"(.unidentified.084b1173)
        "*/games/COMMON/SRC/GRAPHICS/MONSTER/PURPLE_BEAST.o"(.rodata)
        "*/recon/tbs/unidentified.o"(.unidentified.084b60f3)
        "*/games/COMMON/SRC/GRAPHICS/MONSTER/RED_WARRIOR.o"(.rodata)
        "*/games/COMMON/SRC/GRAPHICS/MONSTER/SWORD_GIRL.o"(.rodata)
        "*/games/THE BROKEN SEAL/SRC/MAP/MAP_001/MAP.o"(.rodata)
        "*/recon/tbs/unidentified.o"(.unidentified.084baaa3)
        "*/recon/tbs/unidentified.o"(.unidentified.084baaa4)
        "*/games/THE BROKEN SEAL/SRC/MAP/MAP_000/MAP.o"(.rodata)
        "*/recon/tbs/unidentified.o"(.unidentified.084c03cf)
        "*/games/THE BROKEN SEAL/SRC/GRAPHICS/TILESET/SET_00/PALETTE.o"(.rodata)
        "*/recon/tbs/unidentified.o"(.unidentified.084c055d)
        "*/games/THE BROKEN SEAL/SRC/GRAPHICS/TILESET/SET_00/TILES_A.o"(.rodata)
        "*/games/THE BROKEN SEAL/SRC/GRAPHICS/TILESET/SET_00/TILES_B.o"(.rodata)
        "*/recon/tbs/unidentified.o"(.unidentified.084c55bd)
        "*/games/THE BROKEN SEAL/SRC/GRAPHICS/TILESET/SET_00/TILES_C.o"(.rodata)
        "*/games/THE BROKEN SEAL/SRC/GRAPHICS/TILESET/SET_00/TILES_D.o"(.rodata)
        "*/recon/tbs/unidentified.o"(.unidentified.084c9b29)
        "*/games/THE BROKEN SEAL/SRC/MAP/MAP_002/MAP.o"(.rodata)
        "*/recon/tbs/unidentified.o"(.unidentified.084cecf1)
        "*/games/THE BROKEN SEAL/SRC/GRAPHICS/TILESET/SET_01/PALETTE.o"(.rodata)
        "*/recon/tbs/unidentified.o"(.unidentified.084cee87)
        "*/games/THE BROKEN SEAL/SRC/GRAPHICS/TILESET/SET_01/TILES_A.o"(.rodata)
        "*/recon/tbs/unidentified.o"(.unidentified.084d1adb)
        "*/games/THE BROKEN SEAL/SRC/GRAPHICS/TILESET/SET_01/TILES_B.o"(.rodata)
        "*/games/THE BROKEN SEAL/SRC/GRAPHICS/TILESET/SET_01/TILES_C.o"(.rodata)
        "*/games/THE BROKEN SEAL/SRC/GRAPHICS/TILESET/SET_01/TILES_D.o"(.rodata)
        "*/recon/tbs/unidentified.o"(.unidentified.084d878f)
        "*/games/THE BROKEN SEAL/SRC/MAP/MAP_003/MAP.o"(.rodata)
        "*/recon/tbs/unidentified.o"(.unidentified.084db8ca)
        "*/games/THE BROKEN SEAL/SRC/GRAPHICS/TILESET/SET_02/PALETTE.o"(.rodata)
        "*/recon/tbs/unidentified.o"(.unidentified.084dba4b)
        "*/games/THE BROKEN SEAL/SRC/GRAPHICS/TILESET/SET_02/TILES_A.o"(.rodata)
        "*/recon/tbs/unidentified.o"(.unidentified.084de205)
        "*/games/THE BROKEN SEAL/SRC/GRAPHICS/TILESET/SET_02/TILES_B.o"(.rodata)
        "*/recon/tbs/unidentified.o"(.unidentified.084e084e)
        "*/games/THE BROKEN SEAL/SRC/GRAPHICS/TILESET/SET_02/TILES_C.o"(.rodata)
        "*/recon/tbs/unidentified.o"(.unidentified.084e2f32)
        "*/games/THE BROKEN SEAL/SRC/GRAPHICS/TILESET/SET_02/TILES_D.o"(.rodata)
        "*/recon/tbs/unidentified.o"(.unidentified.084e3fa7)
        "*/games/THE BROKEN SEAL/SRC/MAP/MAP_004/MAP.o"(.rodata)
        "*/recon/tbs/unidentified.o"(.unidentified.084e60fa)
        "*/games/THE BROKEN SEAL/SRC/GRAPHICS/TILESET/SET_03/PALETTE.o"(.rodata)
        "*/recon/tbs/unidentified.o"(.unidentified.084e628d)
        "*/games/THE BROKEN SEAL/SRC/GRAPHICS/TILESET/SET_03/TILES_A.o"(.rodata)
        "*/recon/tbs/unidentified.o"(.unidentified.084e8acf)
        "*/games/THE BROKEN SEAL/SRC/GRAPHICS/TILESET/SET_03/TILES_B.o"(.rodata)
        "*/recon/tbs/unidentified.o"(.unidentified.084ea8e5)
        "*/games/THE BROKEN SEAL/SRC/GRAPHICS/TILESET/SET_03/TILES_C.o"(.rodata)
        "*/recon/tbs/unidentified.o"(.unidentified.084ecfc6)
        "*/games/THE BROKEN SEAL/SRC/GRAPHICS/TILESET/SET_03/TILES_D.o"(.rodata)
        "*/recon/tbs/unidentified.o"(.unidentified.084ee10d)
        "*/games/THE BROKEN SEAL/SRC/MAP/MAP_005/MAP.o"(.rodata)
        "*/recon/tbs/unidentified.o"(.unidentified.084f1221)
        "*/games/THE BROKEN SEAL/SRC/GRAPHICS/TILESET/SET_04/PALETTE.o"(.rodata)
        "*/games/THE BROKEN SEAL/SRC/GRAPHICS/TILESET/SET_04/TILES_A.o"(.rodata)
        "*/games/THE BROKEN SEAL/SRC/GRAPHICS/TILESET/SET_04/TILES_B.o"(.rodata)
        "*/recon/tbs/unidentified.o"(.unidentified.084f5389)
        "*/games/THE BROKEN SEAL/SRC/GRAPHICS/TILESET/SET_04/TILES_C.o"(.rodata)
        "*/recon/tbs/unidentified.o"(.unidentified.084f6986)
        "*/games/THE BROKEN SEAL/SRC/GRAPHICS/TILESET/SET_04/TILES_D.o"(.rodata)
        "*/recon/tbs/unidentified.o"(.unidentified.084f7c4f)
        "*/games/THE BROKEN SEAL/SRC/MAP/MAP_006/MAP.o"(.rodata)
        "*/recon/tbs/unidentified.o"(.unidentified.084fb067)
        "*/games/THE BROKEN SEAL/SRC/GRAPHICS/TILESET/SET_05/PALETTE.o"(.rodata)
        "*/recon/tbs/unidentified.o"(.unidentified.084fb1f5)
        "*/games/THE BROKEN SEAL/SRC/GRAPHICS/TILESET/SET_05/TILES_A.o"(.rodata)
        "*/recon/tbs/unidentified.o"(.unidentified.084fcfa6)
        "*/games/THE BROKEN SEAL/SRC/GRAPHICS/TILESET/SET_05/TILES_B.o"(.rodata)
        "*/games/THE BROKEN SEAL/SRC/GRAPHICS/TILESET/SET_05/TILES_C.o"(.rodata)
        "*/recon/tbs/unidentified.o"(.unidentified.08500b1d)
        "*/games/THE BROKEN SEAL/SRC/GRAPHICS/TILESET/SET_05/TILES_D.o"(.rodata)
        "*/recon/tbs/unidentified.o"(.unidentified.0850202b)
        "*/games/THE BROKEN SEAL/SRC/MAP/MAP_007/MAP.o"(.rodata)
        "*/recon/tbs/unidentified.o"(.unidentified.08502bff)
        "*/games/THE BROKEN SEAL/SRC/GRAPHICS/TILESET/SET_06/PALETTE.o"(.rodata)
        "*/recon/tbs/unidentified.o"(.unidentified.08502cfd)
        "*/games/THE BROKEN SEAL/SRC/GRAPHICS/TILESET/SET_06/TILES_A.o"(.rodata)
        "*/recon/tbs/unidentified.o"(.unidentified.085040e2)
        "*/games/THE BROKEN SEAL/SRC/GRAPHICS/TILESET/SET_06/TILES_B.o"(.rodata)
        "*/recon/tbs/unidentified.o"(.unidentified.08505265)
        "*/games/THE BROKEN SEAL/SRC/GRAPHICS/TILESET/SET_06/TILES_C.o"(.rodata)
        "*/recon/tbs/unidentified.o"(.unidentified.08505bee)
        "*/games/THE BROKEN SEAL/SRC/GRAPHICS/TILESET/SET_06/TILES_D.o"(.rodata)
        "*/games/THE BROKEN SEAL/SRC/MAP/MAP_008/MAP.o"(.rodata)
        "*/recon/tbs/unidentified.o"(.unidentified.0850886b)
        "*/games/THE BROKEN SEAL/SRC/GRAPHICS/TILESET/SET_07/PALETTE.o"(.rodata)
        "*/recon/tbs/unidentified.o"(.unidentified.0850894e)
        "*/games/THE BROKEN SEAL/SRC/GRAPHICS/TILESET/SET_07/TILES_A.o"(.rodata)
        "*/recon/tbs/unidentified.o"(.unidentified.08509b39)
        "*/games/THE BROKEN SEAL/SRC/GRAPHICS/TILESET/SET_07/TILES_B.o"(.rodata)
        "*/recon/tbs/unidentified.o"(.unidentified.0850b7c1)
        "*/games/THE BROKEN SEAL/SRC/GRAPHICS/TILESET/SET_07/TILES_C.o"(.rodata)
        "*/recon/tbs/unidentified.o"(.unidentified.0850bccf)
        "*/games/THE BROKEN SEAL/SRC/GRAPHICS/TILESET/SET_07/TILES_D.o"(.rodata)
        "*/recon/tbs/unidentified.o"(.unidentified.0850be0f)
        "*/games/THE BROKEN SEAL/SRC/MAP/MAP_009/MAP.o"(.rodata)
        "*/recon/tbs/unidentified.o"(.unidentified.0850d02a)
        "*/games/THE BROKEN SEAL/SRC/GRAPHICS/TILESET/SET_08/PALETTE.o"(.rodata)
        "*/recon/tbs/unidentified.o"(.unidentified.0850d185)
        "*/games/THE BROKEN SEAL/SRC/GRAPHICS/TILESET/SET_08/TILES_A.o"(.rodata)
        "*/games/THE BROKEN SEAL/SRC/GRAPHICS/TILESET/SET_08/TILES_B.o"(.rodata)
        "*/recon/tbs/unidentified.o"(.unidentified.085115ab)
        "*/games/THE BROKEN SEAL/SRC/GRAPHICS/TILESET/SET_08/TILES_C.o"(.rodata)
        "*/games/THE BROKEN SEAL/SRC/GRAPHICS/TILESET/SET_08/TILES_D.o"(.rodata)
        "*/recon/tbs/unidentified.o"(.unidentified.085132da)
        "*/games/THE BROKEN SEAL/SRC/MAP/MAP_010/MAP.o"(.rodata)
        "*/recon/tbs/unidentified.o"(.unidentified.08514053)
        "*/games/THE BROKEN SEAL/SRC/GRAPHICS/TILESET/SET_09/PALETTE.o"(.rodata)
        "*/recon/tbs/unidentified.o"(.unidentified.08514187)
        "*/games/THE BROKEN SEAL/SRC/GRAPHICS/TILESET/SET_09/TILES_A.o"(.rodata)
        "*/recon/tbs/unidentified.o"(.unidentified.08516607)
        "*/games/THE BROKEN SEAL/SRC/GRAPHICS/TILESET/SET_09/TILES_B.o"(.rodata)
        "*/recon/tbs/unidentified.o"(.unidentified.08517383)
        "*/games/THE BROKEN SEAL/SRC/GRAPHICS/TILESET/SET_09/TILES_C.o"(.rodata)
        "*/recon/tbs/unidentified.o"(.unidentified.08517e62)
        "*/games/THE BROKEN SEAL/SRC/MAP/MAP_011/MAP.o"(.rodata)
        "*/recon/tbs/unidentified.o"(.unidentified.08518cda)
        "*/games/THE BROKEN SEAL/SRC/GRAPHICS/TILESET/SET_10/PALETTE.o"(.rodata)
        "*/games/THE BROKEN SEAL/SRC/GRAPHICS/TILESET/SET_10/TILES_A.o"(.rodata)
        "*/recon/tbs/unidentified.o"(.unidentified.0851adae)
        "*/games/THE BROKEN SEAL/SRC/GRAPHICS/TILESET/SET_10/TILES_B.o"(.rodata)
        "*/recon/tbs/unidentified.o"(.unidentified.0851b6f5)
        "*/games/THE BROKEN SEAL/SRC/GRAPHICS/TILESET/SET_10/TILES_C.o"(.rodata)
        "*/recon/tbs/unidentified.o"(.unidentified.0851c342)
        "*/games/THE BROKEN SEAL/SRC/GRAPHICS/TILESET/SET_10/TILES_D.o"(.rodata)
        "*/recon/tbs/unidentified.o"(.unidentified.0851c569)
        "*/games/THE BROKEN SEAL/SRC/MAP/MAP_012/MAP.o"(.rodata)
        "*/recon/tbs/unidentified.o"(.unidentified.0851d292)
        "*/games/THE BROKEN SEAL/SRC/MAP/MAP_013/MAP.o"(.rodata)
        "*/recon/tbs/unidentified.o"(.unidentified.0851deab)
        "*/games/THE BROKEN SEAL/SRC/GRAPHICS/TILESET/SET_11/PALETTE.o"(.rodata)
        "*/recon/tbs/unidentified.o"(.unidentified.0851dfbf)
        "*/games/THE BROKEN SEAL/SRC/GRAPHICS/TILESET/SET_11/TILES_A.o"(.rodata)
        "*/games/THE BROKEN SEAL/SRC/GRAPHICS/TILESET/SET_11/TILES_B.o"(.rodata)
        "*/recon/tbs/unidentified.o"(.unidentified.0851f985)
        "*/games/THE BROKEN SEAL/SRC/GRAPHICS/TILESET/SET_11/TILES_C.o"(.rodata)
        "*/recon/tbs/unidentified.o"(.unidentified.0851facf)
        "*/games/THE BROKEN SEAL/SRC/GRAPHICS/TILESET/SET_11/TILES_D.o"(.rodata)
        "*/games/THE BROKEN SEAL/SRC/MAP/MAP_014/MAP.o"(.rodata)
        "*/recon/tbs/unidentified.o"(.unidentified.08521b9b)
        "*/games/THE BROKEN SEAL/SRC/GRAPHICS/TILESET/SET_12/PALETTE.o"(.rodata)
        "*/recon/tbs/unidentified.o"(.unidentified.08521cc3)
        "*/games/THE BROKEN SEAL/SRC/GRAPHICS/TILESET/SET_12/TILES_A.o"(.rodata)
        "*/recon/tbs/unidentified.o"(.unidentified.0852354b)
        "*/games/THE BROKEN SEAL/SRC/GRAPHICS/TILESET/SET_12/TILES_B.o"(.rodata)
        "*/games/THE BROKEN SEAL/SRC/GRAPHICS/TILESET/SET_12/TILES_C.o"(.rodata)
        "*/recon/tbs/unidentified.o"(.unidentified.085257ed)
        "*/games/THE BROKEN SEAL/SRC/GRAPHICS/TILESET/SET_12/TILES_D.o"(.rodata)
        "*/recon/tbs/unidentified.o"(.unidentified.0852592f)
        "*/games/THE BROKEN SEAL/SRC/MAP/MAP_015/MAP.o"(.rodata)
        "*/recon/tbs/unidentified.o"(.unidentified.08527937)
        "*/games/THE BROKEN SEAL/SRC/GRAPHICS/TILESET/SET_13/PALETTE.o"(.rodata)
        "*/recon/tbs/unidentified.o"(.unidentified.08527a42)
        "*/games/THE BROKEN SEAL/SRC/GRAPHICS/TILESET/SET_13/TILES_A.o"(.rodata)
        "*/recon/tbs/unidentified.o"(.unidentified.08529a26)
        "*/games/THE BROKEN SEAL/SRC/GRAPHICS/TILESET/SET_13/TILES_B.o"(.rodata)
        "*/recon/tbs/unidentified.o"(.unidentified.0852b14b)
        "*/games/THE BROKEN SEAL/SRC/GRAPHICS/TILESET/SET_13/TILES_C.o"(.rodata)
        "*/games/THE BROKEN SEAL/SRC/GRAPHICS/TILESET/SET_13/TILES_D.o"(.rodata)
        "*/recon/tbs/unidentified.o"(.unidentified.0852c1ff)
        "*/games/THE BROKEN SEAL/SRC/MAP/MAP_016/MAP.o"(.rodata)
        "*/recon/tbs/unidentified.o"(.unidentified.0852dee6)
        "*/games/THE BROKEN SEAL/SRC/GRAPHICS/TILESET/PALETTES/PAL_00.o"(.rodata)
        "*/recon/tbs/unidentified.o"(.unidentified.0852e041)
        "*/games/THE BROKEN SEAL/SRC/MAP/MAP_017/MAP.o"(.rodata)
        "*/recon/tbs/unidentified.o"(.unidentified.0852ff8a)
        "*/games/THE BROKEN SEAL/SRC/GRAPHICS/TILESET/SET_14/PALETTE.o"(.rodata)
        "*/recon/tbs/unidentified.o"(.unidentified.0853010f)
        "*/games/THE BROKEN SEAL/SRC/GRAPHICS/TILESET/SET_14/TILES_A.o"(.rodata)
        "*/recon/tbs/unidentified.o"(.unidentified.08532c61)
        "*/games/THE BROKEN SEAL/SRC/GRAPHICS/TILESET/SET_14/TILES_B.o"(.rodata)
        "*/recon/tbs/unidentified.o"(.unidentified.08535326)
        "*/games/THE BROKEN SEAL/SRC/GRAPHICS/TILESET/SET_14/TILES_C.o"(.rodata)
        "*/recon/tbs/unidentified.o"(.unidentified.08537a7e)
        "*/games/THE BROKEN SEAL/SRC/GRAPHICS/TILESET/SET_14/TILES_D.o"(.rodata)
        "*/recon/tbs/unidentified.o"(.unidentified.085392d1)
        "*/games/THE BROKEN SEAL/SRC/MAP/MAP_018/MAP.o"(.rodata)
        "*/recon/tbs/unidentified.o"(.unidentified.0853b9d1)
        "*/games/THE BROKEN SEAL/SRC/GRAPHICS/TILESET/SET_15/PALETTE.o"(.rodata)
        "*/games/THE BROKEN SEAL/SRC/GRAPHICS/TILESET/SET_15/TILES_A.o"(.rodata)
        "*/recon/tbs/unidentified.o"(.unidentified.0853d79d)
        "*/games/THE BROKEN SEAL/SRC/GRAPHICS/TILESET/SET_15/TILES_B.o"(.rodata)
        "*/recon/tbs/unidentified.o"(.unidentified.0853fce7)
        "*/games/THE BROKEN SEAL/SRC/GRAPHICS/TILESET/SET_15/TILES_C.o"(.rodata)
        "*/recon/tbs/unidentified.o"(.unidentified.08540fb2)
        "*/games/THE BROKEN SEAL/SRC/GRAPHICS/TILESET/SET_15/TILES_D.o"(.rodata)
        "*/recon/tbs/unidentified.o"(.unidentified.08541c63)
        "*/games/THE BROKEN SEAL/SRC/MAP/MAP_019/MAP.o"(.rodata)
        "*/recon/tbs/unidentified.o"(.unidentified.085426cd)
        "*/games/THE BROKEN SEAL/SRC/GRAPHICS/TILESET/SET_16/PALETTE.o"(.rodata)
        "*/recon/tbs/unidentified.o"(.unidentified.085427c3)
        "*/games/THE BROKEN SEAL/SRC/GRAPHICS/TILESET/SET_16/TILES_A.o"(.rodata)
        "*/games/THE BROKEN SEAL/SRC/GRAPHICS/TILESET/SET_16/TILES_B.o"(.rodata)
        "*/games/THE BROKEN SEAL/SRC/GRAPHICS/TILESET/SET_16/TILES_C.o"(.rodata)
        "*/recon/tbs/unidentified.o"(.unidentified.08544222)
        "*/games/THE BROKEN SEAL/SRC/GRAPHICS/TILESET/SET_16/TILES_D.o"(.rodata)
        "*/recon/tbs/unidentified.o"(.unidentified.08544fc6)
        "*/games/THE BROKEN SEAL/SRC/MAP/MAP_020/MAP.o"(.rodata)
        "*/recon/tbs/unidentified.o"(.unidentified.08546aff)
        "*/games/THE BROKEN SEAL/SRC/GRAPHICS/TILESET/SET_17/PALETTE.o"(.rodata)
        "*/games/THE BROKEN SEAL/SRC/GRAPHICS/TILESET/SET_17/TILES_A.o"(.rodata)
        "*/recon/tbs/unidentified.o"(.unidentified.085499ed)
        "*/games/THE BROKEN SEAL/SRC/GRAPHICS/TILESET/SET_17/TILES_B.o"(.rodata)
        "*/games/THE BROKEN SEAL/SRC/GRAPHICS/TILESET/SET_17/TILES_C.o"(.rodata)
        "*/games/THE BROKEN SEAL/SRC/GRAPHICS/TILESET/SET_17/TILES_D.o"(.rodata)
        "*/games/THE BROKEN SEAL/SRC/MAP/MAP_021/MAP.o"(.rodata)
        "*/recon/tbs/unidentified.o"(.unidentified.085511d3)
        "*/games/THE BROKEN SEAL/SRC/GRAPHICS/TILESET/SET_18/PALETTE.o"(.rodata)
        "*/recon/tbs/unidentified.o"(.unidentified.0855129f)
        "*/games/THE BROKEN SEAL/SRC/GRAPHICS/TILESET/SET_18/TILES_A.o"(.rodata)
        "*/games/THE BROKEN SEAL/SRC/GRAPHICS/TILESET/SET_18/TILES_B.o"(.rodata)
        "*/games/THE BROKEN SEAL/SRC/GRAPHICS/TILESET/SET_18/TILES_C.o"(.rodata)
        "*/recon/tbs/unidentified.o"(.unidentified.08556b4a)
        "*/games/THE BROKEN SEAL/SRC/GRAPHICS/TILESET/SET_18/TILES_D.o"(.rodata)
        "*/recon/tbs/unidentified.o"(.unidentified.08556c8b)
        "*/games/THE BROKEN SEAL/SRC/MAP/MAP_022/MAP.o"(.rodata)
        "*/recon/tbs/unidentified.o"(.unidentified.085580b9)
        "*/games/THE BROKEN SEAL/SRC/GRAPHICS/TILESET/SET_19/PALETTE.o"(.rodata)
        "*/games/THE BROKEN SEAL/SRC/GRAPHICS/TILESET/SET_19/TILES_A.o"(.rodata)
        "*/recon/tbs/unidentified.o"(.unidentified.0855adf6)
        "*/games/THE BROKEN SEAL/SRC/GRAPHICS/TILESET/SET_19/TILES_B.o"(.rodata)
        "*/recon/tbs/unidentified.o"(.unidentified.0855cef2)
        "*/games/THE BROKEN SEAL/SRC/GRAPHICS/TILESET/SET_19/TILES_C.o"(.rodata)
        "*/games/THE BROKEN SEAL/SRC/GRAPHICS/TILESET/SET_19/TILES_D.o"(.rodata)
        "*/games/THE BROKEN SEAL/SRC/MAP/MAP_023/MAP.o"(.rodata)
        "*/recon/tbs/unidentified.o"(.unidentified.08560fce)
        "*/games/THE BROKEN SEAL/SRC/MAP/MAP_024/MAP.o"(.rodata)
        "*/recon/tbs/unidentified.o"(.unidentified.08561f13)
        "*/games/THE BROKEN SEAL/SRC/MAP/MAP_025/MAP.o"(.rodata)
        "*/recon/tbs/unidentified.o"(.unidentified.085648fa)
        "*/games/THE BROKEN SEAL/SRC/GRAPHICS/TILESET/SET_20/PALETTE.o"(.rodata)
        "*/recon/tbs/unidentified.o"(.unidentified.08564a96)
        "*/games/THE BROKEN SEAL/SRC/GRAPHICS/TILESET/SET_20/TILES_A.o"(.rodata)
        "*/games/THE BROKEN SEAL/SRC/GRAPHICS/TILESET/SET_20/TILES_B.o"(.rodata)
        "*/recon/tbs/unidentified.o"(.unidentified.08569331)
        "*/games/THE BROKEN SEAL/SRC/GRAPHICS/TILESET/SET_20/TILES_C.o"(.rodata)
        "*/games/THE BROKEN SEAL/SRC/GRAPHICS/TILESET/SET_20/TILES_D.o"(.rodata)
        "*/recon/tbs/unidentified.o"(.unidentified.0856b832)
        "*/games/THE BROKEN SEAL/SRC/MAP/MAP_026/MAP.o"(.rodata)
        "*/recon/tbs/unidentified.o"(.unidentified.0856e772)
        "*/games/THE BROKEN SEAL/SRC/MAP/MAP_027/MAP.o"(.rodata)
        "*/recon/tbs/unidentified.o"(.unidentified.0857153f)
        "*/games/THE BROKEN SEAL/SRC/MAP/MAP_028/MAP.o"(.rodata)
        "*/recon/tbs/unidentified.o"(.unidentified.08573223)
        "*/games/THE BROKEN SEAL/SRC/GRAPHICS/TILESET/SET_21/PALETTE.o"(.rodata)
        "*/recon/tbs/unidentified.o"(.unidentified.085733be)
        "*/games/THE BROKEN SEAL/SRC/GRAPHICS/TILESET/SET_21/TILES_A.o"(.rodata)
        "*/recon/tbs/unidentified.o"(.unidentified.08575f6d)
        "*/games/THE BROKEN SEAL/SRC/GRAPHICS/TILESET/SET_21/TILES_B.o"(.rodata)
        "*/recon/tbs/unidentified.o"(.unidentified.08578041)
        "*/games/THE BROKEN SEAL/SRC/GRAPHICS/TILESET/SET_21/TILES_C.o"(.rodata)
        "*/recon/tbs/unidentified.o"(.unidentified.0857a09a)
        "*/games/THE BROKEN SEAL/SRC/MAP/MAP_029/MAP.o"(.rodata)
        "*/recon/tbs/unidentified.o"(.unidentified.0857d531)
        "*/games/THE BROKEN SEAL/SRC/GRAPHICS/TILESET/SET_22/PALETTE.o"(.rodata)
        "*/games/THE BROKEN SEAL/SRC/GRAPHICS/TILESET/SET_22/TILES_A.o"(.rodata)
        "*/recon/tbs/unidentified.o"(.unidentified.0858020d)
        "*/games/THE BROKEN SEAL/SRC/GRAPHICS/TILESET/SET_22/TILES_B.o"(.rodata)
        "*/recon/tbs/unidentified.o"(.unidentified.08581fdf)
        "*/games/THE BROKEN SEAL/SRC/GRAPHICS/TILESET/SET_22/TILES_C.o"(.rodata)
        "*/recon/tbs/unidentified.o"(.unidentified.0858211f)
        "*/games/THE BROKEN SEAL/SRC/MAP/MAP_030/MAP.o"(.rodata)
        "*/recon/tbs/unidentified.o"(.unidentified.08583423)
        "*/games/THE BROKEN SEAL/SRC/MAP/MAP_031/MAP.o"(.rodata)
        "*/recon/tbs/unidentified.o"(.unidentified.08585179)
        "*/games/THE BROKEN SEAL/SRC/GRAPHICS/TILESET/SET_23/PALETTE.o"(.rodata)
        "*/games/THE BROKEN SEAL/SRC/GRAPHICS/TILESET/SET_23/TILES_A.o"(.rodata)
        "*/recon/tbs/unidentified.o"(.unidentified.085880f6)
        "*/games/THE BROKEN SEAL/SRC/GRAPHICS/TILESET/SET_23/TILES_B.o"(.rodata)
        "*/recon/tbs/unidentified.o"(.unidentified.0858a9bd)
        "*/games/THE BROKEN SEAL/SRC/GRAPHICS/TILESET/SET_23/TILES_C.o"(.rodata)
        "*/games/THE BROKEN SEAL/SRC/GRAPHICS/TILESET/SET_23/TILES_D.o"(.rodata)
        "*/games/THE BROKEN SEAL/SRC/MAP/MAP_032/MAP.o"(.rodata)
        "*/recon/tbs/unidentified.o"(.unidentified.08591925)
        "*/games/THE BROKEN SEAL/SRC/GRAPHICS/TILESET/SET_24/PALETTE.o"(.rodata)
        "*/games/THE BROKEN SEAL/SRC/GRAPHICS/TILESET/SET_24/TILES_A.o"(.rodata)
        "*/recon/tbs/unidentified.o"(.unidentified.085931cb)
        "*/games/THE BROKEN SEAL/SRC/GRAPHICS/TILESET/SET_24/TILES_B.o"(.rodata)
        "*/recon/tbs/unidentified.o"(.unidentified.08593aca)
        "*/games/THE BROKEN SEAL/SRC/MAP/MAP_033/MAP.o"(.rodata)
        "*/recon/tbs/unidentified.o"(.unidentified.08594843)
        "*/games/THE BROKEN SEAL/SRC/GRAPHICS/TILESET/SET_25/PALETTE.o"(.rodata)
        "*/recon/tbs/unidentified.o"(.unidentified.085949a3)
        "*/games/THE BROKEN SEAL/SRC/GRAPHICS/TILESET/SET_25/TILES_A.o"(.rodata)
        "*/recon/tbs/unidentified.o"(.unidentified.085965fb)
        "*/games/THE BROKEN SEAL/SRC/MAP/MAP_034/MAP.o"(.rodata)
        "*/recon/tbs/unidentified.o"(.unidentified.08597e97)
        "*/games/THE BROKEN SEAL/SRC/GRAPHICS/TILESET/SET_26/PALETTE.o"(.rodata)
        "*/recon/tbs/unidentified.o"(.unidentified.0859801b)
        "*/games/THE BROKEN SEAL/SRC/GRAPHICS/TILESET/SET_26/TILES_A.o"(.rodata)
        "*/recon/tbs/unidentified.o"(.unidentified.0859ab57)
        "*/games/THE BROKEN SEAL/SRC/GRAPHICS/TILESET/SET_26/TILES_B.o"(.rodata)
        "*/recon/tbs/unidentified.o"(.unidentified.0859d2d1)
        "*/games/THE BROKEN SEAL/SRC/GRAPHICS/TILESET/SET_26/TILES_C.o"(.rodata)
        "*/recon/tbs/unidentified.o"(.unidentified.0859e2be)
        "*/games/THE BROKEN SEAL/SRC/MAP/MAP_035/MAP.o"(.rodata)
        "*/recon/tbs/unidentified.o"(.unidentified.0859f98b)
        "*/games/THE BROKEN SEAL/SRC/GRAPHICS/TILESET/SET_27/PALETTE.o"(.rodata)
        "*/recon/tbs/unidentified.o"(.unidentified.0859fb35)
        "*/games/THE BROKEN SEAL/SRC/GRAPHICS/TILESET/SET_27/TILES_A.o"(.rodata)
        "*/recon/tbs/unidentified.o"(.unidentified.085a28c9)
        "*/games/THE BROKEN SEAL/SRC/GRAPHICS/TILESET/SET_27/TILES_B.o"(.rodata)
        "*/games/THE BROKEN SEAL/SRC/GRAPHICS/TILESET/SET_27/TILES_C.o"(.rodata)
        "*/recon/tbs/unidentified.o"(.unidentified.085a695e)
        "*/games/THE BROKEN SEAL/SRC/GRAPHICS/TILESET/SET_27/TILES_D.o"(.rodata)
        "*/recon/tbs/unidentified.o"(.unidentified.085a6a9f)
        "*/games/THE BROKEN SEAL/SRC/MAP/MAP_036/MAP.o"(.rodata)
        "*/recon/tbs/unidentified.o"(.unidentified.085a8967)
        "*/games/THE BROKEN SEAL/SRC/GRAPHICS/TILESET/SET_28/PALETTE.o"(.rodata)
        "*/recon/tbs/unidentified.o"(.unidentified.085a8b09)
        "*/games/THE BROKEN SEAL/SRC/GRAPHICS/TILESET/SET_28/TILES_A.o"(.rodata)
        "*/recon/tbs/unidentified.o"(.unidentified.085aabab)
        "*/games/THE BROKEN SEAL/SRC/GRAPHICS/TILESET/SET_28/TILES_B.o"(.rodata)
        "*/recon/tbs/unidentified.o"(.unidentified.085abb38)
        "*/games/THE BROKEN SEAL/SRC/GRAPHICS/TILESET/SET_28/TILES_D.o"(.rodata)
        "*/games/THE BROKEN SEAL/SRC/MAP/MAP_037/MAP.o"(.rodata)
        "*/recon/tbs/unidentified.o"(.unidentified.085b0901)
        "*/games/THE BROKEN SEAL/SRC/GRAPHICS/TILESET/SET_29/PALETTE.o"(.rodata)
        "*/recon/tbs/unidentified.o"(.unidentified.085b0a86)
        "*/games/THE BROKEN SEAL/SRC/GRAPHICS/TILESET/SET_29/TILES_A.o"(.rodata)
        "*/games/THE BROKEN SEAL/SRC/GRAPHICS/TILESET/SET_29/TILES_B.o"(.rodata)
        "*/games/THE BROKEN SEAL/SRC/GRAPHICS/TILESET/SET_29/TILES_C.o"(.rodata)
        "*/recon/tbs/unidentified.o"(.unidentified.085b81d3)
        "*/games/THE BROKEN SEAL/SRC/GRAPHICS/TILESET/SET_29/TILES_D.o"(.rodata)
        "*/recon/tbs/unidentified.o"(.unidentified.085b86dd)
        "*/games/THE BROKEN SEAL/SRC/MAP/MAP_038/MAP.o"(.rodata)
        "*/recon/tbs/unidentified.o"(.unidentified.085b9db5)
        "*/games/THE BROKEN SEAL/SRC/GRAPHICS/TILESET/SET_30/PALETTE.o"(.rodata)
        "*/recon/tbs/unidentified.o"(.unidentified.085b9f59)
        "*/games/THE BROKEN SEAL/SRC/GRAPHICS/TILESET/SET_30/TILES_A.o"(.rodata)
        "*/recon/tbs/unidentified.o"(.unidentified.085bb85e)
        "*/games/THE BROKEN SEAL/SRC/MAP/MAP_039/MAP.o"(.rodata)
        "*/recon/tbs/unidentified.o"(.unidentified.085bd08b)
        "*/games/THE BROKEN SEAL/SRC/GRAPHICS/TILESET/SET_31/PALETTE.o"(.rodata)
        "*/recon/tbs/unidentified.o"(.unidentified.085bd209)
        "*/games/THE BROKEN SEAL/SRC/GRAPHICS/TILESET/SET_31/TILES_A.o"(.rodata)
        "*/games/THE BROKEN SEAL/SRC/GRAPHICS/TILESET/SET_31/TILES_B.o"(.rodata)
        "*/recon/tbs/unidentified.o"(.unidentified.085c1afd)
        "*/games/THE BROKEN SEAL/SRC/GRAPHICS/TILESET/SET_31/TILES_C.o"(.rodata)
        "*/recon/tbs/unidentified.o"(.unidentified.085c2b42)
        "*/games/THE BROKEN SEAL/SRC/GRAPHICS/TILESET/SET_31/TILES_D.o"(.rodata)
        "*/recon/tbs/unidentified.o"(.unidentified.085c3966)
        "*/games/THE BROKEN SEAL/SRC/MAP/MAP_040/MAP.o"(.rodata)
        "*/recon/tbs/unidentified.o"(.unidentified.085c4cab)
        "*/games/THE BROKEN SEAL/SRC/GRAPHICS/TILESET/PALETTES/PAL_01.o"(.rodata)
        "*/recon/tbs/unidentified.o"(.unidentified.085c4e05)
        "*/games/THE BROKEN SEAL/SRC/MAP/MAP_041/MAP.o"(.rodata)
        "*/recon/tbs/unidentified.o"(.unidentified.085c73c3)
        "*/games/THE BROKEN SEAL/SRC/GRAPHICS/TILESET/SET_32/PALETTE.o"(.rodata)
        "*/recon/tbs/unidentified.o"(.unidentified.085c753a)
        "*/games/THE BROKEN SEAL/SRC/GRAPHICS/TILESET/SET_32/TILES_A.o"(.rodata)
        "*/games/THE BROKEN SEAL/SRC/GRAPHICS/TILESET/SET_32/TILES_B.o"(.rodata)
        "*/recon/tbs/unidentified.o"(.unidentified.085cbe2d)
        "*/games/THE BROKEN SEAL/SRC/GRAPHICS/TILESET/SET_32/TILES_C.o"(.rodata)
        "*/recon/tbs/unidentified.o"(.unidentified.085cc895)
        "*/games/THE BROKEN SEAL/SRC/GRAPHICS/TILESET/SET_32/TILES_D.o"(.rodata)
        "*/games/THE BROKEN SEAL/SRC/MAP/MAP_042/MAP.o"(.rodata)
        "*/recon/tbs/unidentified.o"(.unidentified.085ceed7)
        "*/games/THE BROKEN SEAL/SRC/GRAPHICS/TILESET/SET_33/PALETTE.o"(.rodata)
        "*/recon/tbs/unidentified.o"(.unidentified.085cf03e)
        "*/games/THE BROKEN SEAL/SRC/GRAPHICS/TILESET/SET_33/TILES_A.o"(.rodata)
        "*/recon/tbs/unidentified.o"(.unidentified.085d0185)
        "*/games/THE BROKEN SEAL/SRC/MAP/MAP_043/MAP.o"(.rodata)
        "*/recon/tbs/unidentified.o"(.unidentified.085d1ee3)
        "*/games/THE BROKEN SEAL/SRC/GRAPHICS/TILESET/PALETTES/PAL_02.o"(.rodata)
        "*/recon/tbs/unidentified.o"(.unidentified.085d204a)
        "*/games/THE BROKEN SEAL/SRC/MAP/MAP_044/MAP.o"(.rodata)
        "*/recon/tbs/unidentified.o"(.unidentified.085d48d9)
        "*/games/THE BROKEN SEAL/SRC/GRAPHICS/TILESET/SET_34/PALETTE.o"(.rodata)
        "*/recon/tbs/unidentified.o"(.unidentified.085d4a0e)
        "*/games/THE BROKEN SEAL/SRC/GRAPHICS/TILESET/SET_34/TILES_A.o"(.rodata)
        "*/recon/tbs/unidentified.o"(.unidentified.085d764a)
        "*/games/THE BROKEN SEAL/SRC/GRAPHICS/TILESET/SET_34/TILES_B.o"(.rodata)
        "*/games/THE BROKEN SEAL/SRC/GRAPHICS/TILESET/SET_34/TILES_C.o"(.rodata)
        "*/recon/tbs/unidentified.o"(.unidentified.085dade9)
        "*/games/THE BROKEN SEAL/SRC/GRAPHICS/TILESET/SET_34/TILES_D.o"(.rodata)
        "*/games/THE BROKEN SEAL/SRC/MAP/MAP_045/MAP.o"(.rodata)
        "*/recon/tbs/unidentified.o"(.unidentified.085de137)
        "*/games/THE BROKEN SEAL/SRC/GRAPHICS/TILESET/SET_35/PALETTE.o"(.rodata)
        "*/recon/tbs/unidentified.o"(.unidentified.085de2b3)
        "*/games/THE BROKEN SEAL/SRC/GRAPHICS/TILESET/SET_35/TILES_A.o"(.rodata)
        "*/recon/tbs/unidentified.o"(.unidentified.085e0e62)
        "*/games/THE BROKEN SEAL/SRC/GRAPHICS/TILESET/SET_35/TILES_B.o"(.rodata)
        "*/recon/tbs/unidentified.o"(.unidentified.085e30d6)
        "*/games/THE BROKEN SEAL/SRC/GRAPHICS/TILESET/SET_35/TILES_C.o"(.rodata)
        "*/recon/tbs/unidentified.o"(.unidentified.085e5947)
        "*/games/THE BROKEN SEAL/SRC/GRAPHICS/TILESET/SET_35/TILES_D.o"(.rodata)
        "*/games/THE BROKEN SEAL/SRC/MAP/MAP_046/MAP.o"(.rodata)
        "*/games/THE BROKEN SEAL/SRC/GRAPHICS/TILESET/SET_36/PALETTE.o"(.rodata)
        "*/recon/tbs/unidentified.o"(.unidentified.085e8e3b)
        "*/games/THE BROKEN SEAL/SRC/GRAPHICS/TILESET/SET_36/TILES_A.o"(.rodata)
        "*/games/THE BROKEN SEAL/SRC/GRAPHICS/TILESET/SET_36/TILES_B.o"(.rodata)
        "*/recon/tbs/unidentified.o"(.unidentified.085eda62)
        "*/games/THE BROKEN SEAL/SRC/GRAPHICS/TILESET/SET_36/TILES_C.o"(.rodata)
        "*/recon/tbs/unidentified.o"(.unidentified.085ee6e5)
        "*/games/THE BROKEN SEAL/SRC/GRAPHICS/TILESET/SET_36/TILES_D.o"(.rodata)
        "*/recon/tbs/unidentified.o"(.unidentified.085ee827)
        "*/games/THE BROKEN SEAL/SRC/MAP/MAP_047/MAP.o"(.rodata)
        "*/recon/tbs/unidentified.o"(.unidentified.085efd97)
        "*/games/THE BROKEN SEAL/SRC/GRAPHICS/TILESET/SET_37/PALETTE.o"(.rodata)
        "*/recon/tbs/unidentified.o"(.unidentified.085eff02)
        "*/games/THE BROKEN SEAL/SRC/GRAPHICS/TILESET/SET_37/TILES_A.o"(.rodata)
        "*/recon/tbs/unidentified.o"(.unidentified.085f1c5d)
        "*/games/THE BROKEN SEAL/SRC/GRAPHICS/TILESET/SET_37/TILES_B.o"(.rodata)
        "*/recon/tbs/unidentified.o"(.unidentified.085f1d9f)
        "*/games/THE BROKEN SEAL/SRC/GRAPHICS/TILESET/SET_37/TILES_C.o"(.rodata)
        "*/recon/tbs/unidentified.o"(.unidentified.085f459e)
        "*/games/THE BROKEN SEAL/SRC/GRAPHICS/TILESET/SET_37/TILES_D.o"(.rodata)
        "*/recon/tbs/unidentified.o"(.unidentified.085f46df)
        "*/games/THE BROKEN SEAL/SRC/MAP/MAP_048/MAP.o"(.rodata)
        "*/recon/tbs/unidentified.o"(.unidentified.085f60f7)
        "*/games/THE BROKEN SEAL/SRC/GRAPHICS/TILESET/SET_38/PALETTE.o"(.rodata)
        "*/games/THE BROKEN SEAL/SRC/GRAPHICS/TILESET/SET_38/TILES_A.o"(.rodata)
        "*/recon/tbs/unidentified.o"(.unidentified.085f7672)
        "*/games/THE BROKEN SEAL/SRC/MAP/MAP_049/MAP.o"(.rodata)
        "*/recon/tbs/unidentified.o"(.unidentified.085f8bae)
        "*/games/THE BROKEN SEAL/SRC/GRAPHICS/TILESET/SET_39/PALETTE.o"(.rodata)
        "*/recon/tbs/unidentified.o"(.unidentified.085f8d3e)
        "*/games/THE BROKEN SEAL/SRC/GRAPHICS/TILESET/SET_39/TILES_A.o"(.rodata)
        "*/recon/tbs/unidentified.o"(.unidentified.085faff7)
        "*/games/THE BROKEN SEAL/SRC/MAP/MAP_050/MAP.o"(.rodata)
        "*/games/THE BROKEN SEAL/SRC/GRAPHICS/TILESET/SET_40/PALETTE.o"(.rodata)
        "*/games/THE BROKEN SEAL/SRC/GRAPHICS/TILESET/SET_40/TILES_A.o"(.rodata)
        "*/recon/tbs/unidentified.o"(.unidentified.085ff23e)
        "*/games/THE BROKEN SEAL/SRC/MAP/MAP_051/MAP.o"(.rodata)
        "*/games/THE BROKEN SEAL/SRC/GRAPHICS/TILESET/SET_41/PALETTE.o"(.rodata)
        "*/recon/tbs/unidentified.o"(.unidentified.0860101d)
        "*/games/THE BROKEN SEAL/SRC/GRAPHICS/TILESET/SET_41/TILES_A.o"(.rodata)
        "*/games/THE BROKEN SEAL/SRC/GRAPHICS/TILESET/SET_41/TILES_B.o"(.rodata)
        "*/recon/tbs/unidentified.o"(.unidentified.086041cb)
        "*/games/THE BROKEN SEAL/SRC/GRAPHICS/TILESET/SET_41/TILES_C.o"(.rodata)
        "*/recon/tbs/unidentified.o"(.unidentified.086067ff)
        "*/games/THE BROKEN SEAL/SRC/GRAPHICS/TILESET/SET_41/TILES_D.o"(.rodata)
        "*/games/THE BROKEN SEAL/SRC/MAP/MAP_052/MAP.o"(.rodata)
        "*/recon/tbs/unidentified.o"(.unidentified.08609357)
        "*/games/THE BROKEN SEAL/SRC/GRAPHICS/TILESET/SET_42/PALETTE.o"(.rodata)
        "*/recon/tbs/unidentified.o"(.unidentified.0860951f)
        "*/games/THE BROKEN SEAL/SRC/GRAPHICS/TILESET/SET_42/TILES_B.o"(.rodata)
        "*/games/THE BROKEN SEAL/SRC/GRAPHICS/TILESET/SET_42/TILES_C.o"(.rodata)
        "*/recon/tbs/unidentified.o"(.unidentified.0860f929)
        "*/games/THE BROKEN SEAL/SRC/GRAPHICS/TILESET/SET_42/TILES_D.o"(.rodata)
        "*/recon/tbs/unidentified.o"(.unidentified.08610e9a)
        "*/games/THE BROKEN SEAL/SRC/MAP/MAP_053/MAP.o"(.rodata)
        "*/recon/tbs/unidentified.o"(.unidentified.08611cb3)
        "*/games/THE BROKEN SEAL/SRC/MAP/MAP_054/MAP.o"(.rodata)
        "*/recon/tbs/unidentified.o"(.unidentified.086136c1)
        "*/games/THE BROKEN SEAL/SRC/GRAPHICS/TILESET/SET_43/PALETTE.o"(.rodata)
        "*/recon/tbs/unidentified.o"(.unidentified.08613831)
        "*/games/THE BROKEN SEAL/SRC/GRAPHICS/TILESET/SET_43/TILES_A.o"(.rodata)
        "*/recon/tbs/unidentified.o"(.unidentified.086160f3)
        "*/games/THE BROKEN SEAL/SRC/GRAPHICS/TILESET/SET_43/TILES_B.o"(.rodata)
        "*/recon/tbs/unidentified.o"(.unidentified.086188bb)
        "*/games/THE BROKEN SEAL/SRC/GRAPHICS/TILESET/SET_43/TILES_C.o"(.rodata)
        "*/recon/tbs/unidentified.o"(.unidentified.08619bb5)
        "*/games/THE BROKEN SEAL/SRC/GRAPHICS/TILESET/SET_43/TILES_D.o"(.rodata)
        "*/recon/tbs/unidentified.o"(.unidentified.0861b4fb)
        "*/games/THE BROKEN SEAL/SRC/MAP/MAP_055/MAP.o"(.rodata)
        "*/recon/tbs/unidentified.o"(.unidentified.0861d005)
        "*/games/THE BROKEN SEAL/SRC/MAP/MAP_056/MAP.o"(.rodata)
        "*/games/THE BROKEN SEAL/SRC/MAP/MAP_057/MAP.o"(.rodata)
        "*/recon/tbs/unidentified.o"(.unidentified.0862096f)
        "*/games/THE BROKEN SEAL/SRC/MAP/MAP_058/MAP.o"(.rodata)
        "*/recon/tbs/unidentified.o"(.unidentified.08622ae7)
        "*/games/THE BROKEN SEAL/SRC/MAP/MAP_059/MAP.o"(.rodata)
        "*/recon/tbs/unidentified.o"(.unidentified.08623a0e)
        "*/games/THE BROKEN SEAL/SRC/MAP/MAP_060/MAP.o"(.rodata)
        "*/recon/tbs/unidentified.o"(.unidentified.0862698e)
        "*/games/THE BROKEN SEAL/SRC/GRAPHICS/TILESET/SET_44/PALETTE.o"(.rodata)
        "*/recon/tbs/unidentified.o"(.unidentified.08626b4e)
        "*/games/THE BROKEN SEAL/SRC/GRAPHICS/TILESET/SET_44/TILES_A.o"(.rodata)
        "*/games/THE BROKEN SEAL/SRC/MAP/MAP_061/MAP.o"(.rodata)
        "*/games/THE BROKEN SEAL/SRC/GRAPHICS/TILESET/SET_45/PALETTE.o"(.rodata)
        "*/recon/tbs/unidentified.o"(.unidentified.08629eb5)
        "*/games/THE BROKEN SEAL/SRC/GRAPHICS/TILESET/SET_45/TILES_A.o"(.rodata)
        "*/recon/tbs/unidentified.o"(.unidentified.0862c3a6)
        "*/games/THE BROKEN SEAL/SRC/GRAPHICS/TILESET/SET_45/TILES_B.o"(.rodata)
        "*/games/THE BROKEN SEAL/SRC/GRAPHICS/TILESET/SET_45/TILES_C.o"(.rodata)
        "*/recon/tbs/unidentified.o"(.unidentified.0862f187)
        "*/games/THE BROKEN SEAL/SRC/GRAPHICS/TILESET/SET_45/TILES_D.o"(.rodata)
        "*/recon/tbs/unidentified.o"(.unidentified.0862fd21)
        "*/games/THE BROKEN SEAL/SRC/MAP/MAP_062/MAP.o"(.rodata)
        "*/recon/tbs/unidentified.o"(.unidentified.08630b82)
        "*/games/THE BROKEN SEAL/SRC/GRAPHICS/TILESET/PALETTES/PAL_03.o"(.rodata)
        "*/recon/tbs/unidentified.o"(.unidentified.08630cda)
        "*/games/THE BROKEN SEAL/SRC/MAP/MAP_063/MAP.o"(.rodata)
        "*/recon/tbs/unidentified.o"(.unidentified.0863193f)
        "*/games/THE BROKEN SEAL/SRC/MAP/MAP_064/MAP.o"(.rodata)
        "*/recon/tbs/unidentified.o"(.unidentified.0863270f)
        "*/games/THE BROKEN SEAL/SRC/MAP/MAP_065/MAP.o"(.rodata)
        "*/recon/tbs/unidentified.o"(.unidentified.0863399e)
        "*/games/THE BROKEN SEAL/SRC/MAP/MAP_066/MAP.o"(.rodata)
        "*/recon/tbs/unidentified.o"(.unidentified.08634886)
        "*/games/THE BROKEN SEAL/SRC/MAP/MAP_067/MAP.o"(.rodata)
        "*/recon/tbs/unidentified.o"(.unidentified.0863595f)
        "*/games/THE BROKEN SEAL/SRC/MAP/MAP_068/MAP.o"(.rodata)
        "*/recon/tbs/unidentified.o"(.unidentified.08638b27)
        "*/games/THE BROKEN SEAL/SRC/GRAPHICS/TILESET/SET_46/PALETTE.o"(.rodata)
        "*/recon/tbs/unidentified.o"(.unidentified.08638c93)
        "*/games/THE BROKEN SEAL/SRC/GRAPHICS/TILESET/SET_46/TILES_A.o"(.rodata)
        "*/recon/tbs/unidentified.o"(.unidentified.0863ba2f)
        "*/games/THE BROKEN SEAL/SRC/GRAPHICS/TILESET/SET_46/TILES_B.o"(.rodata)
        "*/recon/tbs/unidentified.o"(.unidentified.0863dbbe)
        "*/games/THE BROKEN SEAL/SRC/GRAPHICS/TILESET/SET_46/TILES_C.o"(.rodata)
        "*/recon/tbs/unidentified.o"(.unidentified.0863e2c6)
        "*/games/THE BROKEN SEAL/SRC/GRAPHICS/TILESET/SET_46/TILES_D.o"(.rodata)
        "*/recon/tbs/unidentified.o"(.unidentified.0863eeda)
        "*/games/THE BROKEN SEAL/SRC/MAP/MAP_069/MAP.o"(.rodata)
        "*/recon/tbs/unidentified.o"(.unidentified.086424ae)
        "*/games/THE BROKEN SEAL/SRC/MAP/MAP_070/MAP.o"(.rodata)
        "*/recon/tbs/unidentified.o"(.unidentified.08645fb6)
        "*/games/THE BROKEN SEAL/SRC/MAP/MAP_071/MAP.o"(.rodata)
        "*/recon/tbs/unidentified.o"(.unidentified.08649cc6)
        "*/games/THE BROKEN SEAL/SRC/MAP/MAP_072/MAP.o"(.rodata)
        "*/recon/tbs/unidentified.o"(.unidentified.0864dd25)
        "*/games/THE BROKEN SEAL/SRC/MAP/MAP_073/MAP.o"(.rodata)
        "*/recon/tbs/unidentified.o"(.unidentified.0864ffad)
        "*/games/THE BROKEN SEAL/SRC/GRAPHICS/TILESET/SET_47/PALETTE.o"(.rodata)
        "*/recon/tbs/unidentified.o"(.unidentified.08650142)
        "*/games/THE BROKEN SEAL/SRC/GRAPHICS/TILESET/SET_47/TILES_A.o"(.rodata)
        "*/recon/tbs/unidentified.o"(.unidentified.08651652)
        "*/games/THE BROKEN SEAL/SRC/GRAPHICS/TILESET/SET_47/TILES_B.o"(.rodata)
        "*/recon/tbs/unidentified.o"(.unidentified.08653437)
        "*/games/THE BROKEN SEAL/SRC/GRAPHICS/TILESET/SET_47/TILES_C.o"(.rodata)
        "*/recon/tbs/unidentified.o"(.unidentified.086544ca)
        "*/games/THE BROKEN SEAL/SRC/GRAPHICS/TILESET/SET_47/TILES_D.o"(.rodata)
        "*/games/THE BROKEN SEAL/SRC/MAP/MAP_074/MAP.o"(.rodata)
        "*/recon/tbs/unidentified.o"(.unidentified.0865673a)
        "*/games/THE BROKEN SEAL/SRC/GRAPHICS/TILESET/PALETTES/PAL_04.o"(.rodata)
        "*/recon/tbs/unidentified.o"(.unidentified.086568d1)
        "*/games/THE BROKEN SEAL/SRC/MAP/MAP_075/MAP.o"(.rodata)
        "*/recon/tbs/unidentified.o"(.unidentified.08658877)
        "*/games/THE BROKEN SEAL/SRC/GRAPHICS/TILESET/SET_48/PALETTE.o"(.rodata)
        "*/games/THE BROKEN SEAL/SRC/GRAPHICS/TILESET/SET_48/TILES_A.o"(.rodata)
        "*/games/THE BROKEN SEAL/SRC/GRAPHICS/TILESET/SET_48/TILES_B.o"(.rodata)
        "*/recon/tbs/unidentified.o"(.unidentified.0865d64e)
        "*/games/THE BROKEN SEAL/SRC/GRAPHICS/TILESET/SET_48/TILES_C.o"(.rodata)
        "*/games/THE BROKEN SEAL/SRC/GRAPHICS/TILESET/SET_48/TILES_D.o"(.rodata)
        "*/recon/tbs/unidentified.o"(.unidentified.086610af)
        "*/games/THE BROKEN SEAL/SRC/MAP/MAP_076/MAP.o"(.rodata)
        "*/games/THE BROKEN SEAL/SRC/GRAPHICS/TILESET/SET_49/PALETTE.o"(.rodata)
        "*/recon/tbs/unidentified.o"(.unidentified.08663de5)
        "*/games/THE BROKEN SEAL/SRC/GRAPHICS/TILESET/SET_49/TILES_A.o"(.rodata)
        "*/recon/tbs/unidentified.o"(.unidentified.0866612d)
        "*/games/THE BROKEN SEAL/SRC/MAP/MAP_077/MAP.o"(.rodata)
        "*/recon/tbs/unidentified.o"(.unidentified.0866790b)
        "*/games/THE BROKEN SEAL/SRC/GRAPHICS/TILESET/PALETTES/PAL_05.o"(.rodata)
        "*/recon/tbs/unidentified.o"(.unidentified.08667abd)
        "*/games/THE BROKEN SEAL/SRC/MAP/MAP_078/MAP.o"(.rodata)
        "*/recon/tbs/unidentified.o"(.unidentified.08669033)
        "*/games/THE BROKEN SEAL/SRC/MAP/MAP_079/MAP.o"(.rodata)
        "*/recon/tbs/unidentified.o"(.unidentified.0866ba02)
        "*/games/THE BROKEN SEAL/SRC/MAP/MAP_080/MAP.o"(.rodata)
        "*/recon/tbs/unidentified.o"(.unidentified.0866dccb)
        "*/games/THE BROKEN SEAL/SRC/MAP/MAP_081/MAP.o"(.rodata)
        "*/recon/tbs/unidentified.o"(.unidentified.0866f2a1)
        "*/games/THE BROKEN SEAL/SRC/MAP/MAP_082/MAP.o"(.rodata)
        "*/recon/tbs/unidentified.o"(.unidentified.08671362)
        "*/games/THE BROKEN SEAL/SRC/MAP/MAP_083/MAP.o"(.rodata)
        "*/recon/tbs/unidentified.o"(.unidentified.0867368d)
        "*/games/THE BROKEN SEAL/SRC/MAP/MAP_084/MAP.o"(.rodata)
        "*/recon/tbs/unidentified.o"(.unidentified.086762b2)
        "*/games/THE BROKEN SEAL/SRC/MAP/MAP_085/MAP.o"(.rodata)
        "*/recon/tbs/unidentified.o"(.unidentified.0867773b)
        "*/games/THE BROKEN SEAL/SRC/MAP/MAP_086/MAP.o"(.rodata)
        "*/recon/tbs/unidentified.o"(.unidentified.0867845e)
        "*/games/THE BROKEN SEAL/SRC/GRAPHICS/TILESET/PALETTES/PAL_06.o"(.rodata)
        "*/recon/tbs/unidentified.o"(.unidentified.086785bd)
        "*/games/THE BROKEN SEAL/SRC/MAP/MAP_087/MAP.o"(.rodata)
        "*/recon/tbs/unidentified.o"(.unidentified.08679efa)
        "*/games/THE BROKEN SEAL/SRC/MAP/MAP_088/MAP.o"(.rodata)
        "*/recon/tbs/unidentified.o"(.unidentified.0867bd17)
        "*/games/THE BROKEN SEAL/SRC/GRAPHICS/TILESET/PALETTES/PAL_07.o"(.rodata)
        "*/recon/tbs/unidentified.o"(.unidentified.0867be7a)
        "*/games/THE BROKEN SEAL/SRC/MAP/MAP_089/MAP.o"(.rodata)
        "*/recon/tbs/unidentified.o"(.unidentified.0867f33d)
        "*/games/THE BROKEN SEAL/SRC/MAP/MAP_090/MAP.o"(.rodata)
        "*/recon/tbs/unidentified.o"(.unidentified.08681b5d)
        "*/games/THE BROKEN SEAL/SRC/GRAPHICS/TILESET/SET_50/PALETTE.o"(.rodata)
        "*/games/THE BROKEN SEAL/SRC/GRAPHICS/TILESET/SET_50/TILES_A.o"(.rodata)
        "*/recon/tbs/unidentified.o"(.unidentified.08684543)
        "*/games/THE BROKEN SEAL/SRC/GRAPHICS/TILESET/SET_50/TILES_B.o"(.rodata)
        "*/recon/tbs/unidentified.o"(.unidentified.0868674e)
        "*/games/THE BROKEN SEAL/SRC/GRAPHICS/TILESET/SET_50/TILES_C.o"(.rodata)
        "*/recon/tbs/unidentified.o"(.unidentified.0868688f)
        "*/games/THE BROKEN SEAL/SRC/GRAPHICS/TILESET/SET_50/TILES_D.o"(.rodata)
        "*/recon/tbs/unidentified.o"(.unidentified.086882a6)
        "*/games/THE BROKEN SEAL/SRC/MAP/MAP_091/MAP.o"(.rodata)
        "*/recon/tbs/unidentified.o"(.unidentified.0868a786)
        "*/games/THE BROKEN SEAL/SRC/MAP/MAP_092/MAP.o"(.rodata)
        "*/recon/tbs/unidentified.o"(.unidentified.0868d06e)
        "*/games/THE BROKEN SEAL/SRC/MAP/MAP_093/MAP.o"(.rodata)
        "*/recon/tbs/unidentified.o"(.unidentified.0868f00d)
        "*/games/THE BROKEN SEAL/SRC/GRAPHICS/TILESET/SET_51/PALETTE.o"(.rodata)
        "*/recon/tbs/unidentified.o"(.unidentified.0868f18b)
        "*/games/THE BROKEN SEAL/SRC/GRAPHICS/TILESET/SET_51/TILES_A.o"(.rodata)
        "*/recon/tbs/unidentified.o"(.unidentified.08691135)
        "*/games/THE BROKEN SEAL/SRC/GRAPHICS/TILESET/SET_51/TILES_B.o"(.rodata)
        "*/recon/tbs/unidentified.o"(.unidentified.086938ae)
        "*/games/THE BROKEN SEAL/SRC/GRAPHICS/TILESET/SET_51/TILES_C.o"(.rodata)
        "*/recon/tbs/unidentified.o"(.unidentified.08695115)
        "*/games/THE BROKEN SEAL/SRC/GRAPHICS/TILESET/SET_51/TILES_D.o"(.rodata)
        "*/games/THE BROKEN SEAL/SRC/MAP/MAP_094/MAP.o"(.rodata)
        "*/recon/tbs/unidentified.o"(.unidentified.08698b36)
        "*/games/THE BROKEN SEAL/SRC/GRAPHICS/TILESET/SET_52/PALETTE.o"(.rodata)
        "*/recon/tbs/unidentified.o"(.unidentified.08698cff)
        "*/games/THE BROKEN SEAL/SRC/GRAPHICS/TILESET/SET_52/TILES_A.o"(.rodata)
        "*/games/THE BROKEN SEAL/SRC/GRAPHICS/TILESET/SET_52/TILES_B.o"(.rodata)
        "*/games/THE BROKEN SEAL/SRC/GRAPHICS/TILESET/SET_52/TILES_C.o"(.rodata)
        "*/games/THE BROKEN SEAL/SRC/GRAPHICS/TILESET/SET_52/TILES_D.o"(.rodata)
        "*/games/THE BROKEN SEAL/SRC/MAP/MAP_095/MAP.o"(.rodata)
        "*/recon/tbs/unidentified.o"(.unidentified.086a0dab)
        "*/games/THE BROKEN SEAL/SRC/MAP/MAP_096/MAP.o"(.rodata)
        "*/recon/tbs/unidentified.o"(.unidentified.086a1f23)
        "*/games/THE BROKEN SEAL/SRC/MAP/MAP_097/MAP.o"(.rodata)
        "*/recon/tbs/unidentified.o"(.unidentified.086a3ce7)
        "*/games/THE BROKEN SEAL/SRC/GRAPHICS/TILESET/PALETTES/PAL_08.o"(.rodata)
        "*/games/THE BROKEN SEAL/SRC/MAP/MAP_098/MAP.o"(.rodata)
        "*/recon/tbs/unidentified.o"(.unidentified.086a5e33)
        "*/games/THE BROKEN SEAL/SRC/GRAPHICS/TILESET/SET_53/PALETTE.o"(.rodata)
        "*/recon/tbs/unidentified.o"(.unidentified.086a5fbd)
        "*/games/THE BROKEN SEAL/SRC/GRAPHICS/TILESET/SET_53/TILES_A.o"(.rodata)
        "*/recon/tbs/unidentified.o"(.unidentified.086a7a42)
        "*/games/THE BROKEN SEAL/SRC/GRAPHICS/TILESET/SET_53/TILES_B.o"(.rodata)
        "*/games/THE BROKEN SEAL/SRC/MAP/MAP_099/MAP.o"(.rodata)
        "*/recon/tbs/unidentified.o"(.unidentified.086aaa79)
        "*/games/THE BROKEN SEAL/SRC/GRAPHICS/TILESET/PALETTES/PAL_09.o"(.rodata)
        "*/recon/tbs/unidentified.o"(.unidentified.086aac3f)
        "*/games/THE BROKEN SEAL/SRC/MAP/MAP_100/MAP.o"(.rodata)
        "*/recon/tbs/unidentified.o"(.unidentified.086abb73)
        "*/games/THE BROKEN SEAL/SRC/GRAPHICS/TILESET/PALETTES/PAL_10.o"(.rodata)
        "*/games/THE BROKEN SEAL/SRC/MAP/MAP_101/MAP.o"(.rodata)
        "*/recon/tbs/unidentified.o"(.unidentified.086adc26)
        "*/games/THE BROKEN SEAL/SRC/GRAPHICS/TILESET/SET_54/PALETTE.o"(.rodata)
        "*/recon/tbs/unidentified.o"(.unidentified.086addcd)
        "*/games/THE BROKEN SEAL/SRC/GRAPHICS/TILESET/SET_54/TILES_A.o"(.rodata)
        "*/games/THE BROKEN SEAL/SRC/GRAPHICS/TILESET/SET_54/TILES_B.o"(.rodata)
        "*/recon/tbs/unidentified.o"(.unidentified.086b2df7)
        "*/games/THE BROKEN SEAL/SRC/GRAPHICS/TILESET/SET_54/TILES_C.o"(.rodata)
        "*/games/THE BROKEN SEAL/SRC/MAP/MAP_102/MAP.o"(.rodata)
        "*/recon/tbs/unidentified.o"(.unidentified.086b5b87)
        "*/games/THE BROKEN SEAL/SRC/GRAPHICS/TILESET/SET_55/PALETTE.o"(.rodata)
        "*/recon/tbs/unidentified.o"(.unidentified.086b5d47)
        "*/games/THE BROKEN SEAL/SRC/GRAPHICS/TILESET/SET_55/TILES_A.o"(.rodata)
        "*/games/THE BROKEN SEAL/SRC/MAP/MAP_103/MAP.o"(.rodata)
        "*/recon/tbs/unidentified.o"(.unidentified.086b823b)
        "*/games/THE BROKEN SEAL/SRC/GRAPHICS/TILESET/SET_56/PALETTE.o"(.rodata)
        "*/recon/tbs/unidentified.o"(.unidentified.086b840d)
        "*/games/THE BROKEN SEAL/SRC/GRAPHICS/TILESET/SET_56/TILES_A.o"(.rodata)
        "*/recon/tbs/unidentified.o"(.unidentified.086ba49e)
        "*/games/THE BROKEN SEAL/SRC/GRAPHICS/TILESET/SET_56/TILES_B.o"(.rodata)
        "*/recon/tbs/unidentified.o"(.unidentified.086bc59e)
        "*/games/THE BROKEN SEAL/SRC/GRAPHICS/TILESET/SET_56/TILES_C.o"(.rodata)
        "*/games/THE BROKEN SEAL/SRC/GRAPHICS/TILESET/SET_56/TILES_D.o"(.rodata)
        "*/recon/tbs/unidentified.o"(.unidentified.086bf152)
        "*/games/THE BROKEN SEAL/SRC/MAP/MAP_104/MAP.o"(.rodata)
        "*/recon/tbs/unidentified.o"(.unidentified.086bfc3f)
        "*/games/THE BROKEN SEAL/SRC/GRAPHICS/TILESET/PALETTES/PAL_11.o"(.rodata)
        "*/recon/tbs/unidentified.o"(.unidentified.086bfe12)
        "*/games/THE BROKEN SEAL/SRC/MAP/MAP_105/MAP.o"(.rodata)
        "*/games/THE BROKEN SEAL/SRC/GRAPHICS/TILESET/SET_57/PALETTE.o"(.rodata)
        "*/games/THE BROKEN SEAL/SRC/GRAPHICS/TILESET/SET_57/TILES_A.o"(.rodata)
        "*/recon/tbs/unidentified.o"(.unidentified.086c2741)
        "*/games/THE BROKEN SEAL/SRC/GRAPHICS/TILESET/SET_57/TILES_B.o"(.rodata)
        "*/recon/tbs/unidentified.o"(.unidentified.086c3ed9)
        "*/games/THE BROKEN SEAL/SRC/GRAPHICS/TILESET/SET_57/TILES_C.o"(.rodata)
        "*/recon/tbs/unidentified.o"(.unidentified.086c514d)
        "*/games/THE BROKEN SEAL/SRC/GRAPHICS/TILESET/SET_57/TILES_D.o"(.rodata)
        "*/games/THE BROKEN SEAL/SRC/MAP/MAP_106/MAP.o"(.rodata)
        "*/games/THE BROKEN SEAL/SRC/GRAPHICS/TILESET/PALETTES/PAL_12.o"(.rodata)
        "*/recon/tbs/unidentified.o"(.unidentified.086c75dd)
        "*/games/THE BROKEN SEAL/SRC/MAP/MAP_107/MAP.o"(.rodata)
        "*/games/THE BROKEN SEAL/SRC/GRAPHICS/TILESET/PALETTES/PAL_13.o"(.rodata)
        "*/recon/tbs/unidentified.o"(.unidentified.086c9929)
        "*/games/THE BROKEN SEAL/SRC/MAP/MAP_108/MAP.o"(.rodata)
        "*/recon/tbs/unidentified.o"(.unidentified.086cab13)
        "*/games/THE BROKEN SEAL/SRC/GRAPHICS/TILESET/SET_58/PALETTE.o"(.rodata)
        "*/recon/tbs/unidentified.o"(.unidentified.086cac9a)
        "*/games/THE BROKEN SEAL/SRC/GRAPHICS/TILESET/SET_58/TILES_A.o"(.rodata)
        "*/games/THE BROKEN SEAL/SRC/GRAPHICS/TILESET/SET_58/TILES_B.o"(.rodata)
        "*/recon/tbs/unidentified.o"(.unidentified.086cf1e6)
        "*/games/THE BROKEN SEAL/SRC/GRAPHICS/TILESET/SET_58/TILES_C.o"(.rodata)
        "*/recon/tbs/unidentified.o"(.unidentified.086cf33b)
        "*/games/THE BROKEN SEAL/SRC/GRAPHICS/TILESET/SET_58/TILES_D.o"(.rodata)
        "*/recon/tbs/unidentified.o"(.unidentified.086cf47b)
        "*/games/THE BROKEN SEAL/SRC/MAP/MAP_109/MAP.o"(.rodata)
        "*/recon/tbs/unidentified.o"(.unidentified.086d014f)
        "*/games/THE BROKEN SEAL/SRC/GRAPHICS/TILESET/PALETTES/PAL_14.o"(.rodata)
        "*/recon/tbs/unidentified.o"(.unidentified.086d02ce)
        "*/games/THE BROKEN SEAL/SRC/MAP/MAP_110/MAP.o"(.rodata)
        "*/recon/tbs/unidentified.o"(.unidentified.086d1b87)
        "*/games/THE BROKEN SEAL/SRC/GRAPHICS/TILESET/PALETTES/PAL_15.o"(.rodata)
        "*/recon/tbs/unidentified.o"(.unidentified.086d1d09)
        "*/games/THE BROKEN SEAL/SRC/MAP/MAP_111/MAP.o"(.rodata)
        "*/recon/tbs/unidentified.o"(.unidentified.086d379b)
        "*/games/THE BROKEN SEAL/SRC/GRAPHICS/TILESET/PALETTES/PAL_16.o"(.rodata)
        "*/recon/tbs/unidentified.o"(.unidentified.086d3915)
        "*/games/THE BROKEN SEAL/SRC/MAP/MAP_112/MAP.o"(.rodata)
        "*/recon/tbs/unidentified.o"(.unidentified.086d5653)
        "*/games/THE BROKEN SEAL/SRC/GRAPHICS/TILESET/PALETTES/PAL_17.o"(.rodata)
        "*/recon/tbs/unidentified.o"(.unidentified.086d577f)
        "*/games/THE BROKEN SEAL/SRC/GRAPHICS/TILESET/PALETTES/PAL_18.o"(.rodata)
        "*/recon/tbs/unidentified.o"(.unidentified.086d58f5)
        "*/games/THE BROKEN SEAL/SRC/MAP/MAP_113/MAP.o"(.rodata)
        "*/recon/tbs/unidentified.o"(.unidentified.086d779b)
        "*/games/THE BROKEN SEAL/SRC/GRAPHICS/TILESET/PALETTES/PAL_19.o"(.rodata)
        "*/recon/tbs/unidentified.o"(.unidentified.086d7921)
        "*/games/THE BROKEN SEAL/SRC/MAP/MAP_114/MAP.o"(.rodata)
        "*/recon/tbs/unidentified.o"(.unidentified.086d887f)
        "*/games/THE BROKEN SEAL/SRC/GRAPHICS/TILESET/PALETTES/PAL_20.o"(.rodata)
        "*/games/THE BROKEN SEAL/SRC/MAP/MAP_115/MAP.o"(.rodata)
        "*/recon/tbs/unidentified.o"(.unidentified.086d9b23)
        "*/games/THE BROKEN SEAL/SRC/GRAPHICS/TILESET/PALETTES/PAL_21.o"(.rodata)
        "*/recon/tbs/unidentified.o"(.unidentified.086d9cde)
        "*/games/THE BROKEN SEAL/SRC/MAP/MAP_116/MAP.o"(.rodata)
        "*/recon/tbs/unidentified.o"(.unidentified.086dc782)
        "*/games/THE BROKEN SEAL/SRC/GRAPHICS/TILESET/PALETTES/PAL_22.o"(.rodata)
        "*/recon/tbs/unidentified.o"(.unidentified.086dc8f5)
        "*/games/THE BROKEN SEAL/SRC/MAP/MAP_117/MAP.o"(.rodata)
        "*/recon/tbs/unidentified.o"(.unidentified.086ddcdd)
        "*/games/THE BROKEN SEAL/SRC/GRAPHICS/TILESET/PALETTES/PAL_23.o"(.rodata)
        "*/games/THE BROKEN SEAL/SRC/MAP/MAP_118/MAP.o"(.rodata)
        "*/recon/tbs/unidentified.o"(.unidentified.086e07bd)
        "*/games/THE BROKEN SEAL/SRC/GRAPHICS/TILESET/PALETTES/PAL_24.o"(.rodata)
        "*/recon/tbs/unidentified.o"(.unidentified.086e0967)
        "*/games/THE BROKEN SEAL/SRC/MAP/MAP_119/MAP.o"(.rodata)
        "*/recon/tbs/unidentified.o"(.unidentified.086e2d62)
        "*/games/THE BROKEN SEAL/SRC/GRAPHICS/TILESET/PALETTES/PAL_25.o"(.rodata)
        "*/recon/tbs/unidentified.o"(.unidentified.086e2ef1)
        "*/games/THE BROKEN SEAL/SRC/MAP/MAP_120/MAP.o"(.rodata)
        "*/recon/tbs/unidentified.o"(.unidentified.086e6171)
        "*/games/THE BROKEN SEAL/SRC/GRAPHICS/TILESET/PALETTES/PAL_26.o"(.rodata)
        "*/recon/tbs/unidentified.o"(.unidentified.086e6352)
        "*/games/THE BROKEN SEAL/SRC/MAP/MAP_121/MAP.o"(.rodata)
        "*/recon/tbs/unidentified.o"(.unidentified.086e725f)
        "*/games/THE BROKEN SEAL/SRC/MAP/MAP_122/MAP.o"(.rodata)
        "*/recon/tbs/unidentified.o"(.unidentified.086e88e7)
        "*/games/THE BROKEN SEAL/SRC/GRAPHICS/TILESET/PALETTES/PAL_27.o"(.rodata)
        "*/recon/tbs/unidentified.o"(.unidentified.086e8a76)
        "*/games/THE BROKEN SEAL/SRC/MAP/MAP_123/MAP.o"(.rodata)
        "*/games/THE BROKEN SEAL/SRC/GRAPHICS/TILESET/PALETTES/PAL_28.o"(.rodata)
        "*/recon/tbs/unidentified.o"(.unidentified.086eb66e)
        "*/games/THE BROKEN SEAL/SRC/MAP/MAP_124/MAP.o"(.rodata)
        "*/recon/tbs/unidentified.o"(.unidentified.086ec1bb)
        "*/games/THE BROKEN SEAL/SRC/GRAPHICS/TILESET/SET_59/PALETTE.o"(.rodata)
        "*/recon/tbs/unidentified.o"(.unidentified.086ec322)
        "*/games/THE BROKEN SEAL/SRC/GRAPHICS/TILESET/SET_59/TILES_A.o"(.rodata)
        "*/recon/tbs/unidentified.o"(.unidentified.086eed37)
        "*/games/THE BROKEN SEAL/SRC/GRAPHICS/TILESET/SET_59/TILES_B.o"(.rodata)
        "*/recon/tbs/unidentified.o"(.unidentified.086f0976)
        "*/games/THE BROKEN SEAL/SRC/GRAPHICS/TILESET/SET_59/TILES_C.o"(.rodata)
        "*/recon/tbs/unidentified.o"(.unidentified.086f0e33)
        "*/games/THE BROKEN SEAL/SRC/GRAPHICS/TILESET/SET_59/TILES_D.o"(.rodata)
        "*/recon/tbs/unidentified.o"(.unidentified.086f21ab)
        "*/games/THE BROKEN SEAL/SRC/MAP/MAP_125/MAP.o"(.rodata)
        "*/recon/tbs/unidentified.o"(.unidentified.086f36ef)
        "*/games/THE BROKEN SEAL/SRC/GRAPHICS/TILESET/PALETTES/PAL_29.o"(.rodata)
        "*/recon/tbs/unidentified.o"(.unidentified.086f3879)
        "*/games/THE BROKEN SEAL/SRC/MAP/MAP_126/MAP.o"(.rodata)
        "*/recon/tbs/unidentified.o"(.unidentified.086f4957)
        "*/games/THE BROKEN SEAL/SRC/GRAPHICS/TILESET/PALETTES/PAL_30.o"(.rodata)
        "*/recon/tbs/unidentified.o"(.unidentified.086f4ae5)
        "*/games/THE BROKEN SEAL/SRC/MAP/MAP_127/MAP.o"(.rodata)
        "*/games/THE BROKEN SEAL/SRC/GRAPHICS/TILESET/SET_60/PALETTE.o"(.rodata)
        "*/recon/tbs/unidentified.o"(.unidentified.086f6739)
        "*/games/THE BROKEN SEAL/SRC/GRAPHICS/TILESET/SET_60/TILES_A.o"(.rodata)
        "*/recon/tbs/unidentified.o"(.unidentified.086f911b)
        "*/games/THE BROKEN SEAL/SRC/GRAPHICS/TILESET/SET_60/TILES_B.o"(.rodata)
        "*/games/THE BROKEN SEAL/SRC/GRAPHICS/TILESET/SET_60/TILES_C.o"(.rodata)
        "*/recon/tbs/unidentified.o"(.unidentified.086fc645)
        "*/games/THE BROKEN SEAL/SRC/GRAPHICS/TILESET/SET_60/TILES_D.o"(.rodata)
        "*/recon/tbs/unidentified.o"(.unidentified.086fdf4f)
        "*/games/THE BROKEN SEAL/SRC/MAP/MAP_128/MAP.o"(.rodata)
        "*/recon/tbs/unidentified.o"(.unidentified.086ffff7)
        "*/games/THE BROKEN SEAL/SRC/GRAPHICS/TILESET/SET_61/PALETTE.o"(.rodata)
        "*/games/THE BROKEN SEAL/SRC/GRAPHICS/TILESET/SET_61/TILES_A.o"(.rodata)
        "*/recon/tbs/unidentified.o"(.unidentified.08702a4b)
        "*/games/THE BROKEN SEAL/SRC/GRAPHICS/TILESET/SET_61/TILES_B.o"(.rodata)
        "*/recon/tbs/unidentified.o"(.unidentified.08704697)
        "*/games/THE BROKEN SEAL/SRC/GRAPHICS/TILESET/SET_61/TILES_C.o"(.rodata)
        "*/recon/tbs/unidentified.o"(.unidentified.08705add)
        "*/games/THE BROKEN SEAL/SRC/GRAPHICS/TILESET/SET_61/TILES_D.o"(.rodata)
        "*/recon/tbs/unidentified.o"(.unidentified.0870795d)
        "*/games/THE BROKEN SEAL/SRC/MAP/MAP_129/MAP.o"(.rodata)
        "*/games/THE BROKEN SEAL/SRC/GRAPHICS/TILESET/SET_62/PALETTE.o"(.rodata)
        "*/recon/tbs/unidentified.o"(.unidentified.0870952e)
        "*/games/THE BROKEN SEAL/SRC/GRAPHICS/TILESET/SET_62/TILES_A.o"(.rodata)
        "*/recon/tbs/unidentified.o"(.unidentified.0870bc62)
        "*/games/THE BROKEN SEAL/SRC/GRAPHICS/TILESET/SET_62/TILES_B.o"(.rodata)
        "*/recon/tbs/unidentified.o"(.unidentified.0870d8a7)
        "*/games/THE BROKEN SEAL/SRC/GRAPHICS/TILESET/SET_62/TILES_C.o"(.rodata)
        "*/recon/tbs/unidentified.o"(.unidentified.0870eced)
        "*/games/THE BROKEN SEAL/SRC/GRAPHICS/TILESET/SET_62/TILES_D.o"(.rodata)
        "*/recon/tbs/unidentified.o"(.unidentified.0871086b)
        "*/games/THE BROKEN SEAL/SRC/MAP/MAP_130/MAP.o"(.rodata)
        "*/recon/tbs/unidentified.o"(.unidentified.08711a9b)
        "*/games/THE BROKEN SEAL/SRC/GRAPHICS/TILESET/PALETTES/PAL_31.o"(.rodata)
        "*/recon/tbs/unidentified.o"(.unidentified.08711bf5)
        "*/games/THE BROKEN SEAL/SRC/MAP/MAP_131/MAP.o"(.rodata)
        "*/recon/tbs/unidentified.o"(.unidentified.08712b9e)
        "*/games/THE BROKEN SEAL/SRC/MAP/MAP_132/MAP.o"(.rodata)
        "*/recon/tbs/unidentified.o"(.unidentified.0871421a)
        "*/games/THE BROKEN SEAL/SRC/MAP/MAP_133/MAP.o"(.rodata)
        "*/recon/tbs/unidentified.o"(.unidentified.087150f3)
        "*/games/THE BROKEN SEAL/SRC/GRAPHICS/TILESET/PALETTES/PAL_32.o"(.rodata)
        "*/recon/tbs/unidentified.o"(.unidentified.0871525e)
        "*/games/THE BROKEN SEAL/SRC/MAP/MAP_134/MAP.o"(.rodata)
        "*/recon/tbs/unidentified.o"(.unidentified.08716c16)
        "*/games/THE BROKEN SEAL/SRC/MAP/MAP_135/MAP.o"(.rodata)
        "*/recon/tbs/unidentified.o"(.unidentified.08717b8a)
        "*/recon/tbs/unidentified.o"(.unidentified.08717b8c)
        "*/games/THE BROKEN SEAL/SRC/GRAPHICS/TILESET/PALETTES/PAL_33.o"(.rodata)
        "*/games/THE BROKEN SEAL/SRC/MAP/MAP_136/MAP.o"(.rodata)
        "*/recon/tbs/unidentified.o"(.unidentified.0871a4d5)
        "*/games/THE BROKEN SEAL/SRC/GRAPHICS/TILESET/PALETTES/PAL_34.o"(.rodata)
        "*/games/THE BROKEN SEAL/SRC/MAP/MAP_137/MAP.o"(.rodata)
        "*/recon/tbs/unidentified.o"(.unidentified.0871c3d3)
        "*/games/THE BROKEN SEAL/SRC/MAP/MAP_138/MAP.o"(.rodata)
        "*/recon/tbs/unidentified.o"(.unidentified.0871d71b)
        "*/games/THE BROKEN SEAL/SRC/GRAPHICS/TILESET/PALETTES/PAL_35.o"(.rodata)
        "*/games/THE BROKEN SEAL/SRC/MAP/MAP_139/MAP.o"(.rodata)
        "*/recon/tbs/unidentified.o"(.unidentified.08720012)
        "*/games/THE BROKEN SEAL/SRC/GRAPHICS/TILESET/PALETTES/PAL_36.o"(.rodata)
        "*/games/THE BROKEN SEAL/SRC/MAP/MAP_140/MAP.o"(.rodata)
        "*/recon/tbs/unidentified.o"(.unidentified.08722b97)
        "*/games/THE BROKEN SEAL/SRC/MAP/MAP_141/MAP.o"(.rodata)
        "*/recon/tbs/unidentified.o"(.unidentified.08723f83)
        "*/games/THE BROKEN SEAL/SRC/MAP/MAP_142/MAP.o"(.rodata)
        "*/recon/tbs/unidentified.o"(.unidentified.0872548a)
        "*/games/THE BROKEN SEAL/SRC/MAP/MAP_143/MAP.o"(.rodata)
        "*/recon/tbs/unidentified.o"(.unidentified.0872934b)
        "*/games/THE BROKEN SEAL/SRC/GRAPHICS/TILESET/PALETTES/PAL_37.o"(.rodata)
        "*/games/THE BROKEN SEAL/SRC/MAP/MAP_144/MAP.o"(.rodata)
        "*/recon/tbs/unidentified.o"(.unidentified.0872a67a)
        "*/games/THE BROKEN SEAL/SRC/GRAPHICS/TILESET/PALETTES/PAL_38.o"(.rodata)
        "*/games/THE BROKEN SEAL/SRC/MAP/MAP_145/MAP.o"(.rodata)
        "*/recon/tbs/unidentified.o"(.unidentified.0872b873)
        "*/games/THE BROKEN SEAL/SRC/GRAPHICS/TILESET/SET_63/PALETTE.o"(.rodata)
        "*/recon/tbs/unidentified.o"(.unidentified.0872b9d5)
        "*/games/THE BROKEN SEAL/SRC/GRAPHICS/TILESET/SET_63/TILES_A.o"(.rodata)
        "*/recon/tbs/unidentified.o"(.unidentified.0872e3a1)
        "*/games/THE BROKEN SEAL/SRC/MAP/MAP_146/MAP.o"(.rodata)
        "*/games/THE BROKEN SEAL/SRC/MAP/MAP_147/MAP.o"(.rodata)
        "*/recon/tbs/unidentified.o"(.unidentified.087318cd)
        "*/games/THE BROKEN SEAL/SRC/GRAPHICS/TILESET/PALETTES/PAL_39.o"(.rodata)
        "*/games/THE BROKEN SEAL/SRC/MAP/MAP_148/MAP.o"(.rodata)
        "*/games/THE BROKEN SEAL/SRC/MAP/MAP_149/MAP.o"(.rodata)
        "*/recon/tbs/unidentified.o"(.unidentified.08735d0f)
        "*/games/THE BROKEN SEAL/SRC/GRAPHICS/TILESET/PALETTES/PAL_40.o"(.rodata)
        "*/recon/tbs/unidentified.o"(.unidentified.08735e82)
        "*/games/THE BROKEN SEAL/SRC/MAP/MAP_150/MAP.o"(.rodata)
        "*/games/THE BROKEN SEAL/SRC/GRAPHICS/TILESET/SET_64/PALETTE.o"(.rodata)
        "*/games/THE BROKEN SEAL/SRC/GRAPHICS/TILESET/SET_64/TILES_A.o"(.rodata)
        "*/recon/tbs/unidentified.o"(.unidentified.0873a0e7)
        "*/games/THE BROKEN SEAL/SRC/GRAPHICS/TILESET/SET_64/TILES_B.o"(.rodata)
        "*/games/THE BROKEN SEAL/SRC/GRAPHICS/TILESET/SET_64/TILES_C.o"(.rodata)
        "*/recon/tbs/unidentified.o"(.unidentified.0873d902)
        "*/games/THE BROKEN SEAL/SRC/GRAPHICS/TILESET/SET_64/TILES_D.o"(.rodata)
        "*/recon/tbs/unidentified.o"(.unidentified.0873f32a)
        "*/games/THE BROKEN SEAL/SRC/MAP/MAP_151/MAP.o"(.rodata)
        "*/recon/tbs/unidentified.o"(.unidentified.087419d7)
        "*/games/THE BROKEN SEAL/SRC/GRAPHICS/TILESET/SET_65/PALETTE.o"(.rodata)
        "*/games/THE BROKEN SEAL/SRC/GRAPHICS/TILESET/SET_65/TILES_A.o"(.rodata)
        "*/recon/tbs/unidentified.o"(.unidentified.08743a3b)
        "*/games/THE BROKEN SEAL/SRC/GRAPHICS/TILESET/SET_65/TILES_B.o"(.rodata)
        "*/recon/tbs/unidentified.o"(.unidentified.087458f7)
        "*/games/THE BROKEN SEAL/SRC/GRAPHICS/TILESET/SET_65/TILES_C.o"(.rodata)
        "*/games/THE BROKEN SEAL/SRC/GRAPHICS/TILESET/SET_65/TILES_D.o"(.rodata)
        "*/recon/tbs/unidentified.o"(.unidentified.08748b41)
        "*/games/THE BROKEN SEAL/SRC/MAP/MAP_152/MAP.o"(.rodata)
        "*/recon/tbs/unidentified.o"(.unidentified.0874a503)
        "*/games/THE BROKEN SEAL/SRC/GRAPHICS/TILESET/PALETTES/PAL_41.o"(.rodata)
        "*/recon/tbs/unidentified.o"(.unidentified.0874a675)
        "*/games/THE BROKEN SEAL/SRC/MAP/MAP_153/MAP.o"(.rodata)
        "*/recon/tbs/unidentified.o"(.unidentified.0874bde6)
        "*/games/THE BROKEN SEAL/SRC/MAP/MAP_154/MAP.o"(.rodata)
        "*/recon/tbs/unidentified.o"(.unidentified.0874d682)
        "*/games/THE BROKEN SEAL/SRC/GRAPHICS/TILESET/PALETTES/PAL_42.o"(.rodata)
        "*/recon/tbs/unidentified.o"(.unidentified.0874d83a)
        "*/games/THE BROKEN SEAL/SRC/MAP/MAP_155/MAP.o"(.rodata)
        "*/recon/tbs/unidentified.o"(.unidentified.0874f0ab)
        "*/games/THE BROKEN SEAL/SRC/GRAPHICS/TILESET/PALETTES/PAL_43.o"(.rodata)
        "*/recon/tbs/unidentified.o"(.unidentified.0874f22a)
        "*/games/THE BROKEN SEAL/SRC/MAP/MAP_156/MAP.o"(.rodata)
        "*/recon/tbs/unidentified.o"(.unidentified.08750b55)
        "*/games/THE BROKEN SEAL/SRC/MAP/MAP_157/MAP.o"(.rodata)
        "*/recon/tbs/unidentified.o"(.unidentified.08752a33)
        "*/games/THE BROKEN SEAL/SRC/GRAPHICS/TILESET/PALETTES/PAL_44.o"(.rodata)
        "*/recon/tbs/unidentified.o"(.unidentified.08752ba7)
        "*/games/THE BROKEN SEAL/SRC/GRAPHICS/TILESET/PALETTES/PAL_45.o"(.rodata)
        "*/games/THE BROKEN SEAL/SRC/MAP/MAP_158/MAP.o"(.rodata)
        "*/recon/tbs/unidentified.o"(.unidentified.0875396f)
        "*/games/THE BROKEN SEAL/SRC/GRAPHICS/TILESET/PALETTES/PAL_46.o"(.rodata)
        "*/recon/tbs/unidentified.o"(.unidentified.08753b15)
        "*/games/THE BROKEN SEAL/SRC/MAP/MAP_159/MAP.o"(.rodata)
        "*/games/THE BROKEN SEAL/SRC/GRAPHICS/TILESET/PALETTES/PAL_47.o"(.rodata)
        "*/games/THE BROKEN SEAL/SRC/MAP/MAP_160/MAP.o"(.rodata)
        "*/recon/tbs/unidentified.o"(.unidentified.08758953)
        "*/games/THE BROKEN SEAL/SRC/GRAPHICS/TILESET/PALETTES/PAL_48.o"(.rodata)
        "*/recon/tbs/unidentified.o"(.unidentified.08758b3a)
        "*/games/THE BROKEN SEAL/SRC/MAP/MAP_161/MAP.o"(.rodata)
        "*/recon/tbs/unidentified.o"(.unidentified.0875b137)
        "*/games/THE BROKEN SEAL/SRC/MAP/MAP_162/MAP.o"(.rodata)
        "*/recon/tbs/unidentified.o"(.unidentified.0875bdd6)
        "*/recon/tbs/unidentified.o"(.unidentified.0875bdd8)
        "*/games/THE BROKEN SEAL/SRC/GRAPHICS/TILESET/PALETTES/PAL_49.o"(.rodata)
        "*/recon/tbs/unidentified.o"(.unidentified.087604e2)
        "*/games/THE BROKEN SEAL/SRC/MAP/MAP_163/MAP.o"(.rodata)
        "*/recon/tbs/unidentified.o"(.unidentified.087620b5)
        "*/games/THE BROKEN SEAL/SRC/GRAPHICS/TILESET/PALETTES/PAL_50.o"(.rodata)
        "*/games/THE BROKEN SEAL/SRC/MAP/MAP_164/MAP.o"(.rodata)
        "*/recon/tbs/unidentified.o"(.unidentified.08763b65)
        "*/games/THE BROKEN SEAL/SRC/GRAPHICS/TILESET/PALETTES/PAL_51.o"(.rodata)
        "*/recon/tbs/unidentified.o"(.unidentified.08763cc1)
        "*/games/THE BROKEN SEAL/SRC/MAP/MAP_165/MAP.o"(.rodata)
        "*/recon/tbs/unidentified.o"(.unidentified.0876519f)
        "*/games/THE BROKEN SEAL/SRC/MAP/MAP_166/MAP.o"(.rodata)
        "*/recon/tbs/unidentified.o"(.unidentified.087666ee)
        "*/games/THE BROKEN SEAL/SRC/MAP/MAP_167/MAP.o"(.rodata)
        "*/recon/tbs/unidentified.o"(.unidentified.087685b1)
        "*/games/THE BROKEN SEAL/SRC/MAP/MAP_168/MAP.o"(.rodata)
        "*/recon/tbs/unidentified.o"(.unidentified.08769f07)
        "*/games/THE BROKEN SEAL/SRC/GRAPHICS/TILESET/PALETTES/PAL_52.o"(.rodata)
        "*/recon/tbs/unidentified.o"(.unidentified.0876a00b)
        "*/games/THE BROKEN SEAL/SRC/MAP/MAP_169/MAP.o"(.rodata)
        "*/recon/tbs/unidentified.o"(.unidentified.0876aa27)
        "*/games/THE BROKEN SEAL/SRC/GRAPHICS/TILESET/SET_66/PALETTE.o"(.rodata)
        "*/recon/tbs/unidentified.o"(.unidentified.0876ab0d)
        "*/games/THE BROKEN SEAL/SRC/GRAPHICS/TILESET/SET_66/TILES_A.o"(.rodata)
        "*/recon/tbs/unidentified.o"(.unidentified.0876ada9)
        "*/games/THE BROKEN SEAL/SRC/GRAPHICS/TILESET/SET_66/TILES_B.o"(.rodata)
        "*/games/THE BROKEN SEAL/SRC/GRAPHICS/TILESET/SET_66/TILES_C.o"(.rodata)
        "*/recon/tbs/unidentified.o"(.unidentified.0876ee06)
        "*/games/THE BROKEN SEAL/SRC/GRAPHICS/TILESET/SET_66/TILES_D.o"(.rodata)
        "*/recon/tbs/unidentified.o"(.unidentified.0876f3ba)
        "*/games/THE BROKEN SEAL/SRC/MAP/MAP_170/MAP.o"(.rodata)
        "*/recon/tbs/unidentified.o"(.unidentified.0877034f)
        "*/games/THE BROKEN SEAL/SRC/GRAPHICS/TILESET/SET_67/PALETTE.o"(.rodata)
        "*/games/THE BROKEN SEAL/SRC/GRAPHICS/TILESET/SET_67/TILES_A.o"(.rodata)
        "*/recon/tbs/unidentified.o"(.unidentified.08771d52)
        "*/games/THE BROKEN SEAL/SRC/GRAPHICS/TILESET/SET_67/TILES_B.o"(.rodata)
        "*/recon/tbs/unidentified.o"(.unidentified.087729c1)
        "*/games/THE BROKEN SEAL/SRC/GRAPHICS/TILESET/SET_67/TILES_C.o"(.rodata)
        "*/recon/tbs/unidentified.o"(.unidentified.08772c69)
        "*/games/THE BROKEN SEAL/SRC/GRAPHICS/TILESET/SET_67/TILES_D.o"(.rodata)
        "*/recon/tbs/unidentified.o"(.unidentified.08773aee)
        "*/games/THE BROKEN SEAL/SRC/MAP/MAP_171/MAP.o"(.rodata)
        "*/recon/tbs/unidentified.o"(.unidentified.08774c7f)
        "*/games/THE BROKEN SEAL/SRC/GRAPHICS/TILESET/PALETTES/PAL_53.o"(.rodata)
        "*/recon/tbs/unidentified.o"(.unidentified.08774e47)
        "*/games/THE BROKEN SEAL/SRC/MAP/MAP_172/MAP.o"(.rodata)
        "*/recon/tbs/unidentified.o"(.unidentified.08775193)
        "*/recon/tbs/unidentified.o"(.unidentified.08775194)
        "*/games/THE BROKEN SEAL/SRC/MAP/MAP_173/MAP.o"(.rodata)
        "*/recon/tbs/unidentified.o"(.unidentified.087759fb)
        "*/recon/tbs/unidentified.o"(.unidentified.087759fc)
        "*/games/THE BROKEN SEAL/SRC/MAP/MAP_174/MAP.o"(.rodata)
        "*/recon/tbs/unidentified.o"(.unidentified.08776263)
        "*/recon/tbs/unidentified.o"(.unidentified.08776264)
        "*/games/THE BROKEN SEAL/SRC/MAP/MAP_175/MAP.o"(.rodata)
        "*/recon/tbs/unidentified.o"(.unidentified.08776acb)
        "*/recon/tbs/unidentified.o"(.unidentified.08776acc)
        "*/games/THE BROKEN SEAL/SRC/MAP/MAP_176/MAP.o"(.rodata)
        "*/recon/tbs/unidentified.o"(.unidentified.08777333)
        "*/recon/tbs/unidentified.o"(.unidentified.08777334)
        "*/games/THE BROKEN SEAL/SRC/MAP/MAP_177/MAP.o"(.rodata)
        "*/recon/tbs/unidentified.o"(.unidentified.08777b9b)
        "*/recon/tbs/unidentified.o"(.unidentified.08777b9c)
        "*/games/THE BROKEN SEAL/SRC/MAP/MAP_178/MAP.o"(.rodata)
        "*/recon/tbs/unidentified.o"(.unidentified.08778403)
        "*/recon/tbs/unidentified.o"(.unidentified.08778404)
        "*/games/THE BROKEN SEAL/SRC/MAP/MAP_179/MAP.o"(.rodata)
        "*/recon/tbs/unidentified.o"(.unidentified.08778c6b)
        "*/recon/tbs/unidentified.o"(.unidentified.08778c6c)
        "*/recon/tbs/overlays.o"(.overlays)
        "*/recon/tbs/unidentified.o"(.unidentified.087fd4b9)
    } > ROM
    /* Field services that shared overlay C calls through its import veneers are
       the far entries themselves in the main image (SPAWN.C links here too):
       each overlay veneer targets that very entry, so one name cannot serve
       both. */
    Engine_ObjectCreate = Object_CreateFar;
    Engine_ObjectSetScript = ObjectDispatch_InitializeFar;
    /* The compiler calls its division helpers by their ABI names; here they are
       the veneers into the resident IWRAM divider (DIVISION_ENTRY.S). */
    __divsi3 = IwramSignedDivideEntry;
    __udivsi3 = IwramUnsignedDivideEntry;
    __modsi3 = IwramSignedRemainderEntry;
    __umodsi3 = IwramUnsignedRemainderEntry;
    /* FAKEMATCH aliases: LOAD_TABLE_ENTRY.C names one table four ways. */
    RenderResource_PairSourceTable2 = RenderResource_PairSourceTable;
    RenderResource_PairSourceTable3 = RenderResource_PairSourceTable;
    RenderResource_PairSourceTable4 = RenderResource_PairSourceTable;
    /* Startup copies the resident runtime bank to IWRAM from its ROM image. */
    IwramRuntime_Rom = LOADADDR(.iwram_runtime);
    /* The sound mixer runs in IWRAM; its ROM copy is called in place for its return trampoline. */
    Sound_Mixer = LOADADDR(.iwram_mixer) + 1;
    Mixer_CallViaR3Rom = LOADADDR(.iwram_mixer) + (Mixer_CallViaR3 - ADDR(.iwram_mixer));
    /DISCARD/ : { *(.ARM.attributes) *(.comment) *(.note*) }
}
